VERSION ""

NS_ :

BS_:

BU_: Tester BMS VCU MCU_R MCU_F PDU_DCDC OBC IMM
VAL_TABLE_ TorqBndryETractSys2EmNCtrlMin 4093 "Func_interface_is_not_avail" 4094 "Function_reports_error" 4095 "Signal_unfilled" ;
VAL_TABLE_ TorqBndryETractSys2EmNCtrlMax 4093 "Func_interface_is_not_avail" 4094 "Function_reports_error" 4095 "Signal_unfilled" ;
VAL_TABLE_ TorqBndryETractSys1EmNCtrlMin 4093 "Func_interface_is_not_avail" 4094 "Function_reports_error" 4095 "Signal_unfilled" ;
VAL_TABLE_ TorqBndryETractSys1EmNCtrlMax 4093 "Func_interface_is_not_avail" 4094 "Function_reports_error" 4095 "Signal_unfilled" ;
VAL_TABLE_ QU_CurrDrctCurrETractSys1ActVal 1 "value_valid_highest_quality" 2 "value_valid_simple_quality" 3 "Value_valid_restricted" 4 "Value_valid_substitute value" 6 "value_not_available_error" 9 "value_valid_medium_quality" 14 "value_not_available" 15 "signal_invalid" ;
VAL_TABLE_ QualifierRpmEmETractSys1ActVal 1 "value_valid_highest_quality" 2 "value_valid_simple_quality" 3 "Value_valid_restricted" 4 "Value_valid_substitute value" 6 "value_not_available_error" 9 "value_valid_medium_quality" 14 "value_not_available" 15 "signal_invalid" ;
VAL_TABLE_ QualifierTqEmETractSys1ActVal 1 "value_valid_highest_quality" 2 "value_valid_simple_quality" 3 "Value_valid_restricted" 4 "Value_valid_substitute value" 6 "value_not_available_error" 9 "value_valid_medium_quality" 14 "value_not_available" 15 "signal_invalid" ;
VAL_TABLE_ OVCUrrenceStatorPWMETractSys1 0 "Effective_PWM_applied" 1 "No_effective_PWM_applied" 3 "signal_unfilled" ;
VAL_TABLE_ TqEmETractSys1MotorSumLimTarget 4093 "Func_interface_is_not_avail" 4094 "Function_reports_error" 4095 "Signal_unfilled" ;
VAL_TABLE_ TorqueEmETractSys1MotorDynamic 4093 "Func_interface_is_not_avail" 4094 "Function_reports_error" 4095 "Signal_unfilled" ;
VAL_TABLE_ TorqueEmETractSys1MotorStatic 4093 "Func_interface_is_not_avail" 4094 "Function_reports_error" 4095 "Signal_unfilled" ;
VAL_TABLE_ TqEmETractSys1GeneratorDynamic 4093 "Func_interface_is_not_avail" 4094 "Function_reports_error" 4095 "Signal_unfilled" ;
VAL_TABLE_ TqEmETractSys1GeneratorStatic 4093 "Func_interface_is_not_avail" 4094 "Function_reports_error" 4095 "Signal_unfilled" ;
VAL_TABLE_ TqEmETractSys1VibrationDampSusp 4093 "Func_interface_is_not_avail" 4094 "Function_reports_error" 4095 "Signal_unfilled" ;
VAL_TABLE_ CurrDrctCurrETractSys1ActVal 65533 "Func_interface_is_not_avail" 65534 "Function_reports_error" 65535 "Signal_unfilled" ;
VAL_TABLE_ QualifierRpmEmETractSys2ActVal 1 "value_valid_highest_quality" 2 "value_valid_simple_quality" 3 "Value_valid_restricted" 4 "Value_valid_substitute value" 6 "value_not_available_error" 9 "value_valid_medium_quality" 14 "value_not_available" 15 "signal_invalid" ;
VAL_TABLE_ TqEmETractSys2MotorSumLimTarget 4093 "Func_interface_is_not_avail" 4094 "Function_reports_error" 4095 "Signal_unfilled" ;
VAL_TABLE_ TorqueEmETractSys2MotorDynamic 4093 "Func_interface_is_not_avail" 4094 "Function_reports_error" 4095 "Signal_unfilled" ;
VAL_TABLE_ TqEmETractSys2GeneratorDynamic 4093 "Func_interface_is_not_avail" 4094 "Function_reports_error" 4095 "Signal_unfilled" ;
VAL_TABLE_ TqEmETractSys2GeneratorStatic 4093 "Func_interface_is_not_avail" 4094 "Function_reports_error" 4095 "Signal_unfilled" ;
VAL_TABLE_ TqEmETractSys2VibrationDampSusp 4093 "Func_interface_is_not_avail" 4094 "Function_reports_error" 4095 "Signal_unfilled" ;
VAL_TABLE_ CurrDrctCurrETractSys2ActVal 65533 "Func_interface_is_not_avail" 65534 "Function_reports_error" 65535 "Signal_unfilled" ;
VAL_TABLE_ TorqueEmETractSys2MotorStatic 4093 "Func_interface_is_not_avail" 4094 "Function_reports_error" 4095 "Signal_unfilled" ;
VAL_TABLE_ QualifierTqEmETractSys2ActVal 1 "value_valid_highest_quality" 2 "value_valid_simple_quality" 3 "Value_valid_restricted" 4 "Value_valid_substitute value" 6 "value_not_available_error" 9 "value_valid_medium_quality" 14 "value_not_available" 15 "signal_invalid" ;
VAL_TABLE_ OVCUrrenceStatorPWMETractSys2 0 "Effective_PWM_applied" 1 "No_effective_PWM_applied" 3 "signal_unfilled" ;
VAL_TABLE_ QU_CurrDrctCurrETractSys2ActVal 1 "value_valid_highest_quality" 2 "value_valid_simple_quality" 3 "Value_valid_restricted" 4 "Value_valid_substitute value" 6 "value_not_available_error" 9 "value_valid_medium_quality" 14 "value_not_available" 15 "signal_invalid" ;
VAL_TABLE_ PrcntUsedExtraBoostETractSys1 1021 "Func_interface_is_not_avail" 1022 "Function_reports_error" 1023 "Signal_unfilled" ;
VAL_TABLE_ WhlRatElAxlEtractSys1ActVal 65533 "Func_interface_is_not_avail" 65534 "Function_reports_error" 65535 "signal_unfilled" ;
VAL_TABLE_ WhlRatElAxlEtractSys2ActVal 65533 "Func_interface_is_not_avail" 65534 "Function_reports_error" 65535 "signal_unfilled" ;
VAL_TABLE_ PrcntUsedExtraBoostETractSys2 1021 "Func_interface_is_not_avail" 1022 "Function_reports_error" 1023 "Signal_unfilled" ;

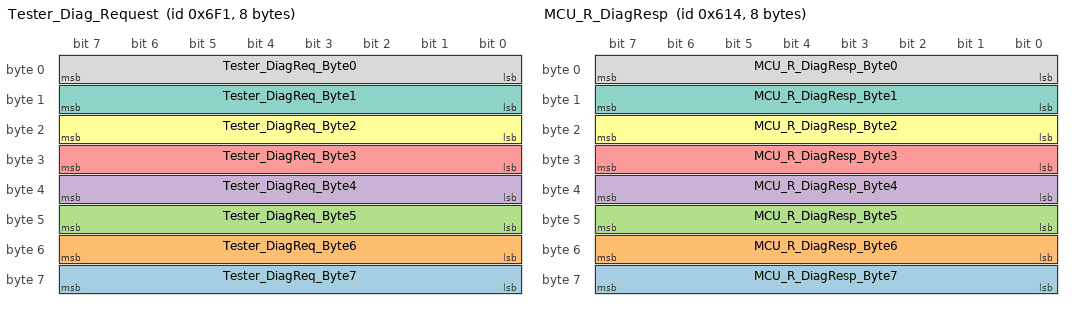
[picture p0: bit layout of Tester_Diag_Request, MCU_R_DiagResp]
BO_ 1777 Tester_Diag_Request: 8 Tester
 SG_ Tester_DiagReq_Byte7 : 56|8@1+ (1,0) [0|255] ""  MCU_R,MCU_F
 SG_ Tester_DiagReq_Byte6 : 48|8@1+ (1,0) [0|255] ""  MCU_R,MCU_F
 SG_ Tester_DiagReq_Byte5 : 40|8@1+ (1,0) [0|255] ""  MCU_R,MCU_F
 SG_ Tester_DiagReq_Byte4 : 32|8@1+ (1,0) [0|255] ""  MCU_R,MCU_F
 SG_ Tester_DiagReq_Byte3 : 24|8@1+ (1,0) [0|255] ""  MCU_R,MCU_F
 SG_ Tester_DiagReq_Byte2 : 16|8@1+ (1,0) [0|255] ""  MCU_R,MCU_F
 SG_ Tester_DiagReq_Byte1 : 8|8@1+ (1,0) [0|255] ""  MCU_R,MCU_F
 SG_ Tester_DiagReq_Byte0 : 0|8@1+ (1,0) [0|255] ""  MCU_R,MCU_F

BO_ 1556 MCU_R_DiagResp: 8 MCU_R
 SG_ MCU_R_DiagResp_Byte7 : 56|8@1+ (1,0) [0|255] ""  Tester
 SG_ MCU_R_DiagResp_Byte6 : 48|8@1+ (1,0) [0|255] ""  Tester
 SG_ MCU_R_DiagResp_Byte5 : 40|8@1+ (1,0) [0|255] ""  Tester
 SG_ MCU_R_DiagResp_Byte4 : 32|8@1+ (1,0) [0|255] ""  Tester
 SG_ MCU_R_DiagResp_Byte3 : 24|8@1+ (1,0) [0|255] ""  Tester
 SG_ MCU_R_DiagResp_Byte2 : 16|8@1+ (1,0) [0|255] ""  Tester
 SG_ MCU_R_DiagResp_Byte1 : 8|8@1+ (1,0) [0|255] ""  Tester
 SG_ MCU_R_DiagResp_Byte0 : 0|8@1+ (1,0) [0|255] ""  Tester

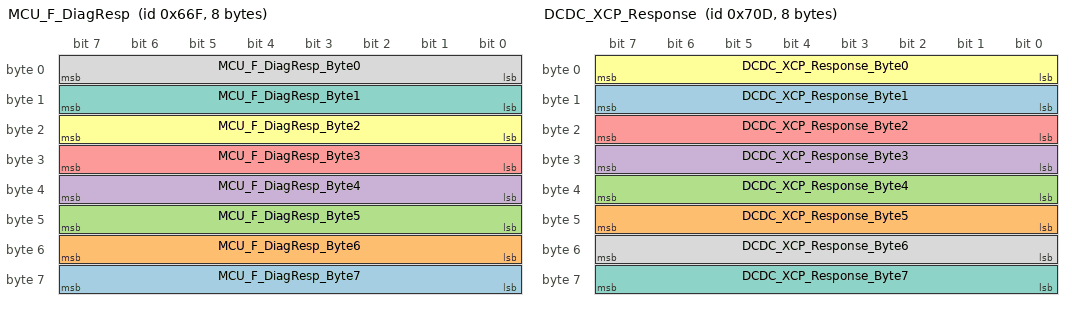
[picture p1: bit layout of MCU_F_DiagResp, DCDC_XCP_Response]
BO_ 1647 MCU_F_DiagResp: 8 MCU_F
 SG_ MCU_F_DiagResp_Byte7 : 56|8@1+ (1,0) [0|255] ""  Tester
 SG_ MCU_F_DiagResp_Byte6 : 48|8@1+ (1,0) [0|255] ""  Tester
 SG_ MCU_F_DiagResp_Byte5 : 40|8@1+ (1,0) [0|255] ""  Tester
 SG_ MCU_F_DiagResp_Byte4 : 32|8@1+ (1,0) [0|255] ""  Tester
 SG_ MCU_F_DiagResp_Byte3 : 24|8@1+ (1,0) [0|255] ""  Tester
 SG_ MCU_F_DiagResp_Byte2 : 16|8@1+ (1,0) [0|255] ""  Tester
 SG_ MCU_F_DiagResp_Byte1 : 8|8@1+ (1,0) [0|255] ""  Tester
 SG_ MCU_F_DiagResp_Byte0 : 0|8@1+ (1,0) [0|255] ""  Tester

BO_ 1805 DCDC_XCP_Response: 8 PDU_DCDC
 SG_ DCDC_XCP_Response_Byte1 : 8|8@1+ (1,0) [0|255] ""  Tester
 SG_ DCDC_XCP_Response_Byte5 : 40|8@1+ (1,0) [0|255] ""  Tester
 SG_ DCDC_XCP_Response_Byte4 : 32|8@1+ (1,0) [0|255] ""  Tester
 SG_ DCDC_XCP_Response_Byte3 : 24|8@1+ (1,0) [0|255] ""  Tester
 SG_ DCDC_XCP_Response_Byte2 : 16|8@1+ (1,0) [0|255] ""  Tester
 SG_ DCDC_XCP_Response_Byte0 : 0|8@1+ (1,0) [0|255] ""  Tester
 SG_ DCDC_XCP_Response_Byte7 : 56|8@1+ (1,0) [0|255] ""  Tester
 SG_ DCDC_XCP_Response_Byte6 : 48|8@1+ (1,0) [0|255] ""  Tester

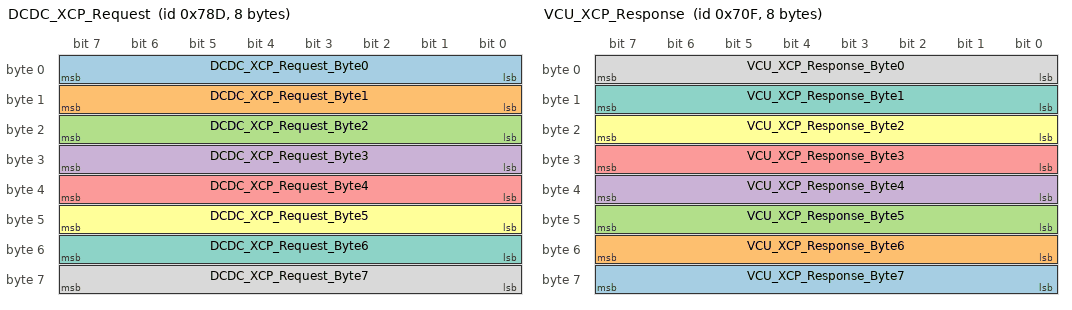
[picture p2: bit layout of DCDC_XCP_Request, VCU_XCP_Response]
BO_ 1933 DCDC_XCP_Request: 8 Tester
 SG_ DCDC_XCP_Request_Byte0 : 0|8@1+ (1,0) [0|255] ""  PDU_DCDC
 SG_ DCDC_XCP_Request_Byte1 : 8|8@1+ (1,0) [0|255] ""  PDU_DCDC
 SG_ DCDC_XCP_Request_Byte2 : 16|8@1+ (1,0) [0|255] ""  PDU_DCDC
 SG_ DCDC_XCP_Request_Byte3 : 24|8@1+ (1,0) [0|255] ""  PDU_DCDC
 SG_ DCDC_XCP_Request_Byte4 : 32|8@1+ (1,0) [0|255] ""  PDU_DCDC
 SG_ DCDC_XCP_Request_Byte5 : 40|8@1+ (1,0) [0|255] ""  PDU_DCDC
 SG_ DCDC_XCP_Request_Byte6 : 48|8@1+ (1,0) [0|255] ""  PDU_DCDC
 SG_ DCDC_XCP_Request_Byte7 : 56|8@1+ (1,0) [0|255] ""  PDU_DCDC

BO_ 1807 VCU_XCP_Response: 8 VCU
 SG_ VCU_XCP_Response_Byte7 : 56|8@1+ (1,0) [0|255] ""  Tester
 SG_ VCU_XCP_Response_Byte6 : 48|8@1+ (1,0) [0|255] ""  Tester
 SG_ VCU_XCP_Response_Byte5 : 40|8@1+ (1,0) [0|255] ""  Tester
 SG_ VCU_XCP_Response_Byte4 : 32|8@1+ (1,0) [0|255] ""  Tester
 SG_ VCU_XCP_Response_Byte3 : 24|8@1+ (1,0) [0|255] ""  Tester
 SG_ VCU_XCP_Response_Byte2 : 16|8@1+ (1,0) [0|255] ""  Tester
 SG_ VCU_XCP_Response_Byte1 : 8|8@1+ (1,0) [0|255] ""  Tester
 SG_ VCU_XCP_Response_Byte0 : 0|8@1+ (1,0) [0|255] ""  Tester

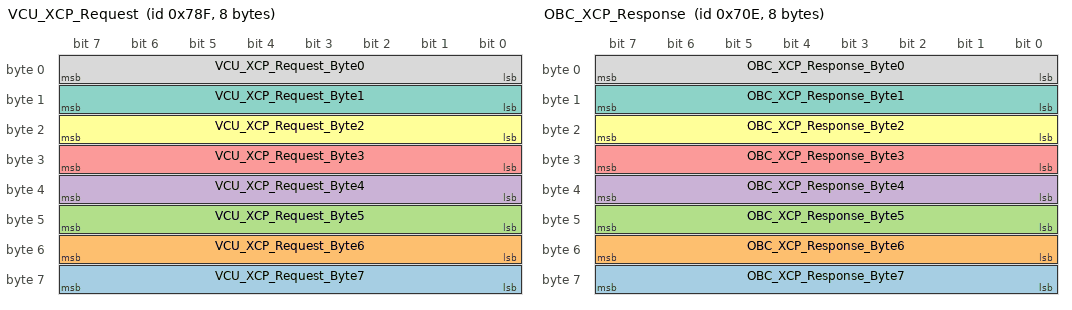
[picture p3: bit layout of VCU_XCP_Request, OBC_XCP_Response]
BO_ 1935 VCU_XCP_Request: 8 Tester
 SG_ VCU_XCP_Request_Byte7 : 56|8@1+ (1,0) [0|255] ""  VCU
 SG_ VCU_XCP_Request_Byte6 : 48|8@1+ (1,0) [0|255] ""  VCU
 SG_ VCU_XCP_Request_Byte5 : 40|8@1+ (1,0) [0|255] ""  VCU
 SG_ VCU_XCP_Request_Byte4 : 32|8@1+ (1,0) [0|255] ""  VCU
 SG_ VCU_XCP_Request_Byte3 : 24|8@1+ (1,0) [0|255] ""  VCU
 SG_ VCU_XCP_Request_Byte2 : 16|8@1+ (1,0) [0|255] ""  VCU
 SG_ VCU_XCP_Request_Byte1 : 8|8@1+ (1,0) [0|255] ""  VCU
 SG_ VCU_XCP_Request_Byte0 : 0|8@1+ (1,0) [0|255] ""  VCU

BO_ 1806 OBC_XCP_Response: 8 OBC
 SG_ OBC_XCP_Response_Byte7 : 56|8@1+ (1,0) [0|255] ""  Tester
 SG_ OBC_XCP_Response_Byte6 : 48|8@1+ (1,0) [0|255] ""  Tester
 SG_ OBC_XCP_Response_Byte5 : 40|8@1+ (1,0) [0|255] ""  Tester
 SG_ OBC_XCP_Response_Byte4 : 32|8@1+ (1,0) [0|255] ""  Tester
 SG_ OBC_XCP_Response_Byte3 : 24|8@1+ (1,0) [0|255] ""  Tester
 SG_ OBC_XCP_Response_Byte2 : 16|8@1+ (1,0) [0|255] ""  Tester
 SG_ OBC_XCP_Response_Byte1 : 8|8@1+ (1,0) [0|255] ""  Tester
 SG_ OBC_XCP_Response_Byte0 : 0|8@1+ (1,0) [0|255] ""  Tester

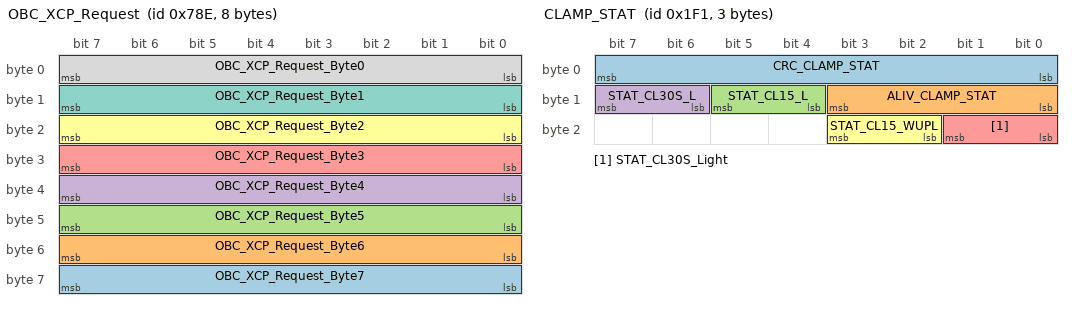
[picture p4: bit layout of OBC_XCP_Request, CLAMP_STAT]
BO_ 1934 OBC_XCP_Request: 8 Tester
 SG_ OBC_XCP_Request_Byte7 : 56|8@1+ (1,0) [0|255] ""  OBC
 SG_ OBC_XCP_Request_Byte6 : 48|8@1+ (1,0) [0|255] ""  OBC
 SG_ OBC_XCP_Request_Byte5 : 40|8@1+ (1,0) [0|255] ""  OBC
 SG_ OBC_XCP_Request_Byte4 : 32|8@1+ (1,0) [0|255] ""  OBC
 SG_ OBC_XCP_Request_Byte3 : 24|8@1+ (1,0) [0|255] ""  OBC
 SG_ OBC_XCP_Request_Byte2 : 16|8@1+ (1,0) [0|255] ""  OBC
 SG_ OBC_XCP_Request_Byte1 : 8|8@1+ (1,0) [0|255] ""  OBC
 SG_ OBC_XCP_Request_Byte0 : 0|8@1+ (1,0) [0|255] ""  OBC

BO_ 501 VCU_HV_DrvSys_status: 1 VCU
 SG_ VCU_HV_SystemStatus : 0|3@1+ (1,0) [0|7] ""  PDU_DCDC,OBC

BO_ 451 VCU_Thermal_Status: 1 VCU
 SG_ VCU_LTROutLetTemp : 0|8@1+ (1,-50) [-50|205] ""  PDU_DCDC,OBC

BO_ 411 OBC_01_100ms: 2 OBC
 SG_ OBC_SeqSta : 8|8@1+ (1,0) [0|255] ""  VCU
 SG_ OBC_HvIntlkStatus : 0|2@1+ (1,0) [0|3] ""  VCU

BO_ 634 DCDC_01_100ms: 2 PDU_DCDC
 SG_ DCDC_SysOpSta : 8|8@1+ (1,0) [0|255] ""  VCU
 SG_ DCDC_HvIntlkStatus : 0|2@1+ (1,0) [0|3] ""  VCU

BO_ 395 BMS_CellTempMeas2: 12 BMS
 SG_ BMS_CellTemp48 : 84|12@1+ (0.1,-40) [-40|215] "°C"  VCU
 SG_ BMS_CellTemp47 : 72|12@1+ (0.1,-40) [-40|215] "°C"  VCU
 SG_ BMS_CellTemp46 : 60|12@1+ (0.1,-40) [-40|215] "°C"  VCU
 SG_ BMS_CellTemp45 : 48|12@1+ (0.1,-40) [-40|215] "°C"  VCU
 SG_ BMS_CellTemp44 : 36|12@1+ (0.1,-40) [-40|215] "°C"  VCU
 SG_ BMS_CellTemp43 : 24|12@1+ (0.1,-40) [-40|215] "°C"  VCU
 SG_ BMS_CellTemp42 : 12|12@1+ (0.1,-40) [-40|215] "°C"  VCU
 SG_ CRC_BMS_CellTempMeas2 : 0|8@1+ (1,0) [0|255] ""  VCU
 SG_ ALV_BMS_CellTempMeas2 : 8|4@1+ (1,0) [0|14] ""  VCU

BO_ 497 CLAMP_STAT: 3 VCU
 SG_ CRC_CLAMP_STAT : 0|8@1+ (1,0) [0|255] ""  BMS,MCU_R,MCU_F,PDU_DCDC,OBC
 SG_ ALIV_CLAMP_STAT : 8|4@1+ (1,0) [0|14] ""  BMS,MCU_R,MCU_F,PDU_DCDC,OBC
 SG_ STAT_CL15_L : 12|2@1+ (1,0) [0|3] ""  BMS,MCU_R,MCU_F,PDU_DCDC,OBC
 SG_ STAT_CL30S_L : 14|2@1+ (1,0) [0|3] ""  BMS,MCU_R,MCU_F,PDU_DCDC,OBC
 SG_ STAT_CL30S_Light : 16|2@1+ (1,0) [0|3] ""  BMS,MCU_R,MCU_F,PDU_DCDC,OBC
 SG_ STAT_CL15_WUPL : 18|2@1+ (1,0) [0|3] ""  BMS,MCU_R,MCU_F,PDU_DCDC,OBC

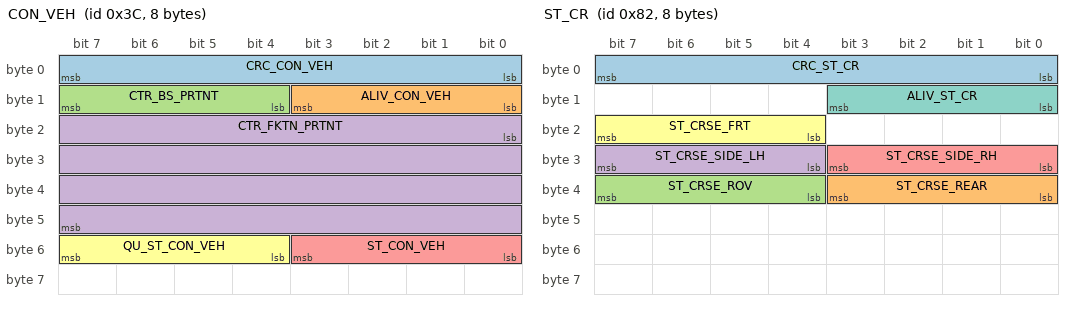
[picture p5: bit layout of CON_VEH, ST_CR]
BO_ 60 CON_VEH: 8 VCU
 SG_ CRC_CON_VEH : 0|8@1+ (1,0) [0|255] ""  MCU_R,MCU_F
 SG_ ALIV_CON_VEH : 8|4@1+ (1,0) [0|14] ""  MCU_R,MCU_F
 SG_ CTR_BS_PRTNT : 12|4@1+ (1,0) [0|15] ""  MCU_R,MCU_F
 SG_ CTR_FKTN_PRTNT : 16|32@1+ (1,0) [0|4294967295] ""  MCU_R,MCU_F
 SG_ ST_CON_VEH : 48|4@1+ (1,0) [0|15] ""  MCU_R,MCU_F
 SG_ QU_ST_CON_VEH : 52|4@1+ (1,0) [2|15] ""  MCU_R,MCU_F

BO_ 130 ST_CR: 8 VCU
 SG_ CRC_ST_CR : 0|8@1+ (1,0) [0|255] ""  BMS,MCU_R,MCU_F
 SG_ ST_CRSE_REAR : 32|4@1+ (1,0) [0|15] ""  BMS,MCU_R,MCU_F
 SG_ ST_CRSE_ROV : 36|4@1+ (1,0) [0|15] ""  BMS,MCU_R,MCU_F
 SG_ ST_CRSE_SIDE_LH : 28|4@1+ (1,0) [0|15] ""  BMS,MCU_R,MCU_F
 SG_ ST_CRSE_SIDE_RH : 24|4@1+ (1,0) [0|15] ""  BMS,MCU_R,MCU_F
 SG_ ST_CRSE_FRT : 20|4@1+ (1,0) [0|15] ""  BMS,MCU_R,MCU_F
 SG_ ALIV_ST_CR : 8|4@1+ (1,0) [0|14] ""  BMS,MCU_R,MCU_F

BO_ 131 AVL_RPM_WHL: 12 VCU
 SG_ CRC_AVL_RPM_WHL : 0|8@1+ (1,0) [0|255] ""  MCU_R,MCU_F
 SG_ ALIV_AVL_RPM_WHL : 8|4@1+ (1,0) [0|14] ""  MCU_R,MCU_F
 SG_ AVL_RPM_WHL_RLH : 16|16@1+ (0.015625,-511.984375) [-400|512] "rad/s"  MCU_R,MCU_F
 SG_ AVL_RPM_WHL_RRH : 32|16@1+ (0.015625,-511.984375) [-400|512] "rad/s"  MCU_R,MCU_F
 SG_ AVL_RPM_WHL_FLH : 48|16@1+ (0.015625,-511.984375) [-400|512] "rad/s"  MCU_R,MCU_F
 SG_ AVL_RPM_WHL_FRH : 64|16@1+ (0.015625,-511.984375) [-400|512] "rad/s"  MCU_R,MCU_F
 SG_ QU_AVL_RPM_WHL_RLH : 80|4@1+ (1,0) [1|15] ""  MCU_R,MCU_F
 SG_ QU_AVL_RPM_WHL_RRH : 84|4@1+ (1,0) [1|15] ""  MCU_R,MCU_F
 SG_ QU_AVL_RPM_WHL_FLH : 88|4@1+ (1,0) [1|15] ""  MCU_R,MCU_F
 SG_ QU_AVL_RPM_WHL_FRH : 92|4@1+ (1,0) [1|15] ""  MCU_R,MCU_F

BO_ 132 BMS_ChgParamReq: 32 BMS
 SG_ BMS_MaxChgCurrent10s : 112|16@1+ (0.1,0) [0|1500] "A"  VCU
 SG_ CRC_BMS_ChgParamReq : 0|8@1+ (1,0) [0|255] ""  VCU
 SG_ BMS_MaxChgCurrent2s : 96|16@1+ (0.1,0) [0|1500] "A"  VCU
 SG_ BMS_ChgVoltageReq : 16|16@1+ (0.1,0) [0|600] "V"  VCU
 SG_ ALV_BMS_ChgParamReq : 8|4@1+ (1,0) [0|14] ""  VCU
 SG_ BMS_RemainChargeTime : 48|12@1+ (1,0) [0|1500] "min"  VCU
 SG_ BMS_ChargeStopReq : 12|2@1+ (1,0) [0|3] ""  VCU
 SG_ BMS_MaxChgPwr30s : 208|16@1+ (0.1,0) [0|800] "kW"  VCU
 SG_ BMS_MaxChgPwr10s : 192|16@1+ (0.1,0) [0|800] "kW"  VCU
 SG_ BMS_MaxChgPwr2s : 176|16@1+ (0.1,0) [0|800] "kW"  VCU
 SG_ BMS_MaxChgCurrentLim : 64|16@1+ (0.1,0) [0|1500] "A"  VCU
 SG_ BMS_MaxChgCurrent30s : 128|16@1+ (0.1,0) [0|1500] "A"  VCU
 SG_ BMS_ChgCurrentReq : 32|16@1+ (0.1,0) [0|1500] "A"  VCU
 SG_ BMS_MaxChgPwrLim : 144|16@1+ (0.1,0) [0|800] "kW"  VCU
 SG_ BMS_MaxChgCurrentLimPeak : 80|16@1+ (0.1,0) [0|1500] "A"  VCU
 SG_ BMS_MaxChgPwrLimPeak : 160|16@1+ (0.1,0) [0|800] "kW"  VCU

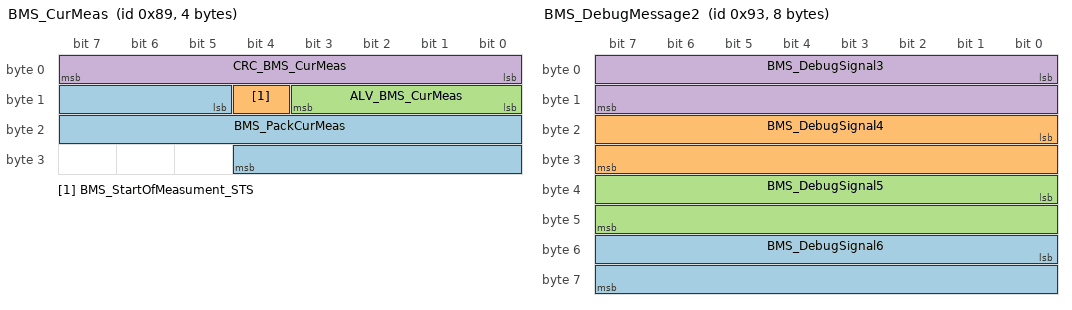
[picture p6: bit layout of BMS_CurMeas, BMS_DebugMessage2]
BO_ 137 BMS_CurMeas: 4 BMS
 SG_ BMS_PackCurMeas : 13|16@1+ (0.1,-1500) [-1500|1500] "A"  VCU
 SG_ BMS_StartOfMeasument_STS : 12|1@1+ (1,0) [0|1] ""  VCU
 SG_ ALV_BMS_CurMeas : 8|4@1+ (1,0) [0|14] ""  VCU
 SG_ CRC_BMS_CurMeas : 0|8@1+ (1,0) [0|255] ""  VCU

BO_ 138 CombinedChargerUnit10msNo3: 12 VCU
 SG_ OperatingModeETract1Target : 72|8@1+ (1,0) [0|255] ""  MCU_R,MCU_F
 SG_ ALIV_CombinedChargerUnit10msNo3 : 16|8@1+ (1,0) [0|254] ""  MCU_R,MCU_F
 SG_ CRC_CombinedChargerUnit10msNo3 : 0|16@1+ (1,0) [0|65535] ""  MCU_R,MCU_F
 SG_ OperatingModeETract2Target : 80|8@1+ (1,0) [0|255] ""  MCU_R,MCU_F

BO_ 141 CombinedChargerUnit10msNo1: 32 VCU
 SG_ SecOcDtP2CmbdChrgUnit10msNo1_3 : 208|16@1+ (1,0) [0|65535] "" Vector__XXX
 SG_ SecOcDtP2CmbdChrgUnit10msNo1_2 : 160|16@1+ (1,0) [0|65535] "" Vector__XXX
 SG_ SecOcDtP2CmbdChrgUnit10msNo1_1 : 112|16@1+ (1,0) [0|65535] "" Vector__XXX
 SG_ TargetEMRpmETractSys2 : 144|16@1+ (1,-32768) [-32768|32767] "1/min"  MCU_R,MCU_F
 SG_ StatusReleaseTorqueVerified : 184|4@1+ (1,0) [0|15] ""  MCU_R,MCU_F
 SG_ SecOcDtP2CmbdChrgUnit10msNo1_0 : 192|16@1+ (1,0) [0|65535] ""  MCU_R,MCU_F
 SG_ StatusDampingVibration : 96|4@1+ (1,0) [0|15] ""  MCU_R,MCU_F
 SG_ TorqBoundaryETractSys2EmNCtrlMin : 84|12@1+ (0.5,-1023) [-1023|1024.5] "Nm"  MCU_R,MCU_F
 SG_ TorqBoundaryETractSys2EmNCtrlMax : 72|12@1+ (0.5,-1023) [-1023|1024.5] "Nm"  MCU_R,MCU_F
 SG_ TorqBoundaryETractSys1EmNCtrlMin : 60|12@1+ (0.5,-1023) [-1023|1024.5] "Nm"  MCU_R,MCU_F
 SG_ TorqBoundaryETractSys1EmNCtrlMax : 48|12@1+ (0.5,-1023) [-1023|1024.5] "Nm"  MCU_R,MCU_F
 SG_ TargetTorqueEmETractSys2 : 36|12@1+ (0.5,-1023) [-1023|1024.5] "Nm"  MCU_R,MCU_F
 SG_ TargetEMRpmETractSys1 : 128|16@1+ (1,-32768) [-32768|32767] "1/min"  MCU_R,MCU_F
 SG_ TargetTorqueEmETractSys1 : 24|12@1+ (0.5,-1023) [-1023|1024.5] "Nm"  MCU_R,MCU_F
 SG_ CRC_CombinedChargerUnit10msNo1 : 0|16@1+ (1,0) [0|65535] ""  MCU_R,MCU_F
 SG_ ALIV_CombinedChargerUnit10msNo1 : 16|8@1+ (1,0) [0|254] ""  MCU_R,MCU_F

BO_ 142 BMS_DebugMessage1: 8 BMS
 SG_ BMS_DebugSignal2 : 32|32@1+ (1,0) [0|0] ""  Tester
 SG_ BMS_DebugSignal1 : 0|32@1+ (1,0) [0|0] ""  Tester

BO_ 143 HighVoltageStorage10msNo2: 48 BMS
 SG_ CRC_HighVoltageStorage10msNo2 : 256|16@1+ (1,0) [0|65535] ""  VCU,MCU_R,MCU_F
 SG_ ALIV_HighVoltageStorage10msNo2 : 272|8@1+ (1,0) [0|254] ""  VCU,MCU_R,MCU_F
 SG_ ActualValueVoltageLinkVerified : 296|12@1+ (0.25,0) [0|1023.75] "V"  VCU,MCU_R,MCU_F

BO_ 145 TracEMacElectc1Time10msNo1: 48 MCU_R
 SG_ ALIV_TracEMacElectc1Time10msNo1 : 16|8@1+ (1,0) [0|254] ""  VCU,BMS
 SG_ PwrLossPrednETractSys1Genr : 332|12@1+ (50,0) [0|204750] "W"  VCU
 SG_ PwrLossPrednETractSys1Mot : 320|12@1+ (50,0) [0|204750] "W"  VCU
 SG_ TarTqETractSys1NControlStatic : 300|10@1+ (1,-510) [-510|513] "Nm"  VCU
 SG_ PowerETractSys1LossActualValue : 288|12@1+ (50,0) [0|204750] "W"  VCU
 SG_ StETractSys1Asd : 272|16@1+ (1,0) [0|65535] ""  VCU
 SG_ SumWhlTqIntvETractSys1 : 256|12@1+ (10,0) [0|40950] "Nm"  VCU
 SG_ StatusArbRpmETractSys1Limit : 244|4@1+ (1,0) [0|15] ""  VCU
 SG_ Qu_CurrDrctCurrETractSys1ActVal : 240|4@1+ (1,0) [1|15] ""  VCU,BMS
 SG_ QualifierRpmEmETractSys1ActVal : 236|4@1+ (1,0) [1|15] ""  VCU
 SG_ QualifierTqEmETractSys1ActVal : 232|4@1+ (1,0) [1|15] ""  VCU
 SG_ StatusPbWETractSys1 : 224|8@1+ (1,0) [0|255] ""  VCU
 SG_ CRC_TracEMacElectc1Time10msNo1 : 0|16@1+ (1,0) [0|65535] ""  VCU,BMS
 SG_ OVCUrrenceStatorPWMETractSys1 : 206|2@1+ (1,0) [0|3] ""  VCU,BMS
 SG_ TqEmETractSys1MotorSumLimTarget : 192|12@1+ (0.5,-1023) [-1023|1024.5] "Nm"  VCU
 SG_ TorqueEmETractSys1ActualValue : 176|12@1+ (0.5,-1023) [-1023|1024.5] "Nm"  VCU
 SG_ TorqueEmETractSys1MotorDynamic : 164|12@1+ (0.5,-1023) [-1023|1024.5] "Nm"  VCU
 SG_ TorqueEmETractSys1MotorStatic : 152|12@1+ (0.5,-1023) [-1023|1024.5] "Nm"  VCU
 SG_ TqEmETractSys1GeneratorDynamic : 140|12@1+ (0.5,-1023) [-1023|1024.5] "Nm"  VCU
 SG_ TqEmETractSys1GeneratorStatic : 128|12@1+ (0.5,-1023) [-1023|1024.5] "Nm"  VCU
 SG_ RpmEmETractSys1ActualValue : 112|16@1+ (1,-32768) [-32768|32767] "1/min"  VCU
 SG_ TqEmETractSys1VibrationDampSusp : 84|12@1+ (0.5,-1023) [-1023|1024.5] "Nm"  VCU
 SG_ RpmEmETractSys1MinimumLimit : 68|16@1+ (1,-32768) [-32768|32767] "1/min"  VCU
 SG_ RpmEmETractSys1MaximumLimit : 52|16@1+ (1,-32768) [-32768|32767] "1/min"  VCU
 SG_ VolDrctCurrETractSys1ActVal : 40|12@1+ (0.5,0) [0|2047.5] "V"  VCU,BMS
 SG_ CurrDrctCurrETractSys1ActVal : 24|16@1+ (0.1,-1400) [-1400|5153.5] "A"  VCU,BMS
 SG_ DirOfRotETractSys1ActVal : 204|2@1+ (1,0) [0|3] ""  VCU
 SG_ StatusLockPositionPbWETractSys1 : 188|4@1+ (1,0) [0|15] ""  VCU

BO_ 146 ERRM_BN_U: 2 VCU
 SG_ CTR_ERRM_BN_U : 0|6@1+ (1,0) [0|63] ""  MCU_R,MCU_F

BO_ 147 BMS_DebugMessage2: 8 BMS
 SG_ BMS_DebugSignal6 : 48|16@1+ (1,0) [0|0] ""  Tester
 SG_ BMS_DebugSignal4 : 16|16@1+ (1,0) [0|0] ""  Tester
 SG_ BMS_DebugSignal5 : 32|16@1+ (1,0) [0|0] ""  Tester
 SG_ BMS_DebugSignal3 : 0|16@1+ (1,0) [0|0] ""  Tester

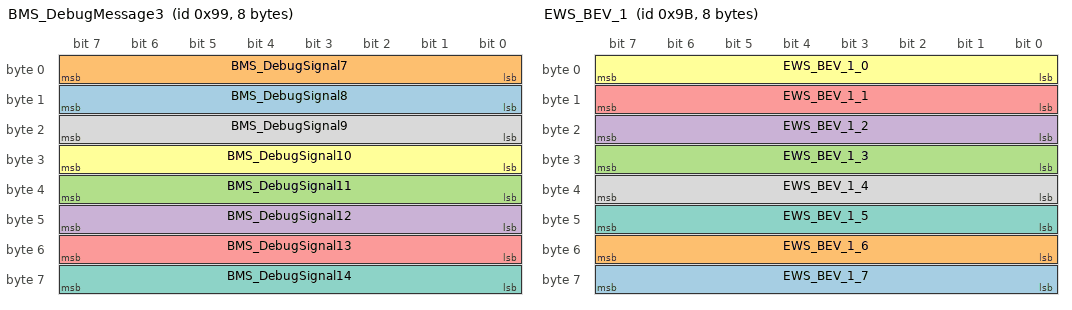
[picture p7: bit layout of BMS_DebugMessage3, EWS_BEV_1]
BO_ 153 BMS_DebugMessage3: 8 BMS
 SG_ BMS_DebugSignal8 : 8|8@1+ (1,0) [0|0] ""  Tester
 SG_ BMS_DebugSignal7 : 0|8@1+ (1,0) [0|0] ""  Tester
 SG_ BMS_DebugSignal11 : 32|8@1+ (1,0) [0|0] ""  Tester
 SG_ BMS_DebugSignal12 : 40|8@1+ (1,0) [0|0] ""  Tester
 SG_ BMS_DebugSignal13 : 48|8@1+ (1,0) [0|0] ""  Tester
 SG_ BMS_DebugSignal10 : 24|8@1+ (1,0) [0|0] ""  Tester
 SG_ BMS_DebugSignal14 : 56|8@1+ (1,0) [0|0] ""  Tester
 SG_ BMS_DebugSignal9 : 16|8@1+ (1,0) [0|0] ""  Tester

BO_ 155 EWS_BEV_1: 8 MCU_R
 SG_ EWS_BEV_1_7 : 56|8@1+ (1,0) [0|255] ""  IMM
 SG_ EWS_BEV_1_6 : 48|8@1+ (1,0) [0|255] ""  IMM
 SG_ EWS_BEV_1_3 : 24|8@1+ (1,0) [0|255] ""  IMM
 SG_ EWS_BEV_1_2 : 16|8@1+ (1,0) [0|255] ""  IMM
 SG_ EWS_BEV_1_1 : 8|8@1+ (1,0) [0|255] ""  IMM
 SG_ EWS_BEV_1_0 : 0|8@1+ (1,0) [0|255] ""  IMM
 SG_ EWS_BEV_1_5 : 40|8@1+ (1,0) [0|255] ""  IMM
 SG_ EWS_BEV_1_4 : 32|8@1+ (1,0) [0|255] ""  IMM

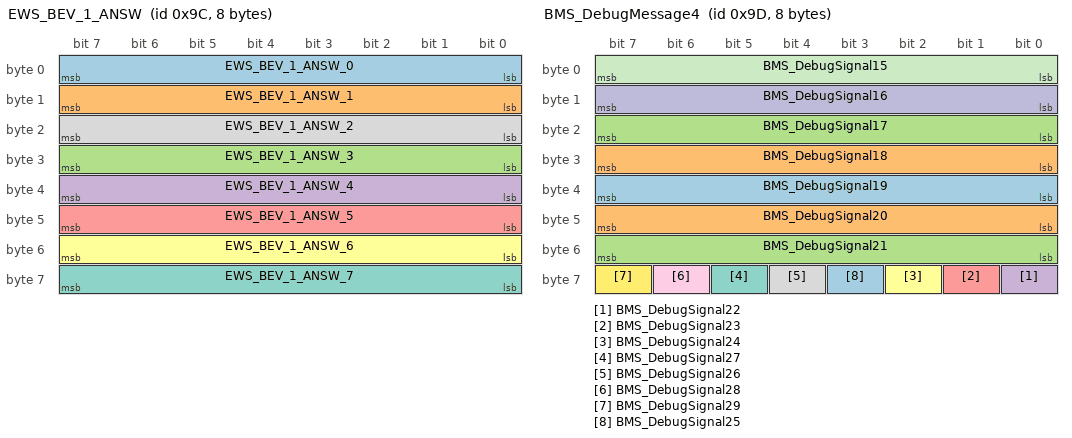
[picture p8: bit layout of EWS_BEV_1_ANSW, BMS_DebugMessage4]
BO_ 156 EWS_BEV_1_ANSW: 8 IMM
 SG_ EWS_BEV_1_ANSW_0 : 0|8@1+ (1,0) [0|255] ""  MCU_R
 SG_ EWS_BEV_1_ANSW_1 : 8|8@1+ (1,0) [0|255] ""  MCU_R
 SG_ EWS_BEV_1_ANSW_3 : 24|8@1+ (1,0) [0|255] ""  MCU_R
 SG_ EWS_BEV_1_ANSW_4 : 32|8@1+ (1,0) [0|255] ""  MCU_R
 SG_ EWS_BEV_1_ANSW_5 : 40|8@1+ (1,0) [0|255] ""  MCU_R
 SG_ EWS_BEV_1_ANSW_6 : 48|8@1+ (1,0) [0|255] ""  MCU_R
 SG_ EWS_BEV_1_ANSW_7 : 56|8@1+ (1,0) [0|255] ""  MCU_R
 SG_ EWS_BEV_1_ANSW_2 : 16|8@1+ (1,0) [0|255] ""  MCU_R

BO_ 157 BMS_DebugMessage4: 8 BMS
 SG_ BMS_DebugSignal19 : 32|8@1+ (1,0) [0|0] ""  Tester
 SG_ BMS_DebugSignal20 : 40|8@1+ (1,0) [0|0] ""  Tester
 SG_ BMS_DebugSignal21 : 48|8@1+ (1,0) [0|0] ""  Tester
 SG_ BMS_DebugSignal22 : 56|1@1+ (1,0) [0|0] ""  Tester
 SG_ BMS_DebugSignal23 : 57|1@1+ (1,0) [0|0] ""  Tester
 SG_ BMS_DebugSignal24 : 58|1@1+ (1,0) [0|0] ""  Tester
 SG_ BMS_DebugSignal27 : 61|1@1+ (1,0) [0|0] ""  Tester
 SG_ BMS_DebugSignal26 : 60|1@1+ (1,0) [0|0] ""  Tester
 SG_ BMS_DebugSignal28 : 62|1@1+ (1,0) [0|0] ""  Tester
 SG_ BMS_DebugSignal16 : 8|8@1+ (1,0) [0|0] ""  Tester
 SG_ BMS_DebugSignal15 : 0|8@1+ (1,0) [0|0] ""  Tester
 SG_ BMS_DebugSignal29 : 63|1@1+ (1,0) [0|0] ""  Tester
 SG_ BMS_DebugSignal25 : 59|1@1+ (1,0) [0|0] ""  Tester
 SG_ BMS_DebugSignal18 : 24|8@1+ (1,0) [0|0] ""  Tester
 SG_ BMS_DebugSignal17 : 16|8@1+ (1,0) [0|0] ""  Tester

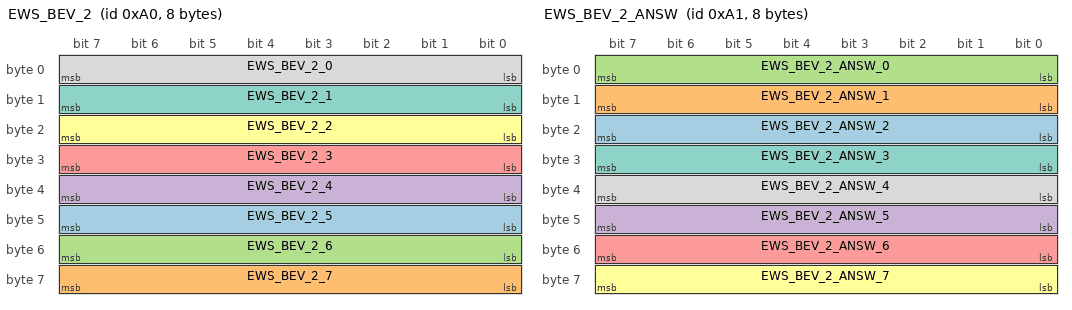
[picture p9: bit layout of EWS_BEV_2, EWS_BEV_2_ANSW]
BO_ 160 EWS_BEV_2: 8 MCU_F
 SG_ EWS_BEV_2_5 : 40|8@1+ (1,0) [0|255] ""  IMM
 SG_ EWS_BEV_2_7 : 56|8@1+ (1,0) [0|255] ""  IMM
 SG_ EWS_BEV_2_6 : 48|8@1+ (1,0) [0|255] ""  IMM
 SG_ EWS_BEV_2_4 : 32|8@1+ (1,0) [0|255] ""  IMM
 SG_ EWS_BEV_2_3 : 24|8@1+ (1,0) [0|255] ""  IMM
 SG_ EWS_BEV_2_2 : 16|8@1+ (1,0) [0|255] ""  IMM
 SG_ EWS_BEV_2_1 : 8|8@1+ (1,0) [0|255] ""  IMM
 SG_ EWS_BEV_2_0 : 0|8@1+ (1,0) [0|255] ""  IMM

BO_ 161 EWS_BEV_2_ANSW: 8 IMM
 SG_ EWS_BEV_2_ANSW_2 : 16|8@1+ (1,0) [0|255] ""  MCU_F
 SG_ EWS_BEV_2_ANSW_1 : 8|8@1+ (1,0) [0|255] ""  MCU_F
 SG_ EWS_BEV_2_ANSW_0 : 0|8@1+ (1,0) [0|255] ""  MCU_F
 SG_ EWS_BEV_2_ANSW_5 : 40|8@1+ (1,0) [0|255] ""  MCU_F
 SG_ EWS_BEV_2_ANSW_6 : 48|8@1+ (1,0) [0|255] ""  MCU_F
 SG_ EWS_BEV_2_ANSW_7 : 56|8@1+ (1,0) [0|255] ""  MCU_F
 SG_ EWS_BEV_2_ANSW_3 : 24|8@1+ (1,0) [0|255] ""  MCU_F
 SG_ EWS_BEV_2_ANSW_4 : 32|8@1+ (1,0) [0|255] ""  MCU_F

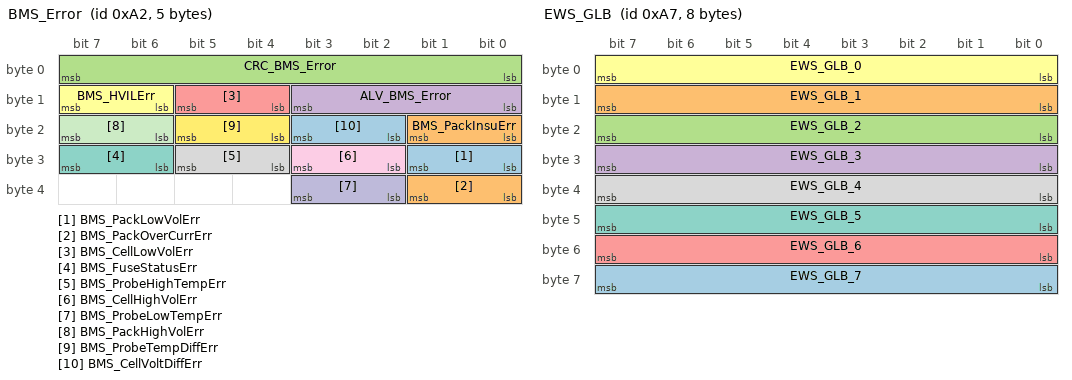
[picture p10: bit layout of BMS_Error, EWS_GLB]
BO_ 162 BMS_Error: 5 BMS
 SG_ BMS_PackLowVolErr : 24|2@1+ (1,0) [0|3] ""  VCU
 SG_ BMS_PackOverCurrErr : 32|2@1+ (1,0) [0|3] ""  VCU
 SG_ CRC_BMS_Error : 0|8@1+ (1,0) [0|255] ""  VCU
 SG_ ALV_BMS_Error : 8|4@1+ (1,0) [0|14] ""  VCU
 SG_ BMS_CellLowVolErr : 12|2@1+ (1,0) [0|3] ""  VCU
 SG_ BMS_HVILErr : 14|2@1+ (1,0) [0|3] ""  VCU
 SG_ BMS_FuseStatusErr : 30|2@1+ (1,0) [0|1] ""  VCU
 SG_ BMS_ProbeHighTempErr : 28|2@1+ (1,0) [0|3] ""  VCU
 SG_ BMS_CellHighVolErr : 26|2@1+ (1,0) [0|3] ""  VCU
 SG_ BMS_ProbeLowTempErr : 34|2@1+ (1,0) [0|3] ""  VCU
 SG_ BMS_PackHighVolErr : 22|2@1+ (1,0) [0|3] ""  VCU
 SG_ BMS_ProbeTempDiffErr : 20|2@1+ (1,0) [0|3] ""  VCU
 SG_ BMS_CellVoltDiffErr : 18|2@1+ (1,0) [0|3] ""  VCU
 SG_ BMS_PackInsuErr : 16|2@1+ (1,0) [0|3] ""  VCU

BO_ 166 WMOM_DRV_9: 48 VCU
 SG_ CHL_WMOM_DRV_9 : 268|4@1+ (1,0) [0|15] ""  MCU_F,MCU_R
 SG_ ALIV_WMOM_DRV_9 : 264|4@1+ (1,0) [0|14] ""  MCU_F,MCU_R
 SG_ CRC_WMOM_DRV_9 : 256|8@1+ (1,0) [0|255] ""  MCU_F,MCU_R
 SG_ TAR_WMOM_PT_SUM_COOTD : 344|16@1+ (1,-32000) [-32000|33535] "Nm"  MCU_R,MCU_F

BO_ 167 EWS_GLB: 8 IMM
 SG_ EWS_GLB_7 : 56|8@1+ (1,0) [0|255] ""  MCU_R,MCU_F
 SG_ EWS_GLB_1 : 8|8@1+ (1,0) [0|255] ""  MCU_R,MCU_F
 SG_ EWS_GLB_2 : 16|8@1+ (1,0) [0|255] ""  MCU_R,MCU_F
 SG_ EWS_GLB_3 : 24|8@1+ (1,0) [0|255] ""  MCU_R,MCU_F
 SG_ EWS_GLB_6 : 48|8@1+ (1,0) [0|255] ""  MCU_R,MCU_F
 SG_ EWS_GLB_0 : 0|8@1+ (1,0) [0|255] ""  MCU_R,MCU_F
 SG_ EWS_GLB_5 : 40|8@1+ (1,0) [0|255] ""  MCU_R,MCU_F
 SG_ EWS_GLB_4 : 32|8@1+ (1,0) [0|255] ""  MCU_R,MCU_F

BO_ 168 BMS_HVMeas: 12 BMS
 SG_ CRC_BMS_HVMeas : 0|8@1+ (1,0) [0|255] ""  VCU
 SG_ ALV_BMS_HVMeas : 8|4@1+ (1,0) [0|14] ""  VCU
 SG_ BMS_HVPackVol : 16|16@1+ (0.1,0) [0|600] "V"  VCU
 SG_ BMS_HVLinkVol : 32|16@1+ (0.1,0) [0|600] "V"  VCU
 SG_ BMS_HVBusVol : 48|16@1+ (0.1,0) [0|600] "V"  VCU
 SG_ BMS_HVFuseVol : 64|16@1+ (0.1,0) [0|600] "V"  VCU
 SG_ BMS_DCPlugVol : 80|16@1+ (0.1,0) [0|600] "V"  VCU

BO_ 170 TracEMacElectc2Time10msNo1: 48 MCU_F
 SG_ QualifierRpmEmETractSys2ActVal : 236|4@1+ (1,0) [1|15] ""  VCU
 SG_ DirOfRotETractSys2ActVal : 204|2@1+ (1,0) [0|3] ""  VCU
 SG_ TqEmETractSys2MotorSumLimTarget : 192|12@1+ (0.5,-1023) [-1023|1024.5] "Nm"  VCU
 SG_ StatusLockPositionPbWETractSys2 : 188|4@1+ (1,0) [0|15] ""  VCU
 SG_ TorqueEmETractSys2ActualValue : 176|12@1+ (0.5,-1023) [-1023|1024.5] "Nm"  VCU
 SG_ TorqueEmETractSys2MotorDynamic : 164|12@1+ (0.5,-1023) [-1023|1024.5] "Nm"  VCU
 SG_ TqEmETractSys2GeneratorDynamic : 140|12@1+ (0.5,-1023) [-1023|1024.5] "Nm"  VCU
 SG_ TqEmETractSys2GeneratorStatic : 128|12@1+ (0.5,-1023) [-1023|1024.5] "Nm"  VCU
 SG_ RpmEmETractSys2ActualValue : 112|16@1+ (1,-32768) [-32768|32767] "1/min"  VCU
 SG_ TqEmETractSys2VibrationDampSusp : 84|12@1+ (0.5,-1023) [-1023|1024.5] "Nm"  VCU
 SG_ RpmEmETractSys2MinimumLimit : 68|16@1+ (1,-32768) [-32768|32767] "1/min"  VCU
 SG_ RpmEmETractSys2MaximumLimit : 52|16@1+ (1,-32768) [-32768|32767] "1/min"  VCU
 SG_ VolDrctCurrETractSys2ActVal : 40|12@1+ (0.5,0) [0|2047.5] "V"  VCU
 SG_ CurrDrctCurrETractSys2ActVal : 24|16@1+ (0.1,-1400) [-1400|5153.5] "A"  VCU
 SG_ ALIV_TracEMacElectc2Time10msNo1 : 16|8@1+ (1,0) [0|254] ""  VCU
 SG_ CRC_TracEMacElectc2Time10msNo1 : 0|16@1+ (1,0) [0|65535] ""  VCU
 SG_ TorqueEmETractSys2MotorStatic : 152|12@1+ (0.5,-1023) [-1023|1024.5] "Nm"  VCU
 SG_ QualifierTqEmETractSys2ActVal : 232|4@1+ (1,0) [1|15] ""  VCU
 SG_ OVCUrrenceStatorPWMETractSys2 : 206|2@1+ (1,0) [0|3] ""  VCU
 SG_ StETractSys2Asd : 272|16@1+ (1,0) [0|65535] ""  VCU
 SG_ Qu_CurrDrctCurrETractSys2ActVal : 240|4@1+ (1,0) [1|15] ""  VCU
 SG_ StatusArbRpmETractSys2Limit : 244|4@1+ (1,0) [0|15] ""  VCU
 SG_ SumWhlTqIntvETractSys2 : 256|12@1+ (10,0) [0|40950] "Nm"  VCU
 SG_ StatusPbWETractSys2 : 224|8@1+ (1,0) [0|255] ""  VCU
 SG_ PowerETractSys2LossActualValue : 288|12@1+ (50,0) [0|204750] "W"  VCU
 SG_ TarTqETractSys2NControlStatic : 300|10@1+ (1,-510) [-510|513] "Nm"  VCU
 SG_ PwrLossPrednETractSys2Mot : 320|12@1+ (50,0) [0|204750] "W"  VCU
 SG_ PwrLossPrednETractSys2Genr : 332|12@1+ (50,0) [0|204750] "W"  VCU

BO_ 172 BMS_PowerCont: 24 BMS
 SG_ BMS_MaxDischgCurrentLimPeak : 32|16@1+ (0.1,0) [0|1500] "A"  VCU
 SG_ BMS_MaxDischgPwrLimPeak : 112|16@1+ (0.1,0) [0|800] "kW"  VCU
 SG_ ALV_BMS_PowerCont : 8|4@1+ (1,0) [0|14] ""  VCU
 SG_ BMS_MaxDischgCurrentLim : 16|16@1+ (0.1,0) [0|1500] "A"  VCU
 SG_ BMS_MaxDischgPwr30s : 160|16@1+ (0.1,0) [0|800] "kW"  VCU
 SG_ BMS_MaxDischgPwr10s : 144|16@1+ (0.1,0) [0|800] "kW"  VCU
 SG_ BMS_MaxDischgPwr2s : 128|16@1+ (0.1,0) [0|800] "kW"  VCU
 SG_ BMS_MaxDischgPwrLim : 96|16@1+ (0.1,0) [0|800] "kW"  VCU
 SG_ BMS_MaxDischgCurrent30s : 80|16@1+ (0.1,0) [0|1500] "A"  VCU
 SG_ BMS_MaxDischgCurrent10s : 64|16@1+ (0.1,0) [0|1500] "A"  VCU
 SG_ BMS_MaxDischgCurrent2s : 48|16@1+ (0.1,0) [0|1500] "A"  VCU
 SG_ CRC_BMS_PowerCont : 0|8@1+ (1,0) [0|255] ""  VCU

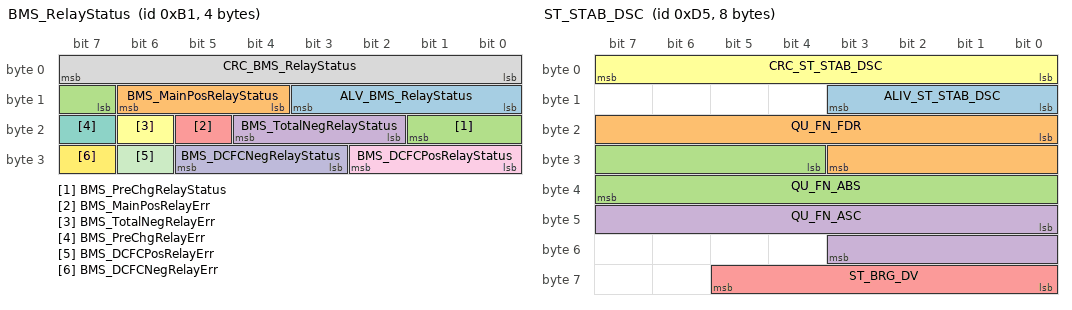
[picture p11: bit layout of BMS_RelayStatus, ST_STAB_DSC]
BO_ 177 BMS_RelayStatus: 4 BMS
 SG_ ALV_BMS_RelayStatus : 8|4@1+ (1,0) [0|14] ""  VCU
 SG_ BMS_MainPosRelayStatus : 12|3@1+ (1,0) [0|7] ""  VCU
 SG_ BMS_PreChgRelayStatus : 15|3@1+ (1,0) [0|7] ""  VCU
 SG_ BMS_TotalNegRelayStatus : 18|3@1+ (1,0) [0|7] ""  VCU
 SG_ BMS_MainPosRelayErr : 21|1@1+ (1,0) [0|1] ""  VCU
 SG_ BMS_TotalNegRelayErr : 22|1@1+ (1,0) [0|1] ""  VCU
 SG_ BMS_PreChgRelayErr : 23|1@1+ (1,0) [0|1] ""  VCU
 SG_ CRC_BMS_RelayStatus : 0|8@1+ (1,0) [0|255] ""  VCU
 SG_ BMS_DCFCPosRelayStatus : 24|3@1+ (1,0) [0|7] ""  VCU
 SG_ BMS_DCFCNegRelayStatus : 27|3@1+ (1,0) [0|7] ""  VCU
 SG_ BMS_DCFCPosRelayErr : 30|1@1+ (1,0) [0|1] ""  VCU
 SG_ BMS_DCFCNegRelayErr : 31|1@1+ (1,0) [0|1] ""  VCU

BO_ 182 BMS_Sts: 12 BMS
 SG_ BMS_HVOnOffSts : 12|2@1+ (1,0) [0|3] ""  PDU_DCDC,VCU
 SG_ BMS_BatBalanceErr : 37|1@1+ (1,0) [0|1] ""  PDU_DCDC,VCU
 SG_ BMS_ErrLev : 16|4@1+ (1,0) [0|7] ""  PDU_DCDC,VCU
 SG_ BMS_DisconnectRequestRsn : 72|6@1+ (1,0) [0|31] ""  PDU_DCDC,VCU
 SG_ BMS_EmergencyDisconnectRsn : 80|6@1+ (1,0) [0|31] ""  PDU_DCDC,VCU
 SG_ BMS_LimpHomeRsn : 88|6@1+ (1,0) [0|31] ""  PDU_DCDC,VCU
 SG_ BMS_HVILSts : 14|2@1+ (1,0) [0|3] ""  PDU_DCDC,VCU
 SG_ BMS_HWCrashSts : 36|1@1+ (1,0) [0|1] ""  PDU_DCDC,VCU
 SG_ BMS_SOE : 64|8@1+ (0.5,0) [0|100] "%"  PDU_DCDC,VCU
 SG_ BMS_BalanceSts : 38|1@1+ (1,0) [0|1] ""  PDU_DCDC,VCU
 SG_ BMS_SocRelativeEst : 40|10@1+ (0.1,0) [0|100] "%"  PDU_DCDC,VCU
 SG_ BMS_SocActualEst : 24|10@1+ (0.1,0) [0|100] "%"  PDU_DCDC,VCU
 SG_ BMS_SysSts : 20|4@1+ (1,0) [0|15] ""  PDU_DCDC,VCU
 SG_ CRC_BMS_Sts : 0|8@1+ (1,0) [0|255] ""  PDU_DCDC,VCU
 SG_ ALV_BMS_Sts : 8|4@1+ (1,0) [0|14] ""  PDU_DCDC,VCU
 SG_ BMS_IGNSts : 39|1@1+ (1,0) [0|1] ""  PDU_DCDC,VCU
 SG_ BMS_SOH : 56|8@1+ (0.5,0) [0|100] "%"  PDU_DCDC,VCU

BO_ 187 BMS_WarnMsg: 8 BMS
 SG_ BMS_Reserved_signal2 : 32|8@1+ (1,0) [0|255] ""  VCU
 SG_ BMS_Warning_Flag_5 : 16|1@1+ (1,0) [0|1] ""  VCU
 SG_ BMS_Reserved_signal5 : 56|8@1+ (1,0) [0|255] ""  VCU
 SG_ BMS_Reserved_signal4 : 48|8@1+ (1,0) [0|255] ""  VCU
 SG_ BMS_Reserved_signal3 : 40|8@1+ (1,0) [0|255] ""  VCU
 SG_ BMS_Reserved_signal1 : 24|8@1+ (1,0) [0|255] ""  VCU
 SG_ BMS_Warning_Flag_6 : 17|1@1+ (1,0) [0|1] ""  VCU
 SG_ BMS_MalfunctionSts : 21|1@1+ (1,0) [0|1] ""  VCU
 SG_ BMS_BatteryReplacement : 15|1@1+ (1,0) [0|1] ""  VCU
 SG_ BMS_ThermalRunaway : 14|1@1+ (1,0) [0|1] ""  VCU
 SG_ BMS_PackTempSts : 12|2@1+ (1,0) [0|3] ""  VCU
 SG_ ALV_BMS_WarnMsg : 8|4@1+ (1,0) [0|14] ""  VCU
 SG_ BMS_Warning_Flag_7 : 18|1@1+ (1,0) [0|1] ""  VCU
 SG_ BMS_LowBattery : 22|2@1+ (1,0) [0|3] ""  VCU
 SG_ BMS_Warning_Flag_8 : 19|1@1+ (1,0) [0|1] ""  VCU
 SG_ BMS_Warning_Flag_9 : 20|1@1+ (1,0) [0|1] ""  VCU
 SG_ CHSKM_BMS_WarnMsg : 0|8@1+ (1,0) [0|255] ""  VCU

BO_ 213 ST_STAB_DSC: 8 VCU
 SG_ ALIV_ST_STAB_DSC : 8|4@1+ (1,0) [0|14] ""  MCU_R,MCU_F
 SG_ QU_FN_FDR : 16|12@1+ (1,0) [0|4095] ""  MCU_R,MCU_F
 SG_ QU_FN_ABS : 28|12@1+ (1,0) [512|4095] ""  MCU_R,MCU_F
 SG_ QU_FN_ASC : 40|12@1+ (1,0) [512|4095] ""  MCU_R,MCU_F
 SG_ ST_BRG_DV : 56|6@1+ (1,0) [0|63] ""  MCU_R,MCU_F
 SG_ CRC_ST_STAB_DSC : 0|8@1+ (1,0) [0|255] ""  MCU_R,MCU_F

BO_ 214 ST_STAB_DSC_2: 8 VCU
 SG_ ST_SLIP_THO : 44|4@1+ (1,0) [0|15] ""  MCU_R,MCU_F

BO_ 217 WMOM_PT_AVL: 16 VCU
 SG_ CHL_WMOM_PT_AVL : 12|4@1+ (1,0) [0|15] ""  MCU_F,MCU_R
 SG_ ALIV_WMOM_PT_AVL : 8|4@1+ (1,0) [0|14] ""  MCU_F,MCU_R
 SG_ CRC_WMOM_PT_AVL : 0|8@1+ (1,0) [0|255] ""  MCU_R,MCU_F
 SG_ AVL_WMOM_PT_SUM : 80|16@1+ (1,-32000) [-32000|33535] "Nm"  MCU_R,MCU_F
 SG_ QU_AVL_WMOM_PT_SUM : 96|4@1+ (1,0) [1|15] ""  MCU_R,MCU_F

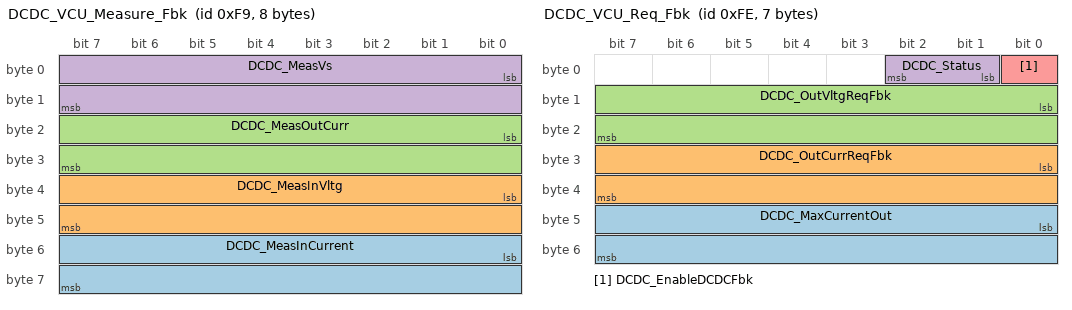
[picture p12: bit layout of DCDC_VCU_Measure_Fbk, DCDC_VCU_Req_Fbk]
BO_ 249 DCDC_VCU_Measure_Fbk: 8 PDU_DCDC
 SG_ DCDC_MeasInCurrent : 48|16@1+ (0.1,0) [0|6553.5] "A"  VCU
 SG_ DCDC_MeasInVltg : 32|16@1+ (0.0625,0) [0|4095.9375] "V"  VCU
 SG_ DCDC_MeasOutCurr : 16|16@1+ (0.1,0) [0|6553.5] "A"  VCU
 SG_ DCDC_MeasVs : 0|16@1+ (0.0625,0) [0|4095.9375] "V"  VCU

BO_ 254 DCDC_VCU_Req_Fbk: 7 PDU_DCDC
 SG_ DCDC_MaxCurrentOut : 40|16@1+ (0.1,0) [0|6553.5] "A"  VCU
 SG_ DCDC_OutCurrReqFbk : 24|16@1+ (0.1,0) [0|6553.5] "A"  VCU
 SG_ DCDC_OutVltgReqFbk : 8|16@1+ (0.0625,0) [0|4095.9375] "V"  VCU
 SG_ DCDC_Status : 1|2@1+ (1,0) [0|3] ""  VCU
 SG_ DCDC_EnableDCDCFbk : 0|1@1+ (1,0) [0|1] ""  VCU

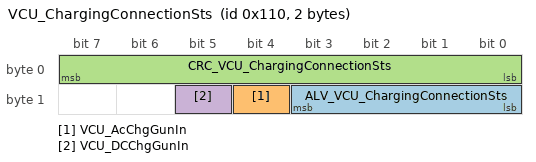
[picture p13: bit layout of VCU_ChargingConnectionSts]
BO_ 272 VCU_ChargingConnectionSts: 2 VCU
 SG_ ALV_VCU_ChargingConnectionSts : 8|4@1+ (1,0) [0|14] ""  OBC,BMS
 SG_ VCU_AcChgGunIn : 12|1@1+ (1,0) [0|1] ""  OBC,BMS
 SG_ CRC_VCU_ChargingConnectionSts : 0|8@1+ (1,0) [0|255] ""  OBC,BMS
 SG_ VCU_DCChgGunIn : 13|1@1+ (1,0) [0|1] ""  OBC,BMS

BO_ 289 BundleEAFlexrayToCANFD20msNo1: 32 VCU
 SG_ CRC_V_VEH : 128|8@1+ (1,0) [0|255] ""  MCU_R,MCU_F
 SG_ SecOcDataP2V_VEH : 168|64@1+ (1,0) [0|1.84467E+019] ""  MCU_R,MCU_F
 SG_ QU_V_VEH_COG : 160|4@1+ (1,0) [1|15] ""  MCU_R,MCU_F
 SG_ V_VEH_COG : 144|16@1+ (0.015625,0) [0|350] "km/h"  MCU_R,MCU_F
 SG_ ALIV_V_VEH : 136|4@1+ (1,0) [0|14] ""  MCU_R,MCU_F

CM_ BU_ Tester "Diagnostic Tester";
CM_ BU_ BMS "Battery Management System";
CM_ BU_ VCU "Vehicle Control Unit";
CM_ BU_ MCU_R "Motor Control Unit-Rear";
CM_ BU_ MCU_F "Motor Control Unit-Front";
CM_ BU_ PDU_DCDC "Power Distribution Unit - DC to DC Convertor (2in1)";
CM_ BU_ OBC "On Board Charger";
CM_ BU_ IMM "Immobilizer Simulator";
CM_ BO_ 1777 "Extended Diag request BMW";
CM_ SG_ 1777 Tester_DiagReq_Byte7 "Diagnostic signal Data request";
CM_ SG_ 1777 Tester_DiagReq_Byte6 "Diagnostic signal Data request";
CM_ SG_ 1777 Tester_DiagReq_Byte5 "Diagnostic signal Data request";
CM_ SG_ 1777 Tester_DiagReq_Byte4 "Diagnostic signal Data request";
CM_ SG_ 1777 Tester_DiagReq_Byte3 "Diagnostic signal Data request";
CM_ SG_ 1777 Tester_DiagReq_Byte2 "Diagnostic signal Data request";
CM_ SG_ 1777 Tester_DiagReq_Byte1 "Diagnostic signal Data request";
CM_ SG_ 1777 Tester_DiagReq_Byte0 "Diagnostic signal Data request";
CM_ BO_ 1556 "Diagnostic signal Data response";
CM_ SG_ 1556 MCU_R_DiagResp_Byte7 "Diagnostic signal Data response";
CM_ SG_ 1556 MCU_R_DiagResp_Byte6 "Diagnostic signal Data response";
CM_ SG_ 1556 MCU_R_DiagResp_Byte5 "Diagnostic signal Data response";
CM_ SG_ 1556 MCU_R_DiagResp_Byte4 "Diagnostic signal Data response";
CM_ SG_ 1556 MCU_R_DiagResp_Byte3 "Diagnostic signal Data response";
CM_ SG_ 1556 MCU_R_DiagResp_Byte2 "Diagnostic signal Data response";
CM_ SG_ 1556 MCU_R_DiagResp_Byte1 "Diagnostic signal Data response";
CM_ SG_ 1556 MCU_R_DiagResp_Byte0 "Diagnostic signal Data response";
CM_ BO_ 1647 "Diagnostic signal Data response";
CM_ SG_ 1647 MCU_F_DiagResp_Byte7 "Diagnostic signal Data response";
CM_ SG_ 1647 MCU_F_DiagResp_Byte6 "Diagnostic signal Data response";
CM_ SG_ 1647 MCU_F_DiagResp_Byte5 "Diagnostic signal Data response";
CM_ SG_ 1647 MCU_F_DiagResp_Byte4 "Diagnostic signal Data response";
CM_ SG_ 1647 MCU_F_DiagResp_Byte3 "Diagnostic signal Data response";
CM_ SG_ 1647 MCU_F_DiagResp_Byte2 "Diagnostic signal Data response";
CM_ SG_ 1647 MCU_F_DiagResp_Byte1 "Diagnostic signal Data response";
CM_ SG_ 1647 MCU_F_DiagResp_Byte0 "Diagnostic signal Data response";
CM_ SG_ 1805 DCDC_XCP_Response_Byte1 "DCDC XCP Response Signal";
CM_ SG_ 1805 DCDC_XCP_Response_Byte5 "DCDC XCP Response Signal";
CM_ SG_ 1805 DCDC_XCP_Response_Byte4 "DCDC XCP Response Signal";
CM_ SG_ 1805 DCDC_XCP_Response_Byte3 "DCDC XCP Response Signal";
CM_ SG_ 1805 DCDC_XCP_Response_Byte2 "DCDC XCP Response Signal";
CM_ SG_ 1805 DCDC_XCP_Response_Byte0 "DCDC XCP Response Signal";
CM_ SG_ 1805 DCDC_XCP_Response_Byte7 "DCDC XCP Response Signal";
CM_ SG_ 1805 DCDC_XCP_Response_Byte6 "DCDC XCP Response Signal";
CM_ SG_ 1933 DCDC_XCP_Request_Byte0 "DCDC XCP Request Signal";
CM_ SG_ 1933 DCDC_XCP_Request_Byte1 "DCDC XCP Request Signal";
CM_ SG_ 1933 DCDC_XCP_Request_Byte2 "DCDC XCP Request Signal";
CM_ SG_ 1933 DCDC_XCP_Request_Byte3 "DCDC XCP Request Signal";
CM_ SG_ 1933 DCDC_XCP_Request_Byte4 "DCDC XCP Request Signal";
CM_ SG_ 1933 DCDC_XCP_Request_Byte5 "DCDC XCP Request Signal";
CM_ SG_ 1933 DCDC_XCP_Request_Byte6 "DCDC XCP Request Signal";
CM_ SG_ 1807 VCU_XCP_Response_Byte7 "Diagnostic signal Data request";
CM_ SG_ 1807 VCU_XCP_Response_Byte6 "Diagnostic signal Data request";
CM_ SG_ 1807 VCU_XCP_Response_Byte5 "Diagnostic signal Data request";
CM_ SG_ 1807 VCU_XCP_Response_Byte4 "Diagnostic signal Data request";
CM_ SG_ 1807 VCU_XCP_Response_Byte3 "Diagnostic signal Data request";
CM_ SG_ 1807 VCU_XCP_Response_Byte2 "Diagnostic signal Data request";
CM_ SG_ 1807 VCU_XCP_Response_Byte1 "Diagnostic signal Data request";
CM_ SG_ 1807 VCU_XCP_Response_Byte0 "Diagnostic signal Data request";
CM_ SG_ 1935 VCU_XCP_Request_Byte7 "Diagnostic signal Data request";
CM_ SG_ 1935 VCU_XCP_Request_Byte6 "Diagnostic signal Data request";
CM_ SG_ 1935 VCU_XCP_Request_Byte5 "Diagnostic signal Data request";
CM_ SG_ 1935 VCU_XCP_Request_Byte4 "Diagnostic signal Data request";
CM_ SG_ 1935 VCU_XCP_Request_Byte3 "Diagnostic signal Data request";
CM_ SG_ 1935 VCU_XCP_Request_Byte2 "Diagnostic signal Data request";
CM_ SG_ 1935 VCU_XCP_Request_Byte1 "Diagnostic signal Data request";
CM_ SG_ 1935 VCU_XCP_Request_Byte0 "Diagnostic signal Data request";
CM_ BO_ 1806 "OBC XCP Response
";
CM_ SG_ 1806 OBC_XCP_Response_Byte7 "Diagnostic signal Data request";
CM_ SG_ 1806 OBC_XCP_Response_Byte6 "Diagnostic signal Data request";
CM_ SG_ 1806 OBC_XCP_Response_Byte5 "Diagnostic signal Data request";
CM_ SG_ 1806 OBC_XCP_Response_Byte4 "Diagnostic signal Data request";
CM_ SG_ 1806 OBC_XCP_Response_Byte3 "Diagnostic signal Data request";
CM_ SG_ 1806 OBC_XCP_Response_Byte2 "Diagnostic signal Data request";
CM_ SG_ 1806 OBC_XCP_Response_Byte1 "Diagnostic signal Data request";
CM_ SG_ 1806 OBC_XCP_Response_Byte0 "Diagnostic signal Data request";
CM_ BO_ 1934 "OBC xcp REQUEST";
CM_ SG_ 1934 OBC_XCP_Request_Byte7 "Diagnostic signal Data request";
CM_ SG_ 1934 OBC_XCP_Request_Byte6 "Diagnostic signal Data request";
CM_ SG_ 1934 OBC_XCP_Request_Byte5 "Diagnostic signal Data request";
CM_ SG_ 1934 OBC_XCP_Request_Byte4 "Diagnostic signal Data request";
CM_ SG_ 1934 OBC_XCP_Request_Byte3 "Diagnostic signal Data request";
CM_ SG_ 1934 OBC_XCP_Request_Byte2 "Diagnostic signal Data request";
CM_ SG_ 1934 OBC_XCP_Request_Byte1 "Diagnostic signal Data request";
CM_ SG_ 1934 OBC_XCP_Request_Byte0 "Diagnostic signal Data request";
CM_ BO_ 411 "OBC status
";
CM_ SG_ 411 OBC_SeqSta "OBC operational sequence status";
CM_ SG_ 411 OBC_HvIntlkStatus "OBC High-Voltage Interlock Status";
CM_ BO_ 634 "DCDC status
";
CM_ SG_ 634 DCDC_SysOpSta "DCDC operating status";
CM_ SG_ 634 DCDC_HvIntlkStatus "DCDC High-Voltage Interlock Status";
CM_ SG_ 395 BMS_CellTemp48 "Cell temperature of sensor 36";
CM_ SG_ 395 BMS_CellTemp47 "Cell temperature of sensor 36";
CM_ SG_ 395 BMS_CellTemp46 "Cell temperature of sensor 36";
CM_ SG_ 395 BMS_CellTemp45 "Cell temperature of sensor 36";
CM_ SG_ 395 BMS_CellTemp44 "Cell temperature of sensor 36";
CM_ SG_ 395 BMS_CellTemp43 "Cell temperature of sensor 36";
CM_ SG_ 395 BMS_CellTemp42 "Cell temperature of sensor 36";
CM_ SG_ 395 CRC_BMS_CellTempMeas2 "Checksum";
CM_ SG_ 395 ALV_BMS_CellTempMeas2 "Alive counter";
CM_ SG_ 497 STAT_CL30S_L "Logical clamp status
Fixed Value = 0";
CM_ SG_ 497 STAT_CL30S_Light "Logical clamp status
Fixed Value = 0";
CM_ SG_ 497 STAT_CL15_WUPL "Logical clamp status
Fixed Value = 0";
CM_ BO_ 60 "-";
CM_ SG_ 60 CRC_CON_VEH "Standard application CRC validation according to the definition in requirements specification Allgemeine Bordnetzkommunikation.
This signal uses the application CRC ID = 197 (dec).";
CM_ SG_ 60 ALIV_CON_VEH "Standard alive counter validation as per definition in the requirements specification Allgemeine Bordnetzkommunikation.";
CM_ SG_ 60 CTR_BS_PRTNT "This signal indicates whether communication is required in the current vehicle state.
Duplicate value";
CM_ SG_ 60 CTR_FKTN_PRTNT "This signal indicates which functional subnets are active.
Fixed Value = 102912";
CM_ SG_ 60 ST_CON_VEH "The signal Status_Zustand_Fahrzeug describes the vehicle state from the customer's view. Based on this state, it is defined, which (customer) functions should currently be available.";
CM_ SG_ 60 QU_ST_CON_VEH "The signal indicates whether the calculated value of Status_Zustand_Fahrzeug==Drive is correct and whether the safety-relevant input variables are valid.
Fixed Value = 2";
CM_ BO_ 130 "-";
CM_ SG_ 130 CRC_ST_CR "Standard application CRC validation according to the definition in requirements specification Allgemeine Bordnetzkommunikation.
This application CRC uses the following application CRC ID: 54 dec (36h)";
CM_ SG_ 130 ST_CRSE_REAR "In case of a crash, the crash severity for a rear crash is determined in relation to the measured acceleration values.
Fixed Value = 0";
CM_ SG_ 130 ST_CRSE_ROV "In case of a crash, the crash severity for a roll-over crash is determined in relation to the measured acceleration values.
Fixed Value = 0";
CM_ SG_ 130 ST_CRSE_SIDE_LH "In case of a crash, the crash severity for a side crash from the left is determined in relation to the measured acceleration values.
Fixed Value = 0";
CM_ SG_ 130 ST_CRSE_SIDE_RH "In case of a crash, the crash severity for a side crash from the right is determined in relation to the measured acceleration values.
Fixed Value = 0";
CM_ SG_ 130 ST_CRSE_FRT "In case of a crash, the crash severity for a front crash is determined in relation to the measured acceleration values.
Fixed Value = 0";
CM_ SG_ 130 ALIV_ST_CR "Standard alive counter validation as per definition in the requirements specification Allgemeine Bordnetzkommunikation.";
CM_ BO_ 131 "-";
CM_ SG_ 131 CRC_AVL_RPM_WHL "This signal uses the application CRC ID = 17 (dec)";
CM_ SG_ 131 ALIV_AVL_RPM_WHL "Alive counter";
CM_ SG_ 131 AVL_RPM_WHL_RLH "Measured speed of the left rear wheel.";
CM_ SG_ 131 AVL_RPM_WHL_RRH "Measured speed of the right rear wheel.";
CM_ SG_ 131 AVL_RPM_WHL_FLH "Measured speed of the left front wheel.";
CM_ SG_ 131 AVL_RPM_WHL_FRH "Measured speed of the right front wheel.";
CM_ SG_ 131 QU_AVL_RPM_WHL_RLH "Status qualifier for signal Ist_Drehzahl_Rad_HL.
Fixed Value = 1";
CM_ SG_ 131 QU_AVL_RPM_WHL_RRH "Status qualifier for signal Ist_Drehzahl_Rad_HR.
Fixed Value = 1";
CM_ SG_ 131 QU_AVL_RPM_WHL_FLH "Status qualifier for signal Ist_Drehzahl_Rad_VL.
Fixed Value = 1";
CM_ SG_ 131 QU_AVL_RPM_WHL_FRH "Status qualifier for signal Ist_Drehzahl_Rad_VR.
Fixed Value = 1";
CM_ BO_ 132 "-";
CM_ SG_ 132 BMS_MaxChgCurrent10s "Allowed Charge Current (10Seconds)";
CM_ SG_ 132 CRC_BMS_ChgParamReq "Checksum";
CM_ SG_ 132 BMS_MaxChgCurrent2s "Allowed Charge Current (2Seconds)";
CM_ SG_ 132 BMS_ChgVoltageReq "Charge Voltage Request";
CM_ SG_ 132 ALV_BMS_ChgParamReq "Alive Counter";
CM_ SG_ 132 BMS_RemainChargeTime "Remain Charge Time
1501-4095 - Invalid signal";
CM_ SG_ 132 BMS_ChargeStopReq "Charge Stop Request";
CM_ SG_ 132 BMS_MaxChgPwr30s "Allowed Charge(Regen) Power (30Seconds)";
CM_ SG_ 132 BMS_MaxChgPwr10s "Allowed Charge(Regen) Power (10Seconds)";
CM_ SG_ 132 BMS_MaxChgPwr2s "Allowed Charge(Regen) Power (2Seconds)
";
CM_ SG_ 132 BMS_MaxChgCurrentLim "Allowed Charge Current (Continuous)";
CM_ SG_ 132 BMS_MaxChgCurrent30s "Allowed Charge Current (30Seconds)";
CM_ SG_ 132 BMS_ChgCurrentReq "Charge Current Request";
CM_ SG_ 132 BMS_MaxChgPwrLim "Allowed Charge(Regen) Power (Continuous)";
CM_ SG_ 132 BMS_MaxChgCurrentLimPeak "Allowed Charge Current (Peak)";
CM_ SG_ 132 BMS_MaxChgPwrLimPeak "Allowed Charge(Regen) Power (Peak)";
CM_ BO_ 137 "-";
CM_ SG_ 137 BMS_PackCurMeas "Battery Pack Total Current
0xFFFF - Invalid";
CM_ SG_ 137 BMS_StartOfMeasument_STS "Synchronize signals indicate start of cell/pack voltage measument";
CM_ SG_ 137 ALV_BMS_CurMeas "Alive Counter";
CM_ SG_ 137 CRC_BMS_CurMeas "Checksum";
CM_ BO_ 138 "-";
CM_ SG_ 138 OperatingModeETract1Target "Target operating mode of electric machine system 1";
CM_ SG_ 138 ALIV_CombinedChargerUnit10msNo3 "Standard alive counter validation as per definition in the requirements specification Allgemeine Bordnetzkommunikation.";
CM_ SG_ 138 CRC_CombinedChargerUnit10msNo3 "This signal contains the CRC checksum for the standard validation with application CRC-16 according to the definition as per requirements specification Bordnetzkommunikation. 
The signal uses the application data ID (16-bit) 91 (dec) = 5B (hex).";
CM_ SG_ 138 OperatingModeETract2Target "Target operating mode of electric machine system 2";
CM_ BO_ 141 "-";
CM_ SG_ 141 SecOcDtP2CmbdChrgUnit10msNo1_3 "This PDU is SecOC-validated.
";
CM_ SG_ 141 SecOcDtP2CmbdChrgUnit10msNo1_2 "This PDU is SecOC-validated.
";
CM_ SG_ 141 SecOcDtP2CmbdChrgUnit10msNo1_1 "This PDU is SecOC-validated.
";
CM_ SG_ 141 TargetEMRpmETractSys2 "Target speed of electric machine system 2.";
CM_ SG_ 141 StatusReleaseTorqueVerified "The driving readiness release safety mechanism on the engine control unit uses this signal to communicate release or revocation of driving readiness to the receivers. ";
CM_ SG_ 141 SecOcDtP2CmbdChrgUnit10msNo1_0 "This PDU is SecOC-validated.
";
CM_ SG_ 141 StatusDampingVibration "This signal indicates the status information regarding which drive components have active vibration damping (anti-jerk function).
Fixed Value = 0";
CM_ SG_ 141 TorqBoundaryETractSys2EmNCtrlMin "Untermomentengrenze (referenziert auf Getriebeeingang) für den E-Maschine-Drehzahlregler des E-Maschinensystems 2.
Fixed Value = 0";
CM_ SG_ 141 TorqBoundaryETractSys2EmNCtrlMax "Obermomentengrenze (referenziert auf Getriebeeingang) für den E-Maschine-Drehzahlregler des E-Maschinensystems 2.
Fixed Value = 1023";
CM_ SG_ 141 TorqBoundaryETractSys1EmNCtrlMin "Untermomentengrenze (referenziert auf Getriebeeingang) für den E-Maschine-Drehzahlregler des E-Maschinensystems 1.
Fixed Value = 0";
CM_ SG_ 141 TorqBoundaryETractSys1EmNCtrlMax "Obermomentengrenze (referenziert auf Getriebeeingang) für den E-Maschine-Drehzahlregler des E-Maschinensystems 1.
Fixed Value = 1023";
CM_ SG_ 141 TargetTorqueEmETractSys2 "Target torque of electric machine system 2.
Fixed Value = 65535";
CM_ SG_ 141 TargetEMRpmETractSys1 "Target speed of electric machine system 1.";
CM_ SG_ 141 TargetTorqueEmETractSys1 "Target torque of electric machine system 1.
Fixed Value = 65535";
CM_ SG_ 141 CRC_CombinedChargerUnit10msNo1 "This signal contains the CRC checksum for the standard validation with application CRC-16 according to the definition as per requirements specification Bordnetzkommunikation. 
The signal uses application data ID (16 bit) 38 (dec) = 26 (hex).";
CM_ SG_ 141 ALIV_CombinedChargerUnit10msNo1 "Standard alive counter validation as per definition in the requirements specification Allgemeine Bordnetzkommunikation.";
CM_ BO_ 142 "-";
CM_ SG_ 142 BMS_DebugSignal2 "Debug Signal 2";
CM_ SG_ 142 BMS_DebugSignal1 "Debug Signal 1";
CM_ BO_ 143 "-";
CM_ SG_ 143 CRC_HighVoltageStorage10msNo2 "This signal contains the CRC checksum for the standard validation with application CRC-16 according to the definition as per requirements specification Bordnetzkommunikation. 
The signal uses application data ID (16 bits) 115 (dec) = 0073 (hex).";
CM_ SG_ 143 ALIV_HighVoltageStorage10msNo2 "Standard alive counter validation as per definition in the requirements specification Allgemeine Bordnetzkommunikation.";
CM_ SG_ 143 ActualValueVoltageLinkVerified "The signal sends the link voltage as currently measured by the SME.
The signal is required for display of the absence of voltage.";
CM_ BO_ 145 "-";
CM_ SG_ 145 ALIV_TracEMacElectc1Time10msNo1 "Standard alive counter validation as per definition in the requirements specification Allgemeine Bordnetzkommunikation.";
CM_ SG_ 145 PwrLossPrednETractSys1Genr "Forecast power loss in the current maximum possible generative operating point of electric machine system 1.";
CM_ SG_ 145 PwrLossPrednETractSys1Mot "Forecast power loss in the current maximum possible motorized operating point of electric machine system 1.";
CM_ SG_ 145 TarTqETractSys1NControlStatic "Target torque speed controller slow portion.";
CM_ SG_ 145 PowerETractSys1LossActualValue "Actual power loss of electric machine system 1.";
CM_ SG_ 145 StETractSys1Asd "The signal describes the reason for the deactivation of the active vibration damping function in electric machine system 1.";
CM_ SG_ 145 SumWhlTqIntvETractSys1 "Wheel torque intervention sum (amount) of the wheel slip delimiter that is located in proximity to the actuator for electric machine system 1.";
CM_ SG_ 145 StatusArbRpmETractSys1Limit "Status of the speed delimiter through actuator-related wheel slip limitation function for electric machine system 1.
Fixed Value = 0";
CM_ SG_ 145 Qu_CurrDrctCurrETractSys1ActVal "Signal quality of the signal CurrentDirectCurrentETractSys1ActualValue.";
CM_ SG_ 145 QualifierRpmEmETractSys1ActVal "Signal quality of the signal RpmEmETractSys1ActualValue.";
CM_ SG_ 145 QualifierTqEmETractSys1ActVal "Signal quality of the signal TorqueEmETractSys1ActualValue.";
CM_ SG_ 145 StatusPbWETractSys1 "Error status of the parking lock on electric machine 1.";
CM_ SG_ 145 CRC_TracEMacElectc1Time10msNo1 "This signal contains the CRC checksum for the standard validation with application CRC-16 according to the definition as per requirements specification Bordnetzkommunikation. 
The signal uses application data ID (16 bit) 39 (dec) = 27 (hex).";
CM_ SG_ 145 OVCUrrenceStatorPWMETractSys1 "This signal indicates if PWM has been applied to the stator in the last 10 ms.";
CM_ SG_ 145 TqEmETractSys1MotorSumLimTarget "Cumulated and limited target torque of the electric motor of electric machine system 1.";
CM_ SG_ 145 TorqueEmETractSys1ActualValue "Actual torque of the electric motor of electric machine system 1.
";
CM_ SG_ 145 TorqueEmETractSys1MotorDynamic "Maximum possible motorized electrical machine torque of electric machine system 1 including the assigned performance/voltage limits, depending on the specific component.";
CM_ SG_ 145 TorqueEmETractSys1MotorStatic "Maximum possible motorized electrical machine torque of electric machine system 1 excluding the assigned performance/voltage limits, depending on the specific component.";
CM_ SG_ 145 TqEmETractSys1GeneratorDynamic "Maximum possible generative electrical machine torque of electric machine system 1 including the assigned performance/voltage limits, depending on the specific component.";
CM_ SG_ 145 TqEmETractSys1GeneratorStatic "Maximum possible generative electrical machine torque of electric machine system 1 excluding the assigned performance/voltage limits, depending on the specific component.";
CM_ SG_ 145 RpmEmETractSys1ActualValue "Actual speed of the electric motor of electric machine system 1.";
CM_ SG_ 145 TqEmETractSys1VibrationDampSusp "Requested torque reserve for vibration damping for the electric motor of electric machine system 1.";
CM_ SG_ 145 RpmEmETractSys1MinimumLimit "Lower speed limit of the electric motor of electric machine system 1.";
CM_ SG_ 145 RpmEmETractSys1MaximumLimit "Upper speed limit of the electric motor of electric machine system 1.";
CM_ SG_ 145 VolDrctCurrETractSys1ActVal "Actual voltage of the intermediate circuit of electric machine system 1.";
CM_ SG_ 145 CurrDrctCurrETractSys1ActVal "Actual DC current of electric machine system 1.";
CM_ SG_ 145 DirOfRotETractSys1ActVal "Actual rotational direction of electric machine system 1.";
CM_ SG_ 145 StatusLockPositionPbWETractSys1 "Position status of the parking lock on electric machine 1.";
CM_ BO_ 146 "-";
CM_ SG_ 146 CTR_ERRM_BN_U "The signal Steuerung_Fehlerspeicher_Bordnetz_Spannung provides voltage thresholds for handling the error memory.
Fixed Value = 0";
CM_ BO_ 147 "-";
CM_ SG_ 147 BMS_DebugSignal6 "Debug Signal 6";
CM_ SG_ 147 BMS_DebugSignal4 "Debug Signal 4";
CM_ SG_ 147 BMS_DebugSignal5 "Debug Signal 5";
CM_ SG_ 147 BMS_DebugSignal3 "Debug Signal 3";
CM_ BO_ 153 "-";
CM_ SG_ 153 BMS_DebugSignal8 "Debug Signal 8";
CM_ SG_ 153 BMS_DebugSignal7 "Debug Signal 7";
CM_ SG_ 153 BMS_DebugSignal11 "Debug Signal 11";
CM_ SG_ 153 BMS_DebugSignal12 "Debug Signal 12";
CM_ SG_ 153 BMS_DebugSignal13 "Debug Signal 13";
CM_ SG_ 153 BMS_DebugSignal10 "Debug Signal 10";
CM_ SG_ 153 BMS_DebugSignal14 "Debug Signal 14";
CM_ SG_ 153 BMS_DebugSignal9 "Debug Signal 9";
CM_ BO_ 155 "-";
CM_ SG_ 155 EWS_BEV_1_7 "Immobilizer - no detailed description";
CM_ SG_ 155 EWS_BEV_1_6 "Immobilizer - no detailed description";
CM_ SG_ 155 EWS_BEV_1_3 "Immobilizer - no detailed description";
CM_ SG_ 155 EWS_BEV_1_2 "Immobilizer - no detailed description";
CM_ SG_ 155 EWS_BEV_1_1 "Immobilizer - no detailed description";
CM_ SG_ 155 EWS_BEV_1_0 "Immobilizer - no detailed description";
CM_ SG_ 155 EWS_BEV_1_5 "Immobilizer - no detailed description";
CM_ SG_ 155 EWS_BEV_1_4 "Immobilizer - no detailed description";
CM_ BO_ 156 "-";
CM_ SG_ 156 EWS_BEV_1_ANSW_0 "Immobilizer - no detailed description";
CM_ SG_ 156 EWS_BEV_1_ANSW_1 "Immobilizer - no detailed description";
CM_ SG_ 156 EWS_BEV_1_ANSW_3 "Immobilizer - no detailed description";
CM_ SG_ 156 EWS_BEV_1_ANSW_4 "Immobilizer - no detailed description";
CM_ SG_ 156 EWS_BEV_1_ANSW_5 "Immobilizer - no detailed description";
CM_ SG_ 156 EWS_BEV_1_ANSW_6 "Immobilizer - no detailed description";
CM_ SG_ 156 EWS_BEV_1_ANSW_7 "Immobilizer - no detailed description";
CM_ SG_ 156 EWS_BEV_1_ANSW_2 "Immobilizer - no detailed description";
CM_ BO_ 157 "-";
CM_ SG_ 157 BMS_DebugSignal19 "Debug Signal 19";
CM_ SG_ 157 BMS_DebugSignal20 "Debug Signal 20";
CM_ SG_ 157 BMS_DebugSignal21 "Debug Signal 21";
CM_ SG_ 157 BMS_DebugSignal22 "Debug Signal 22";
CM_ SG_ 157 BMS_DebugSignal23 "Debug Signal 23";
CM_ SG_ 157 BMS_DebugSignal24 "Debug Signal 24";
CM_ SG_ 157 BMS_DebugSignal27 "Debug Signal 27";
CM_ SG_ 157 BMS_DebugSignal26 "Debug Signal 26";
CM_ SG_ 157 BMS_DebugSignal28 "Debug Signal 28";
CM_ SG_ 157 BMS_DebugSignal16 "Debug Signal 16";
CM_ SG_ 157 BMS_DebugSignal15 "Debug Signal 15";
CM_ SG_ 157 BMS_DebugSignal29 "Debug Signal 29";
CM_ SG_ 157 BMS_DebugSignal25 "Debug Signal 25";
CM_ SG_ 157 BMS_DebugSignal18 "Debug Signal 18";
CM_ SG_ 157 BMS_DebugSignal17 "Debug Signal 17";
CM_ BO_ 160 "-";
CM_ SG_ 160 EWS_BEV_2_5 "Immobilizer - no detailed description";
CM_ SG_ 160 EWS_BEV_2_7 "Immobilizer - no detailed description";
CM_ SG_ 160 EWS_BEV_2_6 "Immobilizer - no detailed description";
CM_ SG_ 160 EWS_BEV_2_4 "Immobilizer - no detailed description";
CM_ SG_ 160 EWS_BEV_2_3 "Immobilizer - no detailed description";
CM_ SG_ 160 EWS_BEV_2_2 "Immobilizer - no detailed description";
CM_ SG_ 160 EWS_BEV_2_1 "Immobilizer - no detailed description";
CM_ SG_ 160 EWS_BEV_2_0 "Immobilizer - no detailed description";
CM_ BO_ 161 "-";
CM_ SG_ 161 EWS_BEV_2_ANSW_2 "Immobilizer - no detailed description";
CM_ SG_ 161 EWS_BEV_2_ANSW_1 "Immobilizer - no detailed description";
CM_ SG_ 161 EWS_BEV_2_ANSW_0 "Immobilizer - no detailed description";
CM_ SG_ 161 EWS_BEV_2_ANSW_5 "Immobilizer - no detailed description";
CM_ SG_ 161 EWS_BEV_2_ANSW_6 "Immobilizer - no detailed description";
CM_ SG_ 161 EWS_BEV_2_ANSW_7 "Immobilizer - no detailed description";
CM_ SG_ 161 EWS_BEV_2_ANSW_3 "Immobilizer - no detailed description";
CM_ SG_ 161 EWS_BEV_2_ANSW_4 "Immobilizer - no detailed description";
CM_ BO_ 162 "-";
CM_ SG_ 162 BMS_PackLowVolErr "Pack Voltage Ýs Lower Than The Permittable Values";
CM_ SG_ 162 BMS_PackOverCurrErr "When The Over Current Ýs Detected During Charging And Discharging For The Given Period Of Time, Then The Bms_Packovercurr_Err Will Set ";
CM_ SG_ 162 CRC_BMS_Error "Checksum";
CM_ SG_ 162 ALV_BMS_Error "Alive Counter";
CM_ SG_ 162 BMS_CellLowVolErr "Under Voltage Of The Cell Ýs Detected";
CM_ SG_ 162 BMS_HVILErr "High Voltage Interlock Loop Circuit Error";
CM_ SG_ 162 BMS_FuseStatusErr "Fuse And Pyro Fuse Blowup Status";
CM_ SG_ 162 BMS_ProbeHighTempErr "Over Temperature Of The Cell Ýs Detected";
CM_ SG_ 162 BMS_CellHighVolErr "Over Voltage Of The Cell Ýs Detected";
CM_ SG_ 162 BMS_ProbeLowTempErr "Under Temperature Of The Cell Ýs Detected ";
CM_ SG_ 162 BMS_PackHighVolErr "Pack Voltage Ýs Higher Than The Permittable Values";
CM_ SG_ 162 BMS_ProbeTempDiffErr "The Difference Ýn Temperture Between Max And Min Ýs Beyound The Permissable Limit";
CM_ SG_ 162 BMS_CellVoltDiffErr "Max And Min Cell Voltage Difference Ýs Too Large";
CM_ SG_ 162 BMS_PackInsuErr "Insulation Check Lines Have Problems, Short To Ground Or Short To Bat";
CM_ BO_ 166 "-";
CM_ SG_ 166 CHL_WMOM_DRV_9 "This signal explicitly contains the value of the extension ID = 10 dec = A (hex) for the extended standard validation application CRC and corresponds to bit 12-15 of the application data ID CRC ID of the corresponding CRC signal.";
CM_ SG_ 166 ALIV_WMOM_DRV_9 "Standard alive counter validation";
CM_ SG_ 166 CRC_WMOM_DRV_9 "This signal contains the CRC checksum for the extended standard application CRC validation according to application profile 1C E2E Protection Autosar SWS 428.";
CM_ SG_ 166 TAR_WMOM_PT_SUM_COOTD "Output variable from the driver's request coordination between the driver's request via the accelerator pedal and the wheel torque request of the comfort systems.";
CM_ BO_ 167 "--";
CM_ SG_ 167 EWS_GLB_7 "Immobilizer - no detailed description";
CM_ SG_ 167 EWS_GLB_1 "Immobilizer - no detailed description";
CM_ SG_ 167 EWS_GLB_2 "Immobilizer - no detailed description";
CM_ SG_ 167 EWS_GLB_3 "Immobilizer - no detailed description";
CM_ SG_ 167 EWS_GLB_6 "Immobilizer - no detailed description";
CM_ SG_ 167 EWS_GLB_0 "Immobilizer - no detailed description";
CM_ SG_ 167 EWS_GLB_5 "Immobilizer - no detailed description";
CM_ SG_ 167 EWS_GLB_4 "Immobilizer - no detailed description";
CM_ SG_ 168 ALV_BMS_HVMeas "Alive Counter";
CM_ SG_ 168 BMS_HVFuseVol "Measure DC Voltage after DC charge relay (VD-->V3)";
CM_ SG_ 168 BMS_DCPlugVol "Measure DC Voltage after DC charge relay (VD-->V3)";
CM_ BO_ 170 "-";
CM_ SG_ 170 QualifierRpmEmETractSys2ActVal "Signal quality of the signal RpmEmETractSys2ActualValue.";
CM_ SG_ 170 DirOfRotETractSys2ActVal "Actual rotational direction of electric machine system 2.";
CM_ SG_ 170 TqEmETractSys2MotorSumLimTarget "Cumulated and limited target torque of the electric motor of electric machine system 2.";
CM_ SG_ 170 StatusLockPositionPbWETractSys2 "Position status of the parking lock on electric machine 2.";
CM_ SG_ 170 TorqueEmETractSys2ActualValue "Actual torque of the electric motor of electric machine system 2.
";
CM_ SG_ 170 TorqueEmETractSys2MotorDynamic "Maximum possible motorized electrical machine torque of electric machine system 2 including the assigned performance/voltage limits, depending on the specific component.";
CM_ SG_ 170 TqEmETractSys2GeneratorDynamic "Maximum possible generative electrical machine torque of electric machine system 2 including the assigned performance/voltage limits, depending on the specific component.";
CM_ SG_ 170 TqEmETractSys2GeneratorStatic "Maximum possible generative electrical machine torque of electric machine system 2 excluding the assigned performance/voltage limits, depending on the specific component.";
CM_ SG_ 170 RpmEmETractSys2ActualValue "Note: This signal and its content shall not be read, changed or deleted without consulting the FuSi department at EA.";
CM_ SG_ 170 TqEmETractSys2VibrationDampSusp "Requested torque reserve for vibration damping for the electric motor of electric machine system 2.";
CM_ SG_ 170 RpmEmETractSys2MinimumLimit "Lower speed limit of the electric motor of electric system 2.";
CM_ SG_ 170 RpmEmETractSys2MaximumLimit "Upper speed limit of the electric motor of electric machine system 2.";
CM_ SG_ 170 VolDrctCurrETractSys2ActVal "Actual voltage of the intermediate circuit of electric machine system 2.";
CM_ SG_ 170 CurrDrctCurrETractSys2ActVal "Actual DC current of electric machine system 2.";
CM_ SG_ 170 ALIV_TracEMacElectc2Time10msNo1 "Standard alive counter validation as per definition in the requirements specification Allgemeine Bordnetzkommunikation.";
CM_ SG_ 170 CRC_TracEMacElectc2Time10msNo1 "This signal contains the CRC checksum for the standard validation with application CRC-16 according to the definition as per requirements specification Bordnetzkommunikation. 
The signal uses application data ID (16 bit) 40 (dec) = 28 (hex).";
CM_ SG_ 170 TorqueEmETractSys2MotorStatic "Maximum possible motorized electrical machine torque of electric machine system 2 excluding the assigned performance/voltage limits, depending on the specific component.";
CM_ SG_ 170 QualifierTqEmETractSys2ActVal "Signal quality of the signal TorqueEmETractSys2ActualValue.";
CM_ SG_ 170 OVCUrrenceStatorPWMETractSys2 "This signal indicates if PWM has been applied to the stator in the last 10 ms.";
CM_ SG_ 170 StETractSys2Asd "The signal describes the reason for the deactivation of the active vibration damping function in electric machine system 2.";
CM_ SG_ 170 Qu_CurrDrctCurrETractSys2ActVal "Signal quality of the signal CurrentDirectCurrentETractSys2ActualValue.";
CM_ SG_ 170 StatusArbRpmETractSys2Limit "Status of the speed delimiter through actuator-related wheel slip limitation function for electric machine system 2.
Fixed Value = 0";
CM_ SG_ 170 SumWhlTqIntvETractSys2 "Wheel torque intervention sum (amount) of the wheel slip delimiter that is located in proximity to the actuator for electric machine system 2.";
CM_ SG_ 170 StatusPbWETractSys2 "Error status of the parking lock on electric machine 2.
Fixed Value = 0
";
CM_ SG_ 170 PowerETractSys2LossActualValue "Actual power loss of electric machine system 2.";
CM_ SG_ 170 TarTqETractSys2NControlStatic "Target torque speed controller slow portion.";
CM_ SG_ 170 PwrLossPrednETractSys2Mot "Forecast power loss in the current maximum possible motorized operating point of electric machine system 2.";
CM_ SG_ 170 PwrLossPrednETractSys2Genr "Forecast power loss in the current maximum possible generative operating point of electric machine system 2.";
CM_ BO_ 172 "-";
CM_ SG_ 172 BMS_MaxDischgCurrentLimPeak "Allowed Discharge Current (Peak)";
CM_ SG_ 172 BMS_MaxDischgPwrLimPeak "Allowed Discharge Power  Peak";
CM_ SG_ 172 ALV_BMS_PowerCont "Alive counter";
CM_ SG_ 172 BMS_MaxDischgCurrentLim "Allowed Discharge Current (Continuous)";
CM_ SG_ 172 BMS_MaxDischgPwr30s "Allowed Discharge Power (30seconds)";
CM_ SG_ 172 BMS_MaxDischgPwr10s "Allowed Discharge Power (10seconds)";
CM_ SG_ 172 BMS_MaxDischgPwr2s "Allowed Discharge Power (2seconds)";
CM_ SG_ 172 BMS_MaxDischgPwrLim "Allowed Discharge Power (Continuous)";
CM_ SG_ 172 BMS_MaxDischgCurrent30s "Allowed Discharge Current (30seconds)";
CM_ SG_ 172 BMS_MaxDischgCurrent10s "Allowed Discharge Current (10seconds)";
CM_ SG_ 172 BMS_MaxDischgCurrent2s "Allowed Discharge Current (2seconds)";
CM_ SG_ 172 CRC_BMS_PowerCont "Checksum";
CM_ BO_ 177 "-";
CM_ SG_ 177 ALV_BMS_RelayStatus "Alive counter";
CM_ SG_ 177 BMS_MainPosRelayStatus "Main Positive Relay Status ";
CM_ SG_ 177 BMS_PreChgRelayStatus "PreCharge Relay Status ";
CM_ SG_ 177 BMS_TotalNegRelayStatus "Main Negative Relay Status ";
CM_ SG_ 177 BMS_MainPosRelayErr "Main Position Relay Error ";
CM_ SG_ 177 BMS_TotalNegRelayErr "Main Negative Relay Error ";
CM_ SG_ 177 BMS_PreChgRelayErr "PreCharge Relay Error";
CM_ SG_ 177 CRC_BMS_RelayStatus "Checksum";
CM_ BO_ 182 "-";
CM_ SG_ 182 BMS_HVOnOffSts "Status of the High Voltage";
CM_ SG_ 182 BMS_BatBalanceErr "Battery Balance Error indicates Balancing switch is short or open";
CM_ SG_ 182 BMS_ErrLev "BMS requesting VCU to operate at the limited operating strategy (LOS)";
CM_ SG_ 182 BMS_DisconnectRequestRsn "Reason for contactor off request";
CM_ SG_ 182 BMS_EmergencyDisconnectRsn "Reson for emergency disconnect request";
CM_ SG_ 182 BMS_LimpHomeRsn "Reason for limp home mode request";
CM_ SG_ 182 BMS_HVILSts "The HVIL state of BMS";
CM_ SG_ 182 BMS_HWCrashSts "Battery Pack Hardware Crash signal Status";
CM_ SG_ 182 BMS_SOE "BMS State Of Enegy ";
CM_ SG_ 182 BMS_BalanceSts "BMS Balance Status ";
CM_ SG_ 182 BMS_SocRelativeEst "Relative SOC ";
CM_ SG_ 182 BMS_SocActualEst "Actual SOC ";
CM_ SG_ 182 BMS_SysSts "BMS_Status(Self-test after BMS wake-up) ";
CM_ SG_ 182 CRC_BMS_Sts "Checksum";
CM_ SG_ 182 ALV_BMS_Sts "Alive counter";
CM_ SG_ 182 BMS_IGNSts "the ignition signal status (on/off)";
CM_ SG_ 182 BMS_SOH "BMS State Of Health ";
CM_ BO_ 187 "-";
CM_ SG_ 187 BMS_Reserved_signal2 "Warning Message Flag, Component Owner, Supplier Align And Define For This Signal";
CM_ SG_ 187 BMS_Warning_Flag_5 "Warning Message Flag, Component Owner, Supplier Align And Define For This Signal";
CM_ SG_ 187 BMS_Reserved_signal5 "Warning Message Flag, Component Owner, Supplier Align And Define For This Signal";
CM_ SG_ 187 BMS_Reserved_signal4 "Warning Message Flag, Component Owner, Supplier Align And Define For This Signal";
CM_ SG_ 187 BMS_Reserved_signal3 "Warning Message Flag, Component Owner, Supplier Align And Define For This Signal";
CM_ SG_ 187 BMS_Reserved_signal1 "Warning Message Flag, Component Owner, Supplier Align And Define For This Signal";
CM_ SG_ 187 BMS_Warning_Flag_6 "Warning Message Flag, Component Owner, Supplier Align And Define For This Signal";
CM_ SG_ 187 BMS_MalfunctionSts "Malfunction Status Of Battery For Mhu Display";
CM_ SG_ 187 BMS_BatteryReplacement "Separate Signal To Ýndicate The Battery Replacement Ýnformation(Battery Replacement Mhu)";
CM_ SG_ 187 BMS_ThermalRunaway "Thermal Runaway Warning";
CM_ SG_ 187 BMS_PackTempSts "Pack Temperature Warning";
CM_ SG_ 187 ALV_BMS_WarnMsg "Alive Counter";
CM_ SG_ 187 BMS_Warning_Flag_7 "Warning Message Flag, Component Owner, Supplier Align And Define For This Signal";
CM_ SG_ 187 BMS_LowBattery "Low Battery Warning";
CM_ SG_ 187 BMS_Warning_Flag_8 "Warning Message Flag, Component Owner, Supplier Align And Define For This Signal";
CM_ SG_ 187 BMS_Warning_Flag_9 "Warning Message Flag, Component Owner, Supplier Align And Define For This Signal";
CM_ SG_ 187 CHSKM_BMS_WarnMsg "Checksum";
CM_ BO_ 213 "-";
CM_ SG_ 213 ALIV_ST_STAB_DSC "Standard alive counter validation as per definition in the requirements specification Allgemeine Bordnetzkommunikation.";
CM_ SG_ 213 QU_FN_FDR "FDR function qualifier.


The lowermost 3 bits of this signal can be assigned by the DSC for development purposes, but shall not be evaluated. Further details can be found in the components requirements specification DSC.";
CM_ SG_ 213 QU_FN_ABS "ABS function qualifier.

The lowermost 4 bits of this signal can be assigned by the DSC for development purposes, but shall not be evaluated. Further details can be found in the components requirements specification DSC.";
CM_ SG_ 213 QU_FN_ASC "ASC function qualifier. 


The lowermost bit of this signal can be assigned by the DSC for development purposes, but shall not be evaluated.

REMARK: Coding of Bit 1 in this signal is replaced by the new signal Status_Schlupf_Schwelle.";
CM_ SG_ 213 ST_BRG_DV "Status information regarding deceleration by the driver or by driver assistance systems or by a deceleration due to recuperation.";
CM_ SG_ 213 CRC_ST_STAB_DSC "Standard application CRC validation 
This signal uses the application CRC ID = 71 (dec)";
CM_ BO_ 214 "-";
CM_ SG_ 214 ST_SLIP_THO "This signal includes the axle-specific information indicating whether a slip threshold is exceeded on at least one wheel of the specified axle. 
REMARK: This signal replaces the coding of bit 1 in signal Qualifier_Funktion_ASC starting.
Fixed Value = 15";
CM_ BO_ 217 "-";
CM_ SG_ 217 CHL_WMOM_PT_AVL "This signal explicitly contains the value of the extension ID = 9 (dec) = 9 (hex) for the extended standard validation application CRC and corresponds to bit 12-15 of the application data ID (CRC ID) of the corresponding CRC signal.";
CM_ SG_ 217 ALIV_WMOM_PT_AVL "Standard alive counter validation";
CM_ SG_ 217 CRC_WMOM_PT_AVL "This signal contains the CRC checksum for the extended standard application CRC validation according to application profile 1C E2E Protection Autosar SWS 428.
The signal uses the application data ID 12 bit 2380 dec = 94C hex.";
CM_ SG_ 217 AVL_WMOM_PT_SUM "Currently driving cumulative wheel torque of the drivetrain.
In the case of hybrid vehicles, the signal also contains the electrical portion of the electric machine.";
CM_ SG_ 217 QU_AVL_WMOM_PT_SUM "Extended status qualifier for the signal Ist_Radmoment_Antriebsstrang_Summe.
Fixed Value = 2";
CM_ BO_ 249 "-";
CM_ SG_ 249 DCDC_MeasInCurrent "Input Current measure";
CM_ SG_ 249 DCDC_MeasInVltg "Input voltage measure";
CM_ SG_ 249 DCDC_MeasOutCurr "Output current measure";
CM_ SG_ 249 DCDC_MeasVs "Output voltage measure";
CM_ BO_ 254 "-";
CM_ SG_ 254 DCDC_MaxCurrentOut "Maximum current DCDC can output";
CM_ SG_ 254 DCDC_OutCurrReqFbk "Output Current Request Feedback";
CM_ SG_ 254 DCDC_OutVltgReqFbk "Output Vltg Request Feedback";
CM_ SG_ 254 DCDC_EnableDCDCFbk "SwEnable feedback";
CM_ BO_ 272 "-";
CM_ SG_ 272 ALV_VCU_ChargingConnectionSts "Alive Counter";
CM_ SG_ 272 VCU_AcChgGunIn "Slow Charge Gun Insert Status ";
CM_ SG_ 272 CRC_VCU_ChargingConnectionSts "Checksum";
CM_ SG_ 272 VCU_DCChgGunIn "Connection Status Of Dc Fast Charging Gun";
CM_ BO_ 289 "-";
CM_ SG_ 289 CRC_V_VEH "Standard application CRC validation
This signal uses application CRC ID = 12 (dec)";
CM_ SG_ 289 SecOcDataP2V_VEH "SecOC validation of PDU: V_VEH
Fixed value = 255
Invalid value = 1.84467e+19";
CM_ SG_ 289 QU_V_VEH_COG "Status qualifier for the signal Geschwindigkeit_Fahrzeug_Schwerpunkt.
Fixed Value = 1";
CM_ SG_ 289 V_VEH_COG "Absolute speed of the vehicle's center of gravity; contains the ratios from vehicle longitudinal and lateral speed.";
BA_DEF_ SG_  "SigFixedValue" STRING ;
BA_DEF_ BU_  "TpSTMin" INT 0 255;
BA_DEF_  "NmType" STRING ;
BA_DEF_  "NmAsrWaitBusSleepTime" INT 0 65535;
BA_DEF_  "NmAsrTimeoutTime" INT 0 65535;
BA_DEF_  "NmAsrRepeatMessageTime" INT 0 65535;
BA_DEF_ BU_  "NmAsrNodeIdentifier" HEX 0 255;
BA_DEF_ BU_  "NmAsrNode" ENUM  "No","Yes";
BA_DEF_  "NmAsrMessageCount" INT 1 256;
BA_DEF_ BU_  "NmAsrCanMsgReducedTime" INT 320 640;
BA_DEF_  "NmAsrCanMsgCycleTime" INT 0 65535;
BA_DEF_  "NmAsrBaseAddress" HEX 0 2047;
BA_DEF_ BU_  "ILUsed" ENUM  "No","Yes";
BA_DEF_ BO_  "GenMsgNrOfRepetition" INT 0 0;
BA_DEF_ BO_  "GenMsgILSupport" ENUM  "No","Yes";
BA_DEF_ BU_  "Address" HEX 0 255;
BA_DEF_ BO_  "VFrameFormat" ENUM  "StandardCAN","ExtendedCAN","reserved","reserved","reserved","reserved","reserved","reserved","reserved","reserved","reserved","reserved","reserved","reserved","StandardCAN_FD","ExtendedCAN_FD";
BA_DEF_ BU_  "ECU" STRING ;
BA_DEF_ BU_  "NmStationAddress" HEX 0 0;
BA_DEF_  "BusType" STRING ;
BA_DEF_  "DBName" STRING ;
BA_DEF_  "Manufacturer" ENUM  "CEER";
BA_DEF_  "Baudrate" INT 0 2000000;
BA_DEF_ BO_  "GenMsgSendType" ENUM  "Cyclic","NotUsed","NotUsed","NotUsed","NotUsed","NotUsed","NotUsed","IfActive","NoMsgSendType","NotUsed";
BA_DEF_ SG_  "GenSigSendType" ENUM  "Cyclic","OnWrite","OnWriteWithCyclic","OnChange","OnChangeWithCyclic","IfActive","IfActiveWithCyclic","NoSigSendType";
BA_DEF_ BO_  "GenMsgCycleTime" INT 0 0;
BA_DEF_ BO_  "GenMsgCycleTimeFast" INT 0 100000;
BA_DEF_ BO_  "DiagResponse" ENUM  "No","Yes";
BA_DEF_ BO_  "DiagRequest" ENUM  "No","Yes";
BA_DEF_ SG_  "CycleTime" INT 0 0;
BA_DEF_ SG_  "GenSigTimeoutTime" INT 0 0;
BA_DEF_ SG_  "InvalidValue" INT 0 2147483647;
BA_DEF_ SG_  "GenSigStartValue" INT 0 0;
BA_DEF_DEF_  "SigFixedValue" "NoFixedValue";
BA_DEF_DEF_  "TpSTMin" 20;
BA_DEF_DEF_  "NmType" "NmAsr";
BA_DEF_DEF_  "NmAsrWaitBusSleepTime" 1500;
BA_DEF_DEF_  "NmAsrTimeoutTime" 2000;
BA_DEF_DEF_  "NmAsrRepeatMessageTime" 3200;
BA_DEF_DEF_  "NmAsrNodeIdentifier" 0;
BA_DEF_DEF_  "NmAsrNode" "Yes";
BA_DEF_DEF_  "NmAsrMessageCount" 128;
BA_DEF_DEF_  "NmAsrCanMsgReducedTime" 320;
BA_DEF_DEF_  "NmAsrCanMsgCycleTime" 640;
BA_DEF_DEF_  "NmAsrBaseAddress" 1280;
BA_DEF_DEF_  "ILUsed" "Yes";
BA_DEF_DEF_  "GenMsgNrOfRepetition" 0;
BA_DEF_DEF_  "GenMsgILSupport" "Yes";
BA_DEF_DEF_  "Address" 0;
BA_DEF_DEF_  "VFrameFormat" "StandardCAN";
BA_DEF_DEF_  "ECU" "";
BA_DEF_DEF_  "NmStationAddress" 0;
BA_DEF_DEF_  "BusType" "";
BA_DEF_DEF_  "DBName" "";
BA_DEF_DEF_  "Manufacturer" "CEER";
BA_DEF_DEF_  "Baudrate" 500000;
BA_DEF_DEF_  "GenMsgSendType" "NoMsgSendType";
BA_DEF_DEF_  "GenSigSendType" "Cyclic";
BA_DEF_DEF_  "GenMsgCycleTime" 0;
BA_DEF_DEF_  "GenMsgCycleTimeFast" 0;
BA_DEF_DEF_  "DiagResponse" "No";
BA_DEF_DEF_  "DiagRequest" "No";
BA_DEF_DEF_  "CycleTime" 0;
BA_DEF_DEF_  "GenSigTimeoutTime" 0;
BA_DEF_DEF_  "InvalidValue" 0;
BA_DEF_DEF_  "GenSigStartValue" 0;
BA_ "BusType" "CAN FD";
BA_ "Baudrate" 2000000;
BA_ "DBName" "PT_CAN_FD";
BA_ "ECU" BU_ Tester "Diagnostic Tester";
BA_ "NmStationAddress" BU_ BMS 21;
BA_ "NmAsrNodeIdentifier" BU_ BMS 21;
BA_ "ECU" BU_ BMS "Battery Management System";
BA_ "NmStationAddress" BU_ VCU 4;
BA_ "NmAsrNodeIdentifier" BU_ VCU 4;
BA_ "ECU" BU_ VCU "Vehicle Control Unit";
BA_ "NmStationAddress" BU_ MCU_R 45;
BA_ "NmAsrNodeIdentifier" BU_ MCU_R 45;
BA_ "ECU" BU_ MCU_R "Motor Control Unit-Rear";
BA_ "NmStationAddress" BU_ MCU_F 44;
BA_ "NmAsrNodeIdentifier" BU_ MCU_F 44;
BA_ "ECU" BU_ MCU_F "Motor Control Unit-Front";
BA_ "NmStationAddress" BU_ PDU_DCDC 49;
BA_ "NmAsrNodeIdentifier" BU_ PDU_DCDC 49;
BA_ "ECU" BU_ PDU_DCDC "Power Distribution Unit - DC to DC Convertor (2in1)";
BA_ "NmStationAddress" BU_ OBC 26;
BA_ "NmAsrNodeIdentifier" BU_ OBC 26;
BA_ "ECU" BU_ OBC "On Board Charger";
BA_ "ECU" BU_ IMM "Immobilizer Simulator";
BA_ "Address" BU_ IMM 255;
BA_ "NmStationAddress" BU_ IMM 255;
BA_ "DiagRequest" BO_ 1777 1;
BA_ "VFrameFormat" BO_ 1777 14;
BA_ "DiagResponse" BO_ 1556 1;
BA_ "VFrameFormat" BO_ 1556 14;
BA_ "DiagResponse" BO_ 1647 1;
BA_ "VFrameFormat" BO_ 1647 14;
BA_ "DiagResponse" BO_ 1805 1;
BA_ "VFrameFormat" BO_ 1805 14;
BA_ "DiagRequest" BO_ 1933 1;
BA_ "VFrameFormat" BO_ 1933 14;
BA_ "DiagResponse" BO_ 1807 1;
BA_ "VFrameFormat" BO_ 1807 14;
BA_ "DiagRequest" BO_ 1935 1;
BA_ "VFrameFormat" BO_ 1935 14;
BA_ "DiagResponse" BO_ 1806 1;
BA_ "VFrameFormat" BO_ 1806 14;
BA_ "DiagRequest" BO_ 1934 1;
BA_ "VFrameFormat" BO_ 1934 14;
BA_ "GenMsgSendType" BO_ 501 0;
BA_ "GenMsgCycleTime" BO_ 501 10;
BA_ "VFrameFormat" BO_ 501 14;
BA_ "GenMsgSendType" BO_ 451 0;
BA_ "GenMsgCycleTime" BO_ 451 100;
BA_ "VFrameFormat" BO_ 451 14;
BA_ "GenMsgCycleTime" BO_ 411 100;
BA_ "GenMsgSendType" BO_ 411 0;
BA_ "VFrameFormat" BO_ 411 14;
BA_ "GenMsgCycleTime" BO_ 634 100;
BA_ "GenMsgSendType" BO_ 634 0;
BA_ "VFrameFormat" BO_ 634 14;
BA_ "GenMsgSendType" BO_ 395 0;
BA_ "GenMsgCycleTime" BO_ 395 100;
BA_ "VFrameFormat" BO_ 395 14;
BA_ "GenMsgCycleTime" BO_ 497 100;
BA_ "GenMsgSendType" BO_ 497 0;
BA_ "VFrameFormat" BO_ 497 14;
BA_ "GenMsgCycleTime" BO_ 60 100;
BA_ "GenMsgSendType" BO_ 60 0;
BA_ "VFrameFormat" BO_ 60 14;
BA_ "GenMsgCycleTime" BO_ 130 200;
BA_ "GenMsgSendType" BO_ 130 0;
BA_ "VFrameFormat" BO_ 130 14;
BA_ "GenMsgCycleTime" BO_ 131 5;
BA_ "GenMsgSendType" BO_ 131 0;
BA_ "VFrameFormat" BO_ 131 14;
BA_ "GenMsgCycleTime" BO_ 132 10;
BA_ "GenMsgSendType" BO_ 132 0;
BA_ "VFrameFormat" BO_ 132 14;
BA_ "GenMsgCycleTime" BO_ 137 10;
BA_ "GenMsgSendType" BO_ 137 0;
BA_ "VFrameFormat" BO_ 137 14;
BA_ "GenMsgCycleTime" BO_ 138 10;
BA_ "GenMsgSendType" BO_ 138 0;
BA_ "VFrameFormat" BO_ 138 14;
BA_ "GenMsgCycleTime" BO_ 141 10;
BA_ "GenMsgSendType" BO_ 141 0;
BA_ "VFrameFormat" BO_ 141 14;
BA_ "DiagResponse" BO_ 142 1;
BA_ "GenMsgCycleTime" BO_ 142 100;
BA_ "VFrameFormat" BO_ 142 14;
BA_ "GenMsgCycleTime" BO_ 143 10;
BA_ "GenMsgSendType" BO_ 143 0;
BA_ "VFrameFormat" BO_ 143 14;
BA_ "GenMsgCycleTime" BO_ 145 10;
BA_ "GenMsgSendType" BO_ 145 0;
BA_ "VFrameFormat" BO_ 145 14;
BA_ "GenMsgCycleTime" BO_ 146 5000;
BA_ "GenMsgSendType" BO_ 146 0;
BA_ "VFrameFormat" BO_ 146 14;
BA_ "DiagResponse" BO_ 147 1;
BA_ "GenMsgCycleTime" BO_ 147 100;
BA_ "VFrameFormat" BO_ 147 14;
BA_ "DiagResponse" BO_ 153 1;
BA_ "GenMsgCycleTime" BO_ 153 100;
BA_ "VFrameFormat" BO_ 153 14;
BA_ "VFrameFormat" BO_ 155 14;
BA_ "VFrameFormat" BO_ 156 14;
BA_ "DiagResponse" BO_ 157 1;
BA_ "GenMsgCycleTime" BO_ 157 100;
BA_ "VFrameFormat" BO_ 157 14;
BA_ "VFrameFormat" BO_ 160 14;
BA_ "VFrameFormat" BO_ 161 14;
BA_ "GenMsgCycleTime" BO_ 162 10;
BA_ "GenMsgSendType" BO_ 162 0;
BA_ "VFrameFormat" BO_ 162 14;
BA_ "GenMsgCycleTime" BO_ 166 10;
BA_ "GenMsgSendType" BO_ 166 0;
BA_ "VFrameFormat" BO_ 166 14;
BA_ "GenMsgCycleTime" BO_ 167 10;
BA_ "GenMsgSendType" BO_ 167 0;
BA_ "VFrameFormat" BO_ 167 14;
BA_ "GenMsgCycleTime" BO_ 168 10;
BA_ "GenMsgSendType" BO_ 168 0;
BA_ "VFrameFormat" BO_ 168 14;
BA_ "GenMsgCycleTime" BO_ 170 10;
BA_ "GenMsgSendType" BO_ 170 0;
BA_ "VFrameFormat" BO_ 170 14;
BA_ "GenMsgCycleTime" BO_ 172 10;
BA_ "GenMsgSendType" BO_ 172 0;
BA_ "VFrameFormat" BO_ 172 14;
BA_ "GenMsgCycleTime" BO_ 177 10;
BA_ "GenMsgSendType" BO_ 177 0;
BA_ "VFrameFormat" BO_ 177 14;
BA_ "GenMsgCycleTime" BO_ 182 10;
BA_ "GenMsgSendType" BO_ 182 0;
BA_ "VFrameFormat" BO_ 182 14;
BA_ "GenMsgCycleTime" BO_ 187 10;
BA_ "GenMsgSendType" BO_ 187 0;
BA_ "VFrameFormat" BO_ 187 14;
BA_ "GenMsgCycleTime" BO_ 213 50;
BA_ "GenMsgSendType" BO_ 213 0;
BA_ "VFrameFormat" BO_ 213 14;
BA_ "GenMsgCycleTime" BO_ 214 100;
BA_ "GenMsgSendType" BO_ 214 0;
BA_ "VFrameFormat" BO_ 214 14;
BA_ "GenMsgCycleTime" BO_ 217 10;
BA_ "GenMsgSendType" BO_ 217 0;
BA_ "VFrameFormat" BO_ 217 14;
BA_ "GenMsgCycleTime" BO_ 249 10;
BA_ "GenMsgSendType" BO_ 249 0;
BA_ "VFrameFormat" BO_ 249 14;
BA_ "GenMsgCycleTime" BO_ 254 10;
BA_ "GenMsgSendType" BO_ 254 0;
BA_ "VFrameFormat" BO_ 254 14;
BA_ "GenMsgCycleTime" BO_ 272 50;
BA_ "GenMsgSendType" BO_ 272 0;
BA_ "VFrameFormat" BO_ 272 14;
BA_ "GenMsgCycleTime" BO_ 289 20;
BA_ "GenMsgSendType" BO_ 289 0;
BA_ "VFrameFormat" BO_ 289 14;
BA_ "GenSigSendType" SG_ 1777 Tester_DiagReq_Byte7 7;
BA_ "GenSigSendType" SG_ 1777 Tester_DiagReq_Byte6 7;
BA_ "GenSigSendType" SG_ 1777 Tester_DiagReq_Byte5 7;
BA_ "GenSigSendType" SG_ 1777 Tester_DiagReq_Byte4 7;
BA_ "GenSigSendType" SG_ 1777 Tester_DiagReq_Byte3 7;
BA_ "GenSigSendType" SG_ 1777 Tester_DiagReq_Byte2 7;
BA_ "GenSigSendType" SG_ 1777 Tester_DiagReq_Byte1 7;
BA_ "GenSigSendType" SG_ 1777 Tester_DiagReq_Byte0 7;
BA_ "GenSigSendType" SG_ 1556 MCU_R_DiagResp_Byte7 7;
BA_ "GenSigSendType" SG_ 1556 MCU_R_DiagResp_Byte6 7;
BA_ "GenSigSendType" SG_ 1556 MCU_R_DiagResp_Byte5 7;
BA_ "GenSigSendType" SG_ 1556 MCU_R_DiagResp_Byte4 7;
BA_ "GenSigSendType" SG_ 1556 MCU_R_DiagResp_Byte3 7;
BA_ "GenSigSendType" SG_ 1556 MCU_R_DiagResp_Byte2 7;
BA_ "GenSigSendType" SG_ 1556 MCU_R_DiagResp_Byte1 7;
BA_ "GenSigSendType" SG_ 1556 MCU_R_DiagResp_Byte0 7;
BA_ "GenSigSendType" SG_ 1647 MCU_F_DiagResp_Byte7 7;
BA_ "GenSigSendType" SG_ 1647 MCU_F_DiagResp_Byte6 7;
BA_ "GenSigSendType" SG_ 1647 MCU_F_DiagResp_Byte5 7;
BA_ "GenSigSendType" SG_ 1647 MCU_F_DiagResp_Byte4 7;
BA_ "GenSigSendType" SG_ 1647 MCU_F_DiagResp_Byte3 7;
BA_ "GenSigSendType" SG_ 1647 MCU_F_DiagResp_Byte2 7;
BA_ "GenSigSendType" SG_ 1647 MCU_F_DiagResp_Byte1 7;
BA_ "GenSigSendType" SG_ 1647 MCU_F_DiagResp_Byte0 7;
BA_ "GenSigSendType" SG_ 1807 VCU_XCP_Response_Byte7 7;
BA_ "GenSigSendType" SG_ 1807 VCU_XCP_Response_Byte6 7;
BA_ "GenSigSendType" SG_ 1807 VCU_XCP_Response_Byte5 7;
BA_ "GenSigSendType" SG_ 1807 VCU_XCP_Response_Byte4 7;
BA_ "GenSigSendType" SG_ 1807 VCU_XCP_Response_Byte3 7;
BA_ "GenSigSendType" SG_ 1807 VCU_XCP_Response_Byte2 7;
BA_ "GenSigSendType" SG_ 1807 VCU_XCP_Response_Byte1 7;
BA_ "GenSigSendType" SG_ 1807 VCU_XCP_Response_Byte0 7;
BA_ "GenSigSendType" SG_ 1935 VCU_XCP_Request_Byte7 7;
BA_ "GenSigSendType" SG_ 1935 VCU_XCP_Request_Byte6 7;
BA_ "GenSigSendType" SG_ 1935 VCU_XCP_Request_Byte5 7;
BA_ "GenSigSendType" SG_ 1935 VCU_XCP_Request_Byte4 7;
BA_ "GenSigSendType" SG_ 1935 VCU_XCP_Request_Byte3 7;
BA_ "GenSigSendType" SG_ 1935 VCU_XCP_Request_Byte2 7;
BA_ "GenSigSendType" SG_ 1935 VCU_XCP_Request_Byte1 7;
BA_ "GenSigSendType" SG_ 1935 VCU_XCP_Request_Byte0 7;
BA_ "GenSigSendType" SG_ 1806 OBC_XCP_Response_Byte7 7;
BA_ "GenSigSendType" SG_ 1806 OBC_XCP_Response_Byte6 7;
BA_ "GenSigSendType" SG_ 1806 OBC_XCP_Response_Byte5 7;
BA_ "GenSigSendType" SG_ 1806 OBC_XCP_Response_Byte4 7;
BA_ "GenSigSendType" SG_ 1806 OBC_XCP_Response_Byte3 7;
BA_ "GenSigSendType" SG_ 1806 OBC_XCP_Response_Byte2 7;
BA_ "GenSigSendType" SG_ 1806 OBC_XCP_Response_Byte1 7;
BA_ "GenSigSendType" SG_ 1806 OBC_XCP_Response_Byte0 7;
BA_ "GenSigSendType" SG_ 1934 OBC_XCP_Request_Byte7 7;
BA_ "GenSigSendType" SG_ 1934 OBC_XCP_Request_Byte6 7;
BA_ "GenSigSendType" SG_ 1934 OBC_XCP_Request_Byte5 7;
BA_ "GenSigSendType" SG_ 1934 OBC_XCP_Request_Byte4 7;
BA_ "GenSigSendType" SG_ 1934 OBC_XCP_Request_Byte3 7;
BA_ "GenSigSendType" SG_ 1934 OBC_XCP_Request_Byte2 7;
BA_ "GenSigSendType" SG_ 1934 OBC_XCP_Request_Byte1 7;
BA_ "GenSigSendType" SG_ 1934 OBC_XCP_Request_Byte0 7;
BA_ "GenSigTimeoutTime" SG_ 501 VCU_HV_SystemStatus 50;
BA_ "InvalidValue" SG_ 501 VCU_HV_SystemStatus 7;
BA_ "GenSigStartValue" SG_ 451 VCU_LTROutLetTemp 255;
BA_ "InvalidValue" SG_ 451 VCU_LTROutLetTemp 255;
BA_ "InvalidValue" SG_ 411 OBC_SeqSta 255;
BA_ "GenSigTimeoutTime" SG_ 411 OBC_SeqSta 500;
BA_ "CycleTime" SG_ 411 OBC_SeqSta 100;
BA_ "InvalidValue" SG_ 411 OBC_HvIntlkStatus 3;
BA_ "GenSigTimeoutTime" SG_ 411 OBC_HvIntlkStatus 500;
BA_ "CycleTime" SG_ 411 OBC_HvIntlkStatus 100;
BA_ "InvalidValue" SG_ 634 DCDC_SysOpSta 255;
BA_ "GenSigTimeoutTime" SG_ 634 DCDC_SysOpSta 500;
BA_ "CycleTime" SG_ 634 DCDC_SysOpSta 100;
BA_ "InvalidValue" SG_ 634 DCDC_HvIntlkStatus 3;
BA_ "GenSigTimeoutTime" SG_ 634 DCDC_HvIntlkStatus 500;
BA_ "CycleTime" SG_ 634 DCDC_HvIntlkStatus 100;
BA_ "CycleTime" SG_ 395 BMS_CellTemp48 100;
BA_ "GenSigTimeoutTime" SG_ 395 BMS_CellTemp48 500;
BA_ "InvalidValue" SG_ 395 BMS_CellTemp48 1023;
BA_ "GenSigStartValue" SG_ 395 BMS_CellTemp48 680;
BA_ "CycleTime" SG_ 395 BMS_CellTemp47 100;
BA_ "GenSigTimeoutTime" SG_ 395 BMS_CellTemp47 500;
BA_ "InvalidValue" SG_ 395 BMS_CellTemp47 1023;
BA_ "GenSigStartValue" SG_ 395 BMS_CellTemp47 680;
BA_ "CycleTime" SG_ 395 BMS_CellTemp46 100;
BA_ "GenSigTimeoutTime" SG_ 395 BMS_CellTemp46 500;
BA_ "InvalidValue" SG_ 395 BMS_CellTemp46 1023;
BA_ "GenSigStartValue" SG_ 395 BMS_CellTemp46 680;
BA_ "CycleTime" SG_ 395 BMS_CellTemp45 100;
BA_ "GenSigTimeoutTime" SG_ 395 BMS_CellTemp45 500;
BA_ "InvalidValue" SG_ 395 BMS_CellTemp45 1023;
BA_ "GenSigStartValue" SG_ 395 BMS_CellTemp45 680;
BA_ "CycleTime" SG_ 395 BMS_CellTemp44 100;
BA_ "GenSigTimeoutTime" SG_ 395 BMS_CellTemp44 500;
BA_ "InvalidValue" SG_ 395 BMS_CellTemp44 1023;
BA_ "GenSigStartValue" SG_ 395 BMS_CellTemp44 680;
BA_ "CycleTime" SG_ 395 BMS_CellTemp43 100;
BA_ "GenSigTimeoutTime" SG_ 395 BMS_CellTemp43 500;
BA_ "InvalidValue" SG_ 395 BMS_CellTemp43 1023;
BA_ "GenSigStartValue" SG_ 395 BMS_CellTemp43 680;
BA_ "CycleTime" SG_ 395 BMS_CellTemp42 100;
BA_ "GenSigTimeoutTime" SG_ 395 BMS_CellTemp42 500;
BA_ "InvalidValue" SG_ 395 BMS_CellTemp42 1023;
BA_ "GenSigStartValue" SG_ 395 BMS_CellTemp42 680;
BA_ "CycleTime" SG_ 395 CRC_BMS_CellTempMeas2 100;
BA_ "GenSigTimeoutTime" SG_ 395 CRC_BMS_CellTempMeas2 500;
BA_ "CycleTime" SG_ 395 ALV_BMS_CellTempMeas2 100;
BA_ "GenSigTimeoutTime" SG_ 395 ALV_BMS_CellTempMeas2 500;
BA_ "InvalidValue" SG_ 395 ALV_BMS_CellTempMeas2 15;
BA_ "GenSigTimeoutTime" SG_ 497 CRC_CLAMP_STAT 500;
BA_ "CycleTime" SG_ 497 CRC_CLAMP_STAT 100;
BA_ "GenSigStartValue" SG_ 497 CRC_CLAMP_STAT 255;
BA_ "GenSigTimeoutTime" SG_ 497 ALIV_CLAMP_STAT 500;
BA_ "CycleTime" SG_ 497 ALIV_CLAMP_STAT 100;
BA_ "InvalidValue" SG_ 497 ALIV_CLAMP_STAT 15;
BA_ "GenSigTimeoutTime" SG_ 497 STAT_CL15_L 500;
BA_ "CycleTime" SG_ 497 STAT_CL15_L 100;
BA_ "InvalidValue" SG_ 497 STAT_CL15_L 3;
BA_ "GenSigTimeoutTime" SG_ 497 STAT_CL30S_L 500;
BA_ "CycleTime" SG_ 497 STAT_CL30S_L 100;
BA_ "SigFixedValue" SG_ 497 STAT_CL30S_L "0";
BA_ "InvalidValue" SG_ 497 STAT_CL30S_L 3;
BA_ "GenSigTimeoutTime" SG_ 497 STAT_CL30S_Light 500;
BA_ "CycleTime" SG_ 497 STAT_CL30S_Light 100;
BA_ "SigFixedValue" SG_ 497 STAT_CL30S_Light "0";
BA_ "InvalidValue" SG_ 497 STAT_CL30S_Light 3;
BA_ "GenSigTimeoutTime" SG_ 497 STAT_CL15_WUPL 500;
BA_ "CycleTime" SG_ 497 STAT_CL15_WUPL 100;
BA_ "SigFixedValue" SG_ 497 STAT_CL15_WUPL "0";
BA_ "InvalidValue" SG_ 497 STAT_CL15_WUPL 3;
BA_ "CycleTime" SG_ 60 CRC_CON_VEH 100;
BA_ "GenSigTimeoutTime" SG_ 60 CRC_CON_VEH 500;
BA_ "InvalidValue" SG_ 60 CRC_CON_VEH 255;
BA_ "GenSigStartValue" SG_ 60 CRC_CON_VEH 255;
BA_ "CycleTime" SG_ 60 ALIV_CON_VEH 100;
BA_ "GenSigTimeoutTime" SG_ 60 ALIV_CON_VEH 500;
BA_ "InvalidValue" SG_ 60 ALIV_CON_VEH 15;
BA_ "CycleTime" SG_ 60 CTR_BS_PRTNT 100;
BA_ "GenSigTimeoutTime" SG_ 60 CTR_BS_PRTNT 500;
BA_ "InvalidValue" SG_ 60 CTR_BS_PRTNT 15;
BA_ "GenSigStartValue" SG_ 60 CTR_BS_PRTNT 15;
BA_ "SigFixedValue" SG_ 60 CTR_FKTN_PRTNT "102912";
BA_ "CycleTime" SG_ 60 CTR_FKTN_PRTNT 100;
BA_ "GenSigTimeoutTime" SG_ 60 CTR_FKTN_PRTNT 500;
BA_ "GenSigStartValue" SG_ 60 CTR_FKTN_PRTNT 4294967295;
BA_ "CycleTime" SG_ 60 ST_CON_VEH 100;
BA_ "GenSigTimeoutTime" SG_ 60 ST_CON_VEH 500;
BA_ "InvalidValue" SG_ 60 ST_CON_VEH 15;
BA_ "GenSigStartValue" SG_ 60 ST_CON_VEH 15;
BA_ "SigFixedValue" SG_ 60 QU_ST_CON_VEH "2";
BA_ "CycleTime" SG_ 60 QU_ST_CON_VEH 100;
BA_ "GenSigTimeoutTime" SG_ 60 QU_ST_CON_VEH 500;
BA_ "InvalidValue" SG_ 60 QU_ST_CON_VEH 15;
BA_ "GenSigStartValue" SG_ 60 QU_ST_CON_VEH 15;
BA_ "CycleTime" SG_ 130 CRC_ST_CR 200;
BA_ "GenSigTimeoutTime" SG_ 130 CRC_ST_CR 1000;
BA_ "GenSigStartValue" SG_ 130 CRC_ST_CR 255;
BA_ "SigFixedValue" SG_ 130 ST_CRSE_REAR "0";
BA_ "CycleTime" SG_ 130 ST_CRSE_REAR 200;
BA_ "GenSigTimeoutTime" SG_ 130 ST_CRSE_REAR 1000;
BA_ "InvalidValue" SG_ 130 ST_CRSE_REAR 15;
BA_ "GenSigStartValue" SG_ 130 ST_CRSE_REAR 15;
BA_ "SigFixedValue" SG_ 130 ST_CRSE_ROV "0";
BA_ "CycleTime" SG_ 130 ST_CRSE_ROV 200;
BA_ "GenSigTimeoutTime" SG_ 130 ST_CRSE_ROV 1000;
BA_ "InvalidValue" SG_ 130 ST_CRSE_ROV 15;
BA_ "GenSigStartValue" SG_ 130 ST_CRSE_ROV 15;
BA_ "SigFixedValue" SG_ 130 ST_CRSE_SIDE_LH "0";
BA_ "CycleTime" SG_ 130 ST_CRSE_SIDE_LH 200;
BA_ "GenSigTimeoutTime" SG_ 130 ST_CRSE_SIDE_LH 1000;
BA_ "InvalidValue" SG_ 130 ST_CRSE_SIDE_LH 15;
BA_ "GenSigStartValue" SG_ 130 ST_CRSE_SIDE_LH 15;
BA_ "SigFixedValue" SG_ 130 ST_CRSE_SIDE_RH "0";
BA_ "CycleTime" SG_ 130 ST_CRSE_SIDE_RH 200;
BA_ "GenSigTimeoutTime" SG_ 130 ST_CRSE_SIDE_RH 1000;
BA_ "InvalidValue" SG_ 130 ST_CRSE_SIDE_RH 15;
BA_ "GenSigStartValue" SG_ 130 ST_CRSE_SIDE_RH 15;
BA_ "SigFixedValue" SG_ 130 ST_CRSE_FRT "0";
BA_ "CycleTime" SG_ 130 ST_CRSE_FRT 200;
BA_ "GenSigTimeoutTime" SG_ 130 ST_CRSE_FRT 1000;
BA_ "InvalidValue" SG_ 130 ST_CRSE_FRT 15;
BA_ "GenSigStartValue" SG_ 130 ST_CRSE_FRT 15;
BA_ "CycleTime" SG_ 130 ALIV_ST_CR 200;
BA_ "GenSigTimeoutTime" SG_ 130 ALIV_ST_CR 1000;
BA_ "InvalidValue" SG_ 130 ALIV_ST_CR 15;
BA_ "CycleTime" SG_ 131 CRC_AVL_RPM_WHL 5;
BA_ "GenSigTimeoutTime" SG_ 131 CRC_AVL_RPM_WHL 25;
BA_ "InvalidValue" SG_ 131 CRC_AVL_RPM_WHL 255;
BA_ "GenSigStartValue" SG_ 131 CRC_AVL_RPM_WHL 255;
BA_ "CycleTime" SG_ 131 ALIV_AVL_RPM_WHL 5;
BA_ "GenSigTimeoutTime" SG_ 131 ALIV_AVL_RPM_WHL 25;
BA_ "InvalidValue" SG_ 131 ALIV_AVL_RPM_WHL 15;
BA_ "CycleTime" SG_ 131 AVL_RPM_WHL_RLH 5;
BA_ "GenSigTimeoutTime" SG_ 131 AVL_RPM_WHL_RLH 25;
BA_ "InvalidValue" SG_ 131 AVL_RPM_WHL_RLH 65535;
BA_ "GenSigStartValue" SG_ 131 AVL_RPM_WHL_RLH 65535;
BA_ "CycleTime" SG_ 131 AVL_RPM_WHL_RRH 5;
BA_ "GenSigTimeoutTime" SG_ 131 AVL_RPM_WHL_RRH 25;
BA_ "InvalidValue" SG_ 131 AVL_RPM_WHL_RRH 65535;
BA_ "GenSigStartValue" SG_ 131 AVL_RPM_WHL_RRH 65535;
BA_ "CycleTime" SG_ 131 AVL_RPM_WHL_FLH 5;
BA_ "GenSigTimeoutTime" SG_ 131 AVL_RPM_WHL_FLH 25;
BA_ "InvalidValue" SG_ 131 AVL_RPM_WHL_FLH 65535;
BA_ "GenSigStartValue" SG_ 131 AVL_RPM_WHL_FLH 65535;
BA_ "CycleTime" SG_ 131 AVL_RPM_WHL_FRH 5;
BA_ "GenSigTimeoutTime" SG_ 131 AVL_RPM_WHL_FRH 25;
BA_ "InvalidValue" SG_ 131 AVL_RPM_WHL_FRH 65535;
BA_ "GenSigStartValue" SG_ 131 AVL_RPM_WHL_FRH 65535;
BA_ "SigFixedValue" SG_ 131 QU_AVL_RPM_WHL_RLH "1";
BA_ "CycleTime" SG_ 131 QU_AVL_RPM_WHL_RLH 5;
BA_ "GenSigTimeoutTime" SG_ 131 QU_AVL_RPM_WHL_RLH 25;
BA_ "InvalidValue" SG_ 131 QU_AVL_RPM_WHL_RLH 15;
BA_ "GenSigStartValue" SG_ 131 QU_AVL_RPM_WHL_RLH 8;
BA_ "SigFixedValue" SG_ 131 QU_AVL_RPM_WHL_RRH "1";
BA_ "CycleTime" SG_ 131 QU_AVL_RPM_WHL_RRH 5;
BA_ "GenSigTimeoutTime" SG_ 131 QU_AVL_RPM_WHL_RRH 25;
BA_ "InvalidValue" SG_ 131 QU_AVL_RPM_WHL_RRH 15;
BA_ "GenSigStartValue" SG_ 131 QU_AVL_RPM_WHL_RRH 8;
BA_ "SigFixedValue" SG_ 131 QU_AVL_RPM_WHL_FLH "1";
BA_ "CycleTime" SG_ 131 QU_AVL_RPM_WHL_FLH 5;
BA_ "GenSigTimeoutTime" SG_ 131 QU_AVL_RPM_WHL_FLH 25;
BA_ "InvalidValue" SG_ 131 QU_AVL_RPM_WHL_FLH 15;
BA_ "GenSigStartValue" SG_ 131 QU_AVL_RPM_WHL_FLH 8;
BA_ "SigFixedValue" SG_ 131 QU_AVL_RPM_WHL_FRH "1";
BA_ "CycleTime" SG_ 131 QU_AVL_RPM_WHL_FRH 5;
BA_ "GenSigTimeoutTime" SG_ 131 QU_AVL_RPM_WHL_FRH 25;
BA_ "InvalidValue" SG_ 131 QU_AVL_RPM_WHL_FRH 15;
BA_ "GenSigStartValue" SG_ 131 QU_AVL_RPM_WHL_FRH 8;
BA_ "CycleTime" SG_ 132 BMS_MaxChgCurrent10s 10;
BA_ "GenSigTimeoutTime" SG_ 132 BMS_MaxChgCurrent10s 50;
BA_ "InvalidValue" SG_ 132 BMS_MaxChgCurrent10s 8191;
BA_ "CycleTime" SG_ 132 CRC_BMS_ChgParamReq 10;
BA_ "GenSigTimeoutTime" SG_ 132 CRC_BMS_ChgParamReq 50;
BA_ "CycleTime" SG_ 132 BMS_MaxChgCurrent2s 10;
BA_ "GenSigTimeoutTime" SG_ 132 BMS_MaxChgCurrent2s 50;
BA_ "InvalidValue" SG_ 132 BMS_MaxChgCurrent2s 8191;
BA_ "CycleTime" SG_ 132 BMS_ChgVoltageReq 10;
BA_ "GenSigTimeoutTime" SG_ 132 BMS_ChgVoltageReq 50;
BA_ "InvalidValue" SG_ 132 BMS_ChgVoltageReq 16383;
BA_ "GenSigStartValue" SG_ 132 BMS_ChgVoltageReq 3450;
BA_ "CycleTime" SG_ 132 ALV_BMS_ChgParamReq 10;
BA_ "GenSigTimeoutTime" SG_ 132 ALV_BMS_ChgParamReq 50;
BA_ "InvalidValue" SG_ 132 ALV_BMS_ChgParamReq 15;
BA_ "CycleTime" SG_ 132 BMS_RemainChargeTime 10;
BA_ "GenSigTimeoutTime" SG_ 132 BMS_RemainChargeTime 50;
BA_ "InvalidValue" SG_ 132 BMS_RemainChargeTime 4095;
BA_ "CycleTime" SG_ 132 BMS_ChargeStopReq 10;
BA_ "GenSigTimeoutTime" SG_ 132 BMS_ChargeStopReq 50;
BA_ "CycleTime" SG_ 132 BMS_MaxChgPwr30s 10;
BA_ "GenSigTimeoutTime" SG_ 132 BMS_MaxChgPwr30s 50;
BA_ "InvalidValue" SG_ 132 BMS_MaxChgPwr30s 8191;
BA_ "CycleTime" SG_ 132 BMS_MaxChgPwr10s 10;
BA_ "GenSigTimeoutTime" SG_ 132 BMS_MaxChgPwr10s 50;
BA_ "InvalidValue" SG_ 132 BMS_MaxChgPwr10s 8191;
BA_ "CycleTime" SG_ 132 BMS_MaxChgPwr2s 10;
BA_ "GenSigTimeoutTime" SG_ 132 BMS_MaxChgPwr2s 50;
BA_ "InvalidValue" SG_ 132 BMS_MaxChgPwr2s 8191;
BA_ "CycleTime" SG_ 132 BMS_MaxChgCurrentLim 10;
BA_ "GenSigTimeoutTime" SG_ 132 BMS_MaxChgCurrentLim 50;
BA_ "InvalidValue" SG_ 132 BMS_MaxChgCurrentLim 8191;
BA_ "CycleTime" SG_ 132 BMS_MaxChgCurrent30s 10;
BA_ "GenSigTimeoutTime" SG_ 132 BMS_MaxChgCurrent30s 50;
BA_ "InvalidValue" SG_ 132 BMS_MaxChgCurrent30s 8191;
BA_ "CycleTime" SG_ 132 BMS_ChgCurrentReq 10;
BA_ "GenSigTimeoutTime" SG_ 132 BMS_ChgCurrentReq 50;
BA_ "InvalidValue" SG_ 132 BMS_ChgCurrentReq 1023;
BA_ "CycleTime" SG_ 132 BMS_MaxChgPwrLim 10;
BA_ "GenSigTimeoutTime" SG_ 132 BMS_MaxChgPwrLim 50;
BA_ "InvalidValue" SG_ 132 BMS_MaxChgPwrLim 8191;
BA_ "InvalidValue" SG_ 132 BMS_MaxChgCurrentLimPeak 8191;
BA_ "InvalidValue" SG_ 132 BMS_MaxChgPwrLimPeak 8191;
BA_ "CycleTime" SG_ 137 BMS_PackCurMeas 10;
BA_ "GenSigTimeoutTime" SG_ 137 BMS_PackCurMeas 50;
BA_ "InvalidValue" SG_ 137 BMS_PackCurMeas 65535;
BA_ "GenSigStartValue" SG_ 137 BMS_PackCurMeas 15000;
BA_ "CycleTime" SG_ 137 BMS_StartOfMeasument_STS 10;
BA_ "GenSigTimeoutTime" SG_ 137 BMS_StartOfMeasument_STS 50;
BA_ "CycleTime" SG_ 137 ALV_BMS_CurMeas 10;
BA_ "GenSigTimeoutTime" SG_ 137 ALV_BMS_CurMeas 50;
BA_ "InvalidValue" SG_ 137 ALV_BMS_CurMeas 15;
BA_ "CycleTime" SG_ 137 CRC_BMS_CurMeas 10;
BA_ "GenSigTimeoutTime" SG_ 137 CRC_BMS_CurMeas 50;
BA_ "CycleTime" SG_ 138 OperatingModeETract1Target 10;
BA_ "GenSigTimeoutTime" SG_ 138 OperatingModeETract1Target 50;
BA_ "InvalidValue" SG_ 138 OperatingModeETract1Target 255;
BA_ "GenSigStartValue" SG_ 138 OperatingModeETract1Target 255;
BA_ "CycleTime" SG_ 138 ALIV_CombinedChargerUnit10msNo3 10;
BA_ "GenSigTimeoutTime" SG_ 138 ALIV_CombinedChargerUnit10msNo3 50;
BA_ "InvalidValue" SG_ 138 ALIV_CombinedChargerUnit10msNo3 255;
BA_ "CycleTime" SG_ 138 CRC_CombinedChargerUnit10msNo3 10;
BA_ "GenSigTimeoutTime" SG_ 138 CRC_CombinedChargerUnit10msNo3 50;
BA_ "InvalidValue" SG_ 138 CRC_CombinedChargerUnit10msNo3 255;
BA_ "GenSigStartValue" SG_ 138 CRC_CombinedChargerUnit10msNo3 255;
BA_ "CycleTime" SG_ 138 OperatingModeETract2Target 10;
BA_ "GenSigTimeoutTime" SG_ 138 OperatingModeETract2Target 50;
BA_ "InvalidValue" SG_ 138 OperatingModeETract2Target 255;
BA_ "GenSigStartValue" SG_ 138 OperatingModeETract2Target 255;
BA_ "SigFixedValue" SG_ 141 SecOcDtP2CmbdChrgUnit10msNo1_3 "65535";
BA_ "CycleTime" SG_ 141 SecOcDtP2CmbdChrgUnit10msNo1_3 10;
BA_ "GenSigTimeoutTime" SG_ 141 SecOcDtP2CmbdChrgUnit10msNo1_3 50;
BA_ "GenSigStartValue" SG_ 141 SecOcDtP2CmbdChrgUnit10msNo1_3 65535;
BA_ "SigFixedValue" SG_ 141 SecOcDtP2CmbdChrgUnit10msNo1_2 "65535";
BA_ "CycleTime" SG_ 141 SecOcDtP2CmbdChrgUnit10msNo1_2 10;
BA_ "GenSigTimeoutTime" SG_ 141 SecOcDtP2CmbdChrgUnit10msNo1_2 50;
BA_ "GenSigStartValue" SG_ 141 SecOcDtP2CmbdChrgUnit10msNo1_2 65535;
BA_ "SigFixedValue" SG_ 141 SecOcDtP2CmbdChrgUnit10msNo1_1 "65535";
BA_ "CycleTime" SG_ 141 SecOcDtP2CmbdChrgUnit10msNo1_1 10;
BA_ "GenSigTimeoutTime" SG_ 141 SecOcDtP2CmbdChrgUnit10msNo1_1 50;
BA_ "GenSigStartValue" SG_ 141 SecOcDtP2CmbdChrgUnit10msNo1_1 65535;
BA_ "SigFixedValue" SG_ 141 TargetEMRpmETractSys2 "32767";
BA_ "CycleTime" SG_ 141 TargetEMRpmETractSys2 10;
BA_ "GenSigTimeoutTime" SG_ 141 TargetEMRpmETractSys2 50;
BA_ "InvalidValue" SG_ 141 TargetEMRpmETractSys2 65535;
BA_ "GenSigStartValue" SG_ 141 TargetEMRpmETractSys2 65535;
BA_ "CycleTime" SG_ 141 StatusReleaseTorqueVerified 10;
BA_ "GenSigTimeoutTime" SG_ 141 StatusReleaseTorqueVerified 50;
BA_ "InvalidValue" SG_ 141 StatusReleaseTorqueVerified 15;
BA_ "CycleTime" SG_ 141 SecOcDtP2CmbdChrgUnit10msNo1_0 10;
BA_ "GenSigTimeoutTime" SG_ 141 SecOcDtP2CmbdChrgUnit10msNo1_0 50;
BA_ "GenSigStartValue" SG_ 141 SecOcDtP2CmbdChrgUnit10msNo1_0 65535;
BA_ "SigFixedValue" SG_ 141 SecOcDtP2CmbdChrgUnit10msNo1_0 "65535";
BA_ "SigFixedValue" SG_ 141 StatusDampingVibration "0";
BA_ "CycleTime" SG_ 141 StatusDampingVibration 10;
BA_ "GenSigTimeoutTime" SG_ 141 StatusDampingVibration 50;
BA_ "InvalidValue" SG_ 141 StatusDampingVibration 15;
BA_ "GenSigStartValue" SG_ 141 StatusDampingVibration 15;
BA_ "CycleTime" SG_ 141 TorqBoundaryETractSys2EmNCtrlMin 10;
BA_ "GenSigTimeoutTime" SG_ 141 TorqBoundaryETractSys2EmNCtrlMin 50;
BA_ "InvalidValue" SG_ 141 TorqBoundaryETractSys2EmNCtrlMin 4095;
BA_ "GenSigStartValue" SG_ 141 TorqBoundaryETractSys2EmNCtrlMin 4095;
BA_ "SigFixedValue" SG_ 141 TorqBoundaryETractSys2EmNCtrlMin "-1023";
BA_ "CycleTime" SG_ 141 TorqBoundaryETractSys2EmNCtrlMax 10;
BA_ "GenSigTimeoutTime" SG_ 141 TorqBoundaryETractSys2EmNCtrlMax 50;
BA_ "InvalidValue" SG_ 141 TorqBoundaryETractSys2EmNCtrlMax 4095;
BA_ "GenSigStartValue" SG_ 141 TorqBoundaryETractSys2EmNCtrlMax 4095;
BA_ "SigFixedValue" SG_ 141 TorqBoundaryETractSys2EmNCtrlMax "1023";
BA_ "CycleTime" SG_ 141 TorqBoundaryETractSys1EmNCtrlMin 10;
BA_ "GenSigTimeoutTime" SG_ 141 TorqBoundaryETractSys1EmNCtrlMin 50;
BA_ "InvalidValue" SG_ 141 TorqBoundaryETractSys1EmNCtrlMin 4095;
BA_ "GenSigStartValue" SG_ 141 TorqBoundaryETractSys1EmNCtrlMin 4095;
BA_ "SigFixedValue" SG_ 141 TorqBoundaryETractSys1EmNCtrlMin "-1023";
BA_ "CycleTime" SG_ 141 TorqBoundaryETractSys1EmNCtrlMax 10;
BA_ "GenSigTimeoutTime" SG_ 141 TorqBoundaryETractSys1EmNCtrlMax 50;
BA_ "InvalidValue" SG_ 141 TorqBoundaryETractSys1EmNCtrlMax 4095;
BA_ "GenSigStartValue" SG_ 141 TorqBoundaryETractSys1EmNCtrlMax 4095;
BA_ "SigFixedValue" SG_ 141 TorqBoundaryETractSys1EmNCtrlMax "1023";
BA_ "CycleTime" SG_ 141 TargetTorqueEmETractSys2 10;
BA_ "GenSigTimeoutTime" SG_ 141 TargetTorqueEmETractSys2 50;
BA_ "InvalidValue" SG_ 141 TargetTorqueEmETractSys2 4095;
BA_ "GenSigStartValue" SG_ 141 TargetTorqueEmETractSys2 4095;
BA_ "SigFixedValue" SG_ 141 TargetTorqueEmETractSys2 "";
BA_ "SigFixedValue" SG_ 141 TargetEMRpmETractSys1 "32767";
BA_ "CycleTime" SG_ 141 TargetEMRpmETractSys1 10;
BA_ "GenSigTimeoutTime" SG_ 141 TargetEMRpmETractSys1 50;
BA_ "InvalidValue" SG_ 141 TargetEMRpmETractSys1 65535;
BA_ "GenSigStartValue" SG_ 141 TargetEMRpmETractSys1 65535;
BA_ "CycleTime" SG_ 141 TargetTorqueEmETractSys1 10;
BA_ "GenSigTimeoutTime" SG_ 141 TargetTorqueEmETractSys1 50;
BA_ "InvalidValue" SG_ 141 TargetTorqueEmETractSys1 4095;
BA_ "GenSigStartValue" SG_ 141 TargetTorqueEmETractSys1 4095;
BA_ "SigFixedValue" SG_ 141 TargetTorqueEmETractSys1 "";
BA_ "CycleTime" SG_ 141 CRC_CombinedChargerUnit10msNo1 10;
BA_ "GenSigTimeoutTime" SG_ 141 CRC_CombinedChargerUnit10msNo1 50;
BA_ "InvalidValue" SG_ 141 CRC_CombinedChargerUnit10msNo1 65535;
BA_ "GenSigStartValue" SG_ 141 CRC_CombinedChargerUnit10msNo1 65535;
BA_ "CycleTime" SG_ 141 ALIV_CombinedChargerUnit10msNo1 10;
BA_ "GenSigTimeoutTime" SG_ 141 ALIV_CombinedChargerUnit10msNo1 50;
BA_ "InvalidValue" SG_ 141 ALIV_CombinedChargerUnit10msNo1 255;
BA_ "CycleTime" SG_ 142 BMS_DebugSignal2 10;
BA_ "GenSigTimeoutTime" SG_ 142 BMS_DebugSignal2 50;
BA_ "CycleTime" SG_ 142 BMS_DebugSignal1 10;
BA_ "GenSigTimeoutTime" SG_ 142 BMS_DebugSignal1 50;
BA_ "CycleTime" SG_ 143 CRC_HighVoltageStorage10msNo2 10;
BA_ "GenSigTimeoutTime" SG_ 143 CRC_HighVoltageStorage10msNo2 50;
BA_ "GenSigStartValue" SG_ 143 CRC_HighVoltageStorage10msNo2 65535;
BA_ "CycleTime" SG_ 143 ALIV_HighVoltageStorage10msNo2 10;
BA_ "GenSigTimeoutTime" SG_ 143 ALIV_HighVoltageStorage10msNo2 50;
BA_ "InvalidValue" SG_ 143 ALIV_HighVoltageStorage10msNo2 255;
BA_ "CycleTime" SG_ 143 ActualValueVoltageLinkVerified 10;
BA_ "GenSigTimeoutTime" SG_ 143 ActualValueVoltageLinkVerified 50;
BA_ "InvalidValue" SG_ 143 ActualValueVoltageLinkVerified 4095;
BA_ "GenSigStartValue" SG_ 143 ActualValueVoltageLinkVerified 4095;
BA_ "CycleTime" SG_ 145 ALIV_TracEMacElectc1Time10msNo1 10;
BA_ "GenSigTimeoutTime" SG_ 145 ALIV_TracEMacElectc1Time10msNo1 50;
BA_ "InvalidValue" SG_ 145 ALIV_TracEMacElectc1Time10msNo1 255;
BA_ "CycleTime" SG_ 145 PwrLossPrednETractSys1Genr 10;
BA_ "GenSigTimeoutTime" SG_ 145 PwrLossPrednETractSys1Genr 50;
BA_ "InvalidValue" SG_ 145 PwrLossPrednETractSys1Genr 4095;
BA_ "GenSigStartValue" SG_ 145 PwrLossPrednETractSys1Genr 4095;
BA_ "CycleTime" SG_ 145 PwrLossPrednETractSys1Mot 10;
BA_ "GenSigTimeoutTime" SG_ 145 PwrLossPrednETractSys1Mot 50;
BA_ "InvalidValue" SG_ 145 PwrLossPrednETractSys1Mot 4095;
BA_ "GenSigStartValue" SG_ 145 PwrLossPrednETractSys1Mot 4095;
BA_ "CycleTime" SG_ 145 TarTqETractSys1NControlStatic 10;
BA_ "GenSigTimeoutTime" SG_ 145 TarTqETractSys1NControlStatic 50;
BA_ "InvalidValue" SG_ 145 TarTqETractSys1NControlStatic 1023;
BA_ "GenSigStartValue" SG_ 145 TarTqETractSys1NControlStatic 1023;
BA_ "CycleTime" SG_ 145 PowerETractSys1LossActualValue 10;
BA_ "GenSigTimeoutTime" SG_ 145 PowerETractSys1LossActualValue 50;
BA_ "InvalidValue" SG_ 145 PowerETractSys1LossActualValue 4095;
BA_ "GenSigStartValue" SG_ 145 PowerETractSys1LossActualValue 4095;
BA_ "CycleTime" SG_ 145 StETractSys1Asd 10;
BA_ "GenSigTimeoutTime" SG_ 145 StETractSys1Asd 50;
BA_ "InvalidValue" SG_ 145 StETractSys1Asd 65535;
BA_ "GenSigStartValue" SG_ 145 StETractSys1Asd 65535;
BA_ "CycleTime" SG_ 145 SumWhlTqIntvETractSys1 10;
BA_ "GenSigTimeoutTime" SG_ 145 SumWhlTqIntvETractSys1 50;
BA_ "InvalidValue" SG_ 145 SumWhlTqIntvETractSys1 4095;
BA_ "GenSigStartValue" SG_ 145 SumWhlTqIntvETractSys1 4095;
BA_ "CycleTime" SG_ 145 StatusArbRpmETractSys1Limit 10;
BA_ "GenSigTimeoutTime" SG_ 145 StatusArbRpmETractSys1Limit 50;
BA_ "InvalidValue" SG_ 145 StatusArbRpmETractSys1Limit 15;
BA_ "GenSigStartValue" SG_ 145 StatusArbRpmETractSys1Limit 15;
BA_ "SigFixedValue" SG_ 145 StatusArbRpmETractSys1Limit "0";
BA_ "CycleTime" SG_ 145 Qu_CurrDrctCurrETractSys1ActVal 10;
BA_ "GenSigTimeoutTime" SG_ 145 Qu_CurrDrctCurrETractSys1ActVal 50;
BA_ "InvalidValue" SG_ 145 Qu_CurrDrctCurrETractSys1ActVal 15;
BA_ "GenSigStartValue" SG_ 145 Qu_CurrDrctCurrETractSys1ActVal 15;
BA_ "CycleTime" SG_ 145 QualifierRpmEmETractSys1ActVal 10;
BA_ "GenSigTimeoutTime" SG_ 145 QualifierRpmEmETractSys1ActVal 50;
BA_ "InvalidValue" SG_ 145 QualifierRpmEmETractSys1ActVal 15;
BA_ "GenSigStartValue" SG_ 145 QualifierRpmEmETractSys1ActVal 15;
BA_ "CycleTime" SG_ 145 QualifierTqEmETractSys1ActVal 10;
BA_ "GenSigTimeoutTime" SG_ 145 QualifierTqEmETractSys1ActVal 50;
BA_ "InvalidValue" SG_ 145 QualifierTqEmETractSys1ActVal 15;
BA_ "GenSigStartValue" SG_ 145 QualifierTqEmETractSys1ActVal 15;
BA_ "CycleTime" SG_ 145 StatusPbWETractSys1 10;
BA_ "GenSigTimeoutTime" SG_ 145 StatusPbWETractSys1 50;
BA_ "InvalidValue" SG_ 145 StatusPbWETractSys1 255;
BA_ "GenSigStartValue" SG_ 145 StatusPbWETractSys1 255;
BA_ "CycleTime" SG_ 145 CRC_TracEMacElectc1Time10msNo1 10;
BA_ "GenSigTimeoutTime" SG_ 145 CRC_TracEMacElectc1Time10msNo1 50;
BA_ "GenSigStartValue" SG_ 145 CRC_TracEMacElectc1Time10msNo1 65535;
BA_ "CycleTime" SG_ 145 OVCUrrenceStatorPWMETractSys1 10;
BA_ "GenSigTimeoutTime" SG_ 145 OVCUrrenceStatorPWMETractSys1 50;
BA_ "InvalidValue" SG_ 145 OVCUrrenceStatorPWMETractSys1 3;
BA_ "GenSigStartValue" SG_ 145 OVCUrrenceStatorPWMETractSys1 3;
BA_ "CycleTime" SG_ 145 TqEmETractSys1MotorSumLimTarget 10;
BA_ "GenSigTimeoutTime" SG_ 145 TqEmETractSys1MotorSumLimTarget 50;
BA_ "InvalidValue" SG_ 145 TqEmETractSys1MotorSumLimTarget 4095;
BA_ "GenSigStartValue" SG_ 145 TqEmETractSys1MotorSumLimTarget 4095;
BA_ "CycleTime" SG_ 145 TorqueEmETractSys1ActualValue 10;
BA_ "GenSigTimeoutTime" SG_ 145 TorqueEmETractSys1ActualValue 50;
BA_ "InvalidValue" SG_ 145 TorqueEmETractSys1ActualValue 4095;
BA_ "GenSigStartValue" SG_ 145 TorqueEmETractSys1ActualValue 4095;
BA_ "CycleTime" SG_ 145 TorqueEmETractSys1MotorDynamic 10;
BA_ "GenSigTimeoutTime" SG_ 145 TorqueEmETractSys1MotorDynamic 50;
BA_ "InvalidValue" SG_ 145 TorqueEmETractSys1MotorDynamic 4095;
BA_ "GenSigStartValue" SG_ 145 TorqueEmETractSys1MotorDynamic 4095;
BA_ "CycleTime" SG_ 145 TorqueEmETractSys1MotorStatic 10;
BA_ "GenSigTimeoutTime" SG_ 145 TorqueEmETractSys1MotorStatic 50;
BA_ "InvalidValue" SG_ 145 TorqueEmETractSys1MotorStatic 4095;
BA_ "GenSigStartValue" SG_ 145 TorqueEmETractSys1MotorStatic 4095;
BA_ "CycleTime" SG_ 145 TqEmETractSys1GeneratorDynamic 10;
BA_ "GenSigTimeoutTime" SG_ 145 TqEmETractSys1GeneratorDynamic 50;
BA_ "InvalidValue" SG_ 145 TqEmETractSys1GeneratorDynamic 4095;
BA_ "GenSigStartValue" SG_ 145 TqEmETractSys1GeneratorDynamic 4095;
BA_ "CycleTime" SG_ 145 TqEmETractSys1GeneratorStatic 10;
BA_ "GenSigTimeoutTime" SG_ 145 TqEmETractSys1GeneratorStatic 50;
BA_ "InvalidValue" SG_ 145 TqEmETractSys1GeneratorStatic 4095;
BA_ "GenSigStartValue" SG_ 145 TqEmETractSys1GeneratorStatic 4095;
BA_ "CycleTime" SG_ 145 RpmEmETractSys1ActualValue 10;
BA_ "GenSigTimeoutTime" SG_ 145 RpmEmETractSys1ActualValue 50;
BA_ "InvalidValue" SG_ 145 RpmEmETractSys1ActualValue 65535;
BA_ "GenSigStartValue" SG_ 145 RpmEmETractSys1ActualValue 65535;
BA_ "CycleTime" SG_ 145 TqEmETractSys1VibrationDampSusp 10;
BA_ "GenSigTimeoutTime" SG_ 145 TqEmETractSys1VibrationDampSusp 50;
BA_ "InvalidValue" SG_ 145 TqEmETractSys1VibrationDampSusp 4095;
BA_ "GenSigStartValue" SG_ 145 TqEmETractSys1VibrationDampSusp 4095;
BA_ "CycleTime" SG_ 145 RpmEmETractSys1MinimumLimit 10;
BA_ "GenSigTimeoutTime" SG_ 145 RpmEmETractSys1MinimumLimit 50;
BA_ "InvalidValue" SG_ 145 RpmEmETractSys1MinimumLimit 65535;
BA_ "GenSigStartValue" SG_ 145 RpmEmETractSys1MinimumLimit 65535;
BA_ "CycleTime" SG_ 145 RpmEmETractSys1MaximumLimit 10;
BA_ "GenSigTimeoutTime" SG_ 145 RpmEmETractSys1MaximumLimit 50;
BA_ "InvalidValue" SG_ 145 RpmEmETractSys1MaximumLimit 65535;
BA_ "GenSigStartValue" SG_ 145 RpmEmETractSys1MaximumLimit 65535;
BA_ "CycleTime" SG_ 145 VolDrctCurrETractSys1ActVal 10;
BA_ "GenSigTimeoutTime" SG_ 145 VolDrctCurrETractSys1ActVal 50;
BA_ "InvalidValue" SG_ 145 VolDrctCurrETractSys1ActVal 4095;
BA_ "GenSigStartValue" SG_ 145 VolDrctCurrETractSys1ActVal 4095;
BA_ "CycleTime" SG_ 145 CurrDrctCurrETractSys1ActVal 10;
BA_ "GenSigTimeoutTime" SG_ 145 CurrDrctCurrETractSys1ActVal 50;
BA_ "InvalidValue" SG_ 145 CurrDrctCurrETractSys1ActVal 65535;
BA_ "GenSigStartValue" SG_ 145 CurrDrctCurrETractSys1ActVal 65535;
BA_ "CycleTime" SG_ 145 DirOfRotETractSys1ActVal 10;
BA_ "GenSigTimeoutTime" SG_ 145 DirOfRotETractSys1ActVal 50;
BA_ "InvalidValue" SG_ 145 DirOfRotETractSys1ActVal 3;
BA_ "GenSigStartValue" SG_ 145 DirOfRotETractSys1ActVal 3;
BA_ "CycleTime" SG_ 145 StatusLockPositionPbWETractSys1 10;
BA_ "GenSigTimeoutTime" SG_ 145 StatusLockPositionPbWETractSys1 50;
BA_ "InvalidValue" SG_ 145 StatusLockPositionPbWETractSys1 15;
BA_ "SigFixedValue" SG_ 146 CTR_ERRM_BN_U "0";
BA_ "CycleTime" SG_ 146 CTR_ERRM_BN_U 5000;
BA_ "GenSigTimeoutTime" SG_ 146 CTR_ERRM_BN_U 25000;
BA_ "InvalidValue" SG_ 146 CTR_ERRM_BN_U 63;
BA_ "GenSigStartValue" SG_ 146 CTR_ERRM_BN_U 63;
BA_ "CycleTime" SG_ 147 BMS_DebugSignal6 10;
BA_ "GenSigTimeoutTime" SG_ 147 BMS_DebugSignal6 50;
BA_ "CycleTime" SG_ 147 BMS_DebugSignal4 10;
BA_ "GenSigTimeoutTime" SG_ 147 BMS_DebugSignal4 50;
BA_ "CycleTime" SG_ 147 BMS_DebugSignal5 10;
BA_ "GenSigTimeoutTime" SG_ 147 BMS_DebugSignal5 50;
BA_ "CycleTime" SG_ 147 BMS_DebugSignal3 10;
BA_ "GenSigTimeoutTime" SG_ 147 BMS_DebugSignal3 50;
BA_ "CycleTime" SG_ 153 BMS_DebugSignal8 10;
BA_ "GenSigTimeoutTime" SG_ 153 BMS_DebugSignal8 50;
BA_ "CycleTime" SG_ 153 BMS_DebugSignal7 10;
BA_ "GenSigTimeoutTime" SG_ 153 BMS_DebugSignal7 50;
BA_ "CycleTime" SG_ 153 BMS_DebugSignal11 10;
BA_ "GenSigTimeoutTime" SG_ 153 BMS_DebugSignal11 50;
BA_ "CycleTime" SG_ 153 BMS_DebugSignal12 10;
BA_ "GenSigTimeoutTime" SG_ 153 BMS_DebugSignal12 50;
BA_ "CycleTime" SG_ 153 BMS_DebugSignal13 10;
BA_ "GenSigTimeoutTime" SG_ 153 BMS_DebugSignal13 50;
BA_ "CycleTime" SG_ 153 BMS_DebugSignal10 10;
BA_ "GenSigTimeoutTime" SG_ 153 BMS_DebugSignal10 50;
BA_ "CycleTime" SG_ 153 BMS_DebugSignal14 10;
BA_ "GenSigTimeoutTime" SG_ 153 BMS_DebugSignal14 50;
BA_ "CycleTime" SG_ 153 BMS_DebugSignal9 10;
BA_ "GenSigTimeoutTime" SG_ 153 BMS_DebugSignal9 50;
BA_ "GenSigSendType" SG_ 155 EWS_BEV_1_7 1;
BA_ "CycleTime" SG_ 155 EWS_BEV_1_7 10;
BA_ "GenSigTimeoutTime" SG_ 155 EWS_BEV_1_7 50;
BA_ "InvalidValue" SG_ 155 EWS_BEV_1_7 255;
BA_ "GenSigStartValue" SG_ 155 EWS_BEV_1_7 255;
BA_ "GenSigSendType" SG_ 155 EWS_BEV_1_6 1;
BA_ "CycleTime" SG_ 155 EWS_BEV_1_6 10;
BA_ "GenSigTimeoutTime" SG_ 155 EWS_BEV_1_6 50;
BA_ "InvalidValue" SG_ 155 EWS_BEV_1_6 255;
BA_ "GenSigStartValue" SG_ 155 EWS_BEV_1_6 255;
BA_ "GenSigSendType" SG_ 155 EWS_BEV_1_3 1;
BA_ "CycleTime" SG_ 155 EWS_BEV_1_3 10;
BA_ "GenSigTimeoutTime" SG_ 155 EWS_BEV_1_3 50;
BA_ "InvalidValue" SG_ 155 EWS_BEV_1_3 255;
BA_ "GenSigStartValue" SG_ 155 EWS_BEV_1_3 255;
BA_ "GenSigSendType" SG_ 155 EWS_BEV_1_2 1;
BA_ "CycleTime" SG_ 155 EWS_BEV_1_2 10;
BA_ "GenSigTimeoutTime" SG_ 155 EWS_BEV_1_2 50;
BA_ "InvalidValue" SG_ 155 EWS_BEV_1_2 255;
BA_ "GenSigStartValue" SG_ 155 EWS_BEV_1_2 255;
BA_ "GenSigSendType" SG_ 155 EWS_BEV_1_1 1;
BA_ "CycleTime" SG_ 155 EWS_BEV_1_1 10;
BA_ "GenSigTimeoutTime" SG_ 155 EWS_BEV_1_1 50;
BA_ "InvalidValue" SG_ 155 EWS_BEV_1_1 255;
BA_ "GenSigStartValue" SG_ 155 EWS_BEV_1_1 255;
BA_ "GenSigSendType" SG_ 155 EWS_BEV_1_0 1;
BA_ "CycleTime" SG_ 155 EWS_BEV_1_0 10;
BA_ "GenSigTimeoutTime" SG_ 155 EWS_BEV_1_0 50;
BA_ "InvalidValue" SG_ 155 EWS_BEV_1_0 255;
BA_ "GenSigStartValue" SG_ 155 EWS_BEV_1_0 255;
BA_ "GenSigSendType" SG_ 155 EWS_BEV_1_5 1;
BA_ "CycleTime" SG_ 155 EWS_BEV_1_5 10;
BA_ "GenSigTimeoutTime" SG_ 155 EWS_BEV_1_5 50;
BA_ "InvalidValue" SG_ 155 EWS_BEV_1_5 255;
BA_ "GenSigStartValue" SG_ 155 EWS_BEV_1_5 255;
BA_ "GenSigSendType" SG_ 155 EWS_BEV_1_4 1;
BA_ "CycleTime" SG_ 155 EWS_BEV_1_4 10;
BA_ "GenSigTimeoutTime" SG_ 155 EWS_BEV_1_4 50;
BA_ "InvalidValue" SG_ 155 EWS_BEV_1_4 255;
BA_ "GenSigStartValue" SG_ 155 EWS_BEV_1_4 255;
BA_ "GenSigSendType" SG_ 156 EWS_BEV_1_ANSW_0 1;
BA_ "CycleTime" SG_ 156 EWS_BEV_1_ANSW_0 10;
BA_ "GenSigTimeoutTime" SG_ 156 EWS_BEV_1_ANSW_0 50;
BA_ "InvalidValue" SG_ 156 EWS_BEV_1_ANSW_0 255;
BA_ "GenSigStartValue" SG_ 156 EWS_BEV_1_ANSW_0 255;
BA_ "GenSigSendType" SG_ 156 EWS_BEV_1_ANSW_1 1;
BA_ "CycleTime" SG_ 156 EWS_BEV_1_ANSW_1 10;
BA_ "GenSigTimeoutTime" SG_ 156 EWS_BEV_1_ANSW_1 50;
BA_ "InvalidValue" SG_ 156 EWS_BEV_1_ANSW_1 255;
BA_ "GenSigStartValue" SG_ 156 EWS_BEV_1_ANSW_1 255;
BA_ "GenSigSendType" SG_ 156 EWS_BEV_1_ANSW_3 1;
BA_ "CycleTime" SG_ 156 EWS_BEV_1_ANSW_3 10;
BA_ "GenSigTimeoutTime" SG_ 156 EWS_BEV_1_ANSW_3 50;
BA_ "InvalidValue" SG_ 156 EWS_BEV_1_ANSW_3 255;
BA_ "GenSigStartValue" SG_ 156 EWS_BEV_1_ANSW_3 255;
BA_ "GenSigSendType" SG_ 156 EWS_BEV_1_ANSW_4 1;
BA_ "CycleTime" SG_ 156 EWS_BEV_1_ANSW_4 10;
BA_ "GenSigTimeoutTime" SG_ 156 EWS_BEV_1_ANSW_4 50;
BA_ "InvalidValue" SG_ 156 EWS_BEV_1_ANSW_4 255;
BA_ "GenSigStartValue" SG_ 156 EWS_BEV_1_ANSW_4 255;
BA_ "GenSigSendType" SG_ 156 EWS_BEV_1_ANSW_5 1;
BA_ "CycleTime" SG_ 156 EWS_BEV_1_ANSW_5 10;
BA_ "GenSigTimeoutTime" SG_ 156 EWS_BEV_1_ANSW_5 50;
BA_ "InvalidValue" SG_ 156 EWS_BEV_1_ANSW_5 255;
BA_ "GenSigStartValue" SG_ 156 EWS_BEV_1_ANSW_5 255;
BA_ "GenSigSendType" SG_ 156 EWS_BEV_1_ANSW_6 1;
BA_ "CycleTime" SG_ 156 EWS_BEV_1_ANSW_6 10;
BA_ "GenSigTimeoutTime" SG_ 156 EWS_BEV_1_ANSW_6 50;
BA_ "InvalidValue" SG_ 156 EWS_BEV_1_ANSW_6 255;
BA_ "GenSigStartValue" SG_ 156 EWS_BEV_1_ANSW_6 255;
BA_ "GenSigSendType" SG_ 156 EWS_BEV_1_ANSW_7 1;
BA_ "CycleTime" SG_ 156 EWS_BEV_1_ANSW_7 10;
BA_ "GenSigTimeoutTime" SG_ 156 EWS_BEV_1_ANSW_7 50;
BA_ "InvalidValue" SG_ 156 EWS_BEV_1_ANSW_7 255;
BA_ "GenSigStartValue" SG_ 156 EWS_BEV_1_ANSW_7 255;
BA_ "GenSigSendType" SG_ 156 EWS_BEV_1_ANSW_2 1;
BA_ "CycleTime" SG_ 156 EWS_BEV_1_ANSW_2 10;
BA_ "GenSigTimeoutTime" SG_ 156 EWS_BEV_1_ANSW_2 50;
BA_ "InvalidValue" SG_ 156 EWS_BEV_1_ANSW_2 255;
BA_ "GenSigStartValue" SG_ 156 EWS_BEV_1_ANSW_2 255;
BA_ "CycleTime" SG_ 157 BMS_DebugSignal19 10;
BA_ "GenSigTimeoutTime" SG_ 157 BMS_DebugSignal19 50;
BA_ "CycleTime" SG_ 157 BMS_DebugSignal20 10;
BA_ "GenSigTimeoutTime" SG_ 157 BMS_DebugSignal20 50;
BA_ "CycleTime" SG_ 157 BMS_DebugSignal21 10;
BA_ "GenSigTimeoutTime" SG_ 157 BMS_DebugSignal21 50;
BA_ "CycleTime" SG_ 157 BMS_DebugSignal22 10;
BA_ "GenSigTimeoutTime" SG_ 157 BMS_DebugSignal22 50;
BA_ "CycleTime" SG_ 157 BMS_DebugSignal23 10;
BA_ "GenSigTimeoutTime" SG_ 157 BMS_DebugSignal23 50;
BA_ "CycleTime" SG_ 157 BMS_DebugSignal24 10;
BA_ "GenSigTimeoutTime" SG_ 157 BMS_DebugSignal24 50;
BA_ "CycleTime" SG_ 157 BMS_DebugSignal27 10;
BA_ "GenSigTimeoutTime" SG_ 157 BMS_DebugSignal27 50;
BA_ "CycleTime" SG_ 157 BMS_DebugSignal26 10;
BA_ "GenSigTimeoutTime" SG_ 157 BMS_DebugSignal26 50;
BA_ "CycleTime" SG_ 157 BMS_DebugSignal28 10;
BA_ "GenSigTimeoutTime" SG_ 157 BMS_DebugSignal28 50;
BA_ "CycleTime" SG_ 157 BMS_DebugSignal16 10;
BA_ "GenSigTimeoutTime" SG_ 157 BMS_DebugSignal16 50;
BA_ "CycleTime" SG_ 157 BMS_DebugSignal15 10;
BA_ "GenSigTimeoutTime" SG_ 157 BMS_DebugSignal15 50;
BA_ "CycleTime" SG_ 157 BMS_DebugSignal29 10;
BA_ "GenSigTimeoutTime" SG_ 157 BMS_DebugSignal29 50;
BA_ "CycleTime" SG_ 157 BMS_DebugSignal25 10;
BA_ "GenSigTimeoutTime" SG_ 157 BMS_DebugSignal25 50;
BA_ "CycleTime" SG_ 157 BMS_DebugSignal18 10;
BA_ "GenSigTimeoutTime" SG_ 157 BMS_DebugSignal18 50;
BA_ "CycleTime" SG_ 157 BMS_DebugSignal17 10;
BA_ "GenSigTimeoutTime" SG_ 157 BMS_DebugSignal17 50;
BA_ "GenSigSendType" SG_ 160 EWS_BEV_2_5 1;
BA_ "CycleTime" SG_ 160 EWS_BEV_2_5 10;
BA_ "GenSigTimeoutTime" SG_ 160 EWS_BEV_2_5 50;
BA_ "InvalidValue" SG_ 160 EWS_BEV_2_5 255;
BA_ "GenSigStartValue" SG_ 160 EWS_BEV_2_5 255;
BA_ "GenSigSendType" SG_ 160 EWS_BEV_2_7 1;
BA_ "CycleTime" SG_ 160 EWS_BEV_2_7 10;
BA_ "GenSigTimeoutTime" SG_ 160 EWS_BEV_2_7 50;
BA_ "InvalidValue" SG_ 160 EWS_BEV_2_7 255;
BA_ "GenSigStartValue" SG_ 160 EWS_BEV_2_7 255;
BA_ "GenSigSendType" SG_ 160 EWS_BEV_2_6 1;
BA_ "CycleTime" SG_ 160 EWS_BEV_2_6 10;
BA_ "GenSigTimeoutTime" SG_ 160 EWS_BEV_2_6 50;
BA_ "InvalidValue" SG_ 160 EWS_BEV_2_6 255;
BA_ "GenSigStartValue" SG_ 160 EWS_BEV_2_6 255;
BA_ "GenSigSendType" SG_ 160 EWS_BEV_2_4 1;
BA_ "CycleTime" SG_ 160 EWS_BEV_2_4 10;
BA_ "GenSigTimeoutTime" SG_ 160 EWS_BEV_2_4 50;
BA_ "InvalidValue" SG_ 160 EWS_BEV_2_4 255;
BA_ "GenSigStartValue" SG_ 160 EWS_BEV_2_4 255;
BA_ "GenSigSendType" SG_ 160 EWS_BEV_2_3 1;
BA_ "CycleTime" SG_ 160 EWS_BEV_2_3 10;
BA_ "GenSigTimeoutTime" SG_ 160 EWS_BEV_2_3 50;
BA_ "InvalidValue" SG_ 160 EWS_BEV_2_3 255;
BA_ "GenSigStartValue" SG_ 160 EWS_BEV_2_3 255;
BA_ "GenSigSendType" SG_ 160 EWS_BEV_2_2 1;
BA_ "CycleTime" SG_ 160 EWS_BEV_2_2 10;
BA_ "GenSigTimeoutTime" SG_ 160 EWS_BEV_2_2 50;
BA_ "InvalidValue" SG_ 160 EWS_BEV_2_2 255;
BA_ "GenSigStartValue" SG_ 160 EWS_BEV_2_2 255;
BA_ "GenSigSendType" SG_ 160 EWS_BEV_2_1 1;
BA_ "CycleTime" SG_ 160 EWS_BEV_2_1 10;
BA_ "GenSigTimeoutTime" SG_ 160 EWS_BEV_2_1 50;
BA_ "InvalidValue" SG_ 160 EWS_BEV_2_1 255;
BA_ "GenSigStartValue" SG_ 160 EWS_BEV_2_1 255;
BA_ "GenSigSendType" SG_ 160 EWS_BEV_2_0 1;
BA_ "CycleTime" SG_ 160 EWS_BEV_2_0 10;
BA_ "GenSigTimeoutTime" SG_ 160 EWS_BEV_2_0 50;
BA_ "InvalidValue" SG_ 160 EWS_BEV_2_0 255;
BA_ "GenSigStartValue" SG_ 160 EWS_BEV_2_0 255;
BA_ "GenSigSendType" SG_ 161 EWS_BEV_2_ANSW_2 1;
BA_ "CycleTime" SG_ 161 EWS_BEV_2_ANSW_2 10;
BA_ "GenSigTimeoutTime" SG_ 161 EWS_BEV_2_ANSW_2 50;
BA_ "InvalidValue" SG_ 161 EWS_BEV_2_ANSW_2 255;
BA_ "GenSigStartValue" SG_ 161 EWS_BEV_2_ANSW_2 255;
BA_ "GenSigSendType" SG_ 161 EWS_BEV_2_ANSW_1 1;
BA_ "CycleTime" SG_ 161 EWS_BEV_2_ANSW_1 10;
BA_ "GenSigTimeoutTime" SG_ 161 EWS_BEV_2_ANSW_1 50;
BA_ "InvalidValue" SG_ 161 EWS_BEV_2_ANSW_1 255;
BA_ "GenSigStartValue" SG_ 161 EWS_BEV_2_ANSW_1 255;
BA_ "GenSigSendType" SG_ 161 EWS_BEV_2_ANSW_0 1;
BA_ "CycleTime" SG_ 161 EWS_BEV_2_ANSW_0 10;
BA_ "GenSigTimeoutTime" SG_ 161 EWS_BEV_2_ANSW_0 50;
BA_ "InvalidValue" SG_ 161 EWS_BEV_2_ANSW_0 255;
BA_ "GenSigStartValue" SG_ 161 EWS_BEV_2_ANSW_0 255;
BA_ "GenSigSendType" SG_ 161 EWS_BEV_2_ANSW_5 1;
BA_ "CycleTime" SG_ 161 EWS_BEV_2_ANSW_5 10;
BA_ "GenSigTimeoutTime" SG_ 161 EWS_BEV_2_ANSW_5 50;
BA_ "InvalidValue" SG_ 161 EWS_BEV_2_ANSW_5 255;
BA_ "GenSigStartValue" SG_ 161 EWS_BEV_2_ANSW_5 255;
BA_ "GenSigSendType" SG_ 161 EWS_BEV_2_ANSW_6 1;
BA_ "CycleTime" SG_ 161 EWS_BEV_2_ANSW_6 10;
BA_ "GenSigTimeoutTime" SG_ 161 EWS_BEV_2_ANSW_6 50;
BA_ "InvalidValue" SG_ 161 EWS_BEV_2_ANSW_6 255;
BA_ "GenSigStartValue" SG_ 161 EWS_BEV_2_ANSW_6 255;
BA_ "GenSigSendType" SG_ 161 EWS_BEV_2_ANSW_7 1;
BA_ "CycleTime" SG_ 161 EWS_BEV_2_ANSW_7 10;
BA_ "GenSigTimeoutTime" SG_ 161 EWS_BEV_2_ANSW_7 50;
BA_ "InvalidValue" SG_ 161 EWS_BEV_2_ANSW_7 255;
BA_ "GenSigStartValue" SG_ 161 EWS_BEV_2_ANSW_7 255;
BA_ "GenSigSendType" SG_ 161 EWS_BEV_2_ANSW_3 1;
BA_ "CycleTime" SG_ 161 EWS_BEV_2_ANSW_3 10;
BA_ "GenSigTimeoutTime" SG_ 161 EWS_BEV_2_ANSW_3 50;
BA_ "InvalidValue" SG_ 161 EWS_BEV_2_ANSW_3 255;
BA_ "GenSigStartValue" SG_ 161 EWS_BEV_2_ANSW_3 255;
BA_ "GenSigSendType" SG_ 161 EWS_BEV_2_ANSW_4 1;
BA_ "CycleTime" SG_ 161 EWS_BEV_2_ANSW_4 10;
BA_ "GenSigTimeoutTime" SG_ 161 EWS_BEV_2_ANSW_4 50;
BA_ "InvalidValue" SG_ 161 EWS_BEV_2_ANSW_4 255;
BA_ "GenSigStartValue" SG_ 161 EWS_BEV_2_ANSW_4 255;
BA_ "CycleTime" SG_ 162 BMS_PackLowVolErr 10;
BA_ "GenSigTimeoutTime" SG_ 162 BMS_PackLowVolErr 50;
BA_ "CycleTime" SG_ 162 BMS_PackOverCurrErr 10;
BA_ "GenSigTimeoutTime" SG_ 162 BMS_PackOverCurrErr 50;
BA_ "CycleTime" SG_ 162 CRC_BMS_Error 10;
BA_ "GenSigTimeoutTime" SG_ 162 CRC_BMS_Error 50;
BA_ "CycleTime" SG_ 162 ALV_BMS_Error 10;
BA_ "GenSigTimeoutTime" SG_ 162 ALV_BMS_Error 50;
BA_ "InvalidValue" SG_ 162 ALV_BMS_Error 15;
BA_ "CycleTime" SG_ 162 BMS_CellLowVolErr 10;
BA_ "GenSigTimeoutTime" SG_ 162 BMS_CellLowVolErr 50;
BA_ "CycleTime" SG_ 162 BMS_HVILErr 10;
BA_ "GenSigTimeoutTime" SG_ 162 BMS_HVILErr 50;
BA_ "CycleTime" SG_ 162 BMS_FuseStatusErr 10;
BA_ "GenSigTimeoutTime" SG_ 162 BMS_FuseStatusErr 50;
BA_ "CycleTime" SG_ 162 BMS_ProbeHighTempErr 10;
BA_ "GenSigTimeoutTime" SG_ 162 BMS_ProbeHighTempErr 50;
BA_ "CycleTime" SG_ 162 BMS_CellHighVolErr 10;
BA_ "GenSigTimeoutTime" SG_ 162 BMS_CellHighVolErr 50;
BA_ "CycleTime" SG_ 162 BMS_ProbeLowTempErr 10;
BA_ "GenSigTimeoutTime" SG_ 162 BMS_ProbeLowTempErr 50;
BA_ "CycleTime" SG_ 162 BMS_PackHighVolErr 10;
BA_ "GenSigTimeoutTime" SG_ 162 BMS_PackHighVolErr 50;
BA_ "CycleTime" SG_ 162 BMS_ProbeTempDiffErr 10;
BA_ "GenSigTimeoutTime" SG_ 162 BMS_ProbeTempDiffErr 50;
BA_ "CycleTime" SG_ 162 BMS_CellVoltDiffErr 10;
BA_ "GenSigTimeoutTime" SG_ 162 BMS_CellVoltDiffErr 50;
BA_ "CycleTime" SG_ 162 BMS_PackInsuErr 10;
BA_ "GenSigTimeoutTime" SG_ 162 BMS_PackInsuErr 50;
BA_ "GenSigStartValue" SG_ 166 CHL_WMOM_DRV_9 15;
BA_ "InvalidValue" SG_ 166 CHL_WMOM_DRV_9 15;
BA_ "GenSigTimeoutTime" SG_ 166 CHL_WMOM_DRV_9 50;
BA_ "CycleTime" SG_ 166 CHL_WMOM_DRV_9 10;
BA_ "SigFixedValue" SG_ 166 CHL_WMOM_DRV_9 "10";
BA_ "InvalidValue" SG_ 166 ALIV_WMOM_DRV_9 15;
BA_ "GenSigTimeoutTime" SG_ 166 ALIV_WMOM_DRV_9 50;
BA_ "CycleTime" SG_ 166 ALIV_WMOM_DRV_9 10;
BA_ "GenSigStartValue" SG_ 166 CRC_WMOM_DRV_9 255;
BA_ "InvalidValue" SG_ 166 CRC_WMOM_DRV_9 255;
BA_ "GenSigTimeoutTime" SG_ 166 CRC_WMOM_DRV_9 50;
BA_ "CycleTime" SG_ 166 CRC_WMOM_DRV_9 10;
BA_ "CycleTime" SG_ 166 TAR_WMOM_PT_SUM_COOTD 10;
BA_ "GenSigTimeoutTime" SG_ 166 TAR_WMOM_PT_SUM_COOTD 50;
BA_ "InvalidValue" SG_ 166 TAR_WMOM_PT_SUM_COOTD 65535;
BA_ "GenSigStartValue" SG_ 166 TAR_WMOM_PT_SUM_COOTD 65535;
BA_ "CycleTime" SG_ 167 EWS_GLB_7 1000;
BA_ "GenSigTimeoutTime" SG_ 167 EWS_GLB_7 5000;
BA_ "InvalidValue" SG_ 167 EWS_GLB_7 255;
BA_ "GenSigStartValue" SG_ 167 EWS_GLB_7 255;
BA_ "CycleTime" SG_ 167 EWS_GLB_1 1000;
BA_ "GenSigTimeoutTime" SG_ 167 EWS_GLB_1 5000;
BA_ "InvalidValue" SG_ 167 EWS_GLB_1 255;
BA_ "GenSigStartValue" SG_ 167 EWS_GLB_1 255;
BA_ "CycleTime" SG_ 167 EWS_GLB_2 1000;
BA_ "GenSigTimeoutTime" SG_ 167 EWS_GLB_2 5000;
BA_ "InvalidValue" SG_ 167 EWS_GLB_2 255;
BA_ "GenSigStartValue" SG_ 167 EWS_GLB_2 255;
BA_ "CycleTime" SG_ 167 EWS_GLB_3 1000;
BA_ "GenSigTimeoutTime" SG_ 167 EWS_GLB_3 5000;
BA_ "InvalidValue" SG_ 167 EWS_GLB_3 255;
BA_ "GenSigStartValue" SG_ 167 EWS_GLB_3 255;
BA_ "CycleTime" SG_ 167 EWS_GLB_6 1000;
BA_ "GenSigTimeoutTime" SG_ 167 EWS_GLB_6 5000;
BA_ "InvalidValue" SG_ 167 EWS_GLB_6 255;
BA_ "GenSigStartValue" SG_ 167 EWS_GLB_6 255;
BA_ "CycleTime" SG_ 167 EWS_GLB_0 1000;
BA_ "GenSigTimeoutTime" SG_ 167 EWS_GLB_0 5000;
BA_ "InvalidValue" SG_ 167 EWS_GLB_0 255;
BA_ "GenSigStartValue" SG_ 167 EWS_GLB_0 255;
BA_ "CycleTime" SG_ 167 EWS_GLB_5 1000;
BA_ "GenSigTimeoutTime" SG_ 167 EWS_GLB_5 5000;
BA_ "InvalidValue" SG_ 167 EWS_GLB_5 255;
BA_ "GenSigStartValue" SG_ 167 EWS_GLB_5 255;
BA_ "CycleTime" SG_ 167 EWS_GLB_4 1000;
BA_ "GenSigTimeoutTime" SG_ 167 EWS_GLB_4 5000;
BA_ "InvalidValue" SG_ 167 EWS_GLB_4 255;
BA_ "GenSigStartValue" SG_ 167 EWS_GLB_4 255;
BA_ "CycleTime" SG_ 168 CRC_BMS_HVMeas 10;
BA_ "GenSigTimeoutTime" SG_ 168 CRC_BMS_HVMeas 50;
BA_ "CycleTime" SG_ 168 ALV_BMS_HVMeas 10;
BA_ "GenSigTimeoutTime" SG_ 168 ALV_BMS_HVMeas 50;
BA_ "InvalidValue" SG_ 168 ALV_BMS_HVMeas 15;
BA_ "CycleTime" SG_ 168 BMS_HVPackVol 10;
BA_ "GenSigTimeoutTime" SG_ 168 BMS_HVPackVol 50;
BA_ "InvalidValue" SG_ 168 BMS_HVPackVol 8191;
BA_ "GenSigStartValue" SG_ 168 BMS_HVPackVol 3450;
BA_ "CycleTime" SG_ 168 BMS_HVLinkVol 10;
BA_ "GenSigTimeoutTime" SG_ 168 BMS_HVLinkVol 50;
BA_ "InvalidValue" SG_ 168 BMS_HVLinkVol 8191;
BA_ "GenSigStartValue" SG_ 168 BMS_HVLinkVol 3450;
BA_ "CycleTime" SG_ 168 BMS_HVBusVol 10;
BA_ "GenSigTimeoutTime" SG_ 168 BMS_HVBusVol 50;
BA_ "InvalidValue" SG_ 168 BMS_HVBusVol 8191;
BA_ "GenSigStartValue" SG_ 168 BMS_HVBusVol 3450;
BA_ "CycleTime" SG_ 168 BMS_HVFuseVol 10;
BA_ "GenSigTimeoutTime" SG_ 168 BMS_HVFuseVol 50;
BA_ "InvalidValue" SG_ 168 BMS_HVFuseVol 8191;
BA_ "GenSigStartValue" SG_ 168 BMS_HVFuseVol 3450;
BA_ "InvalidValue" SG_ 168 BMS_DCPlugVol 8191;
BA_ "GenSigStartValue" SG_ 168 BMS_DCPlugVol 3450;
BA_ "CycleTime" SG_ 168 BMS_DCPlugVol 10;
BA_ "CycleTime" SG_ 170 QualifierRpmEmETractSys2ActVal 10;
BA_ "GenSigTimeoutTime" SG_ 170 QualifierRpmEmETractSys2ActVal 50;
BA_ "InvalidValue" SG_ 170 QualifierRpmEmETractSys2ActVal 15;
BA_ "GenSigStartValue" SG_ 170 QualifierRpmEmETractSys2ActVal 15;
BA_ "CycleTime" SG_ 170 DirOfRotETractSys2ActVal 10;
BA_ "GenSigTimeoutTime" SG_ 170 DirOfRotETractSys2ActVal 50;
BA_ "InvalidValue" SG_ 170 DirOfRotETractSys2ActVal 3;
BA_ "GenSigStartValue" SG_ 170 DirOfRotETractSys2ActVal 3;
BA_ "CycleTime" SG_ 170 TqEmETractSys2MotorSumLimTarget 10;
BA_ "GenSigTimeoutTime" SG_ 170 TqEmETractSys2MotorSumLimTarget 50;
BA_ "InvalidValue" SG_ 170 TqEmETractSys2MotorSumLimTarget 4095;
BA_ "GenSigStartValue" SG_ 170 TqEmETractSys2MotorSumLimTarget 4095;
BA_ "CycleTime" SG_ 170 StatusLockPositionPbWETractSys2 10;
BA_ "GenSigTimeoutTime" SG_ 170 StatusLockPositionPbWETractSys2 50;
BA_ "InvalidValue" SG_ 170 StatusLockPositionPbWETractSys2 15;
BA_ "CycleTime" SG_ 170 TorqueEmETractSys2ActualValue 10;
BA_ "GenSigTimeoutTime" SG_ 170 TorqueEmETractSys2ActualValue 50;
BA_ "InvalidValue" SG_ 170 TorqueEmETractSys2ActualValue 4095;
BA_ "GenSigStartValue" SG_ 170 TorqueEmETractSys2ActualValue 4095;
BA_ "CycleTime" SG_ 170 TorqueEmETractSys2MotorDynamic 10;
BA_ "GenSigTimeoutTime" SG_ 170 TorqueEmETractSys2MotorDynamic 50;
BA_ "InvalidValue" SG_ 170 TorqueEmETractSys2MotorDynamic 4095;
BA_ "GenSigStartValue" SG_ 170 TorqueEmETractSys2MotorDynamic 4095;
BA_ "CycleTime" SG_ 170 TqEmETractSys2GeneratorDynamic 10;
BA_ "GenSigTimeoutTime" SG_ 170 TqEmETractSys2GeneratorDynamic 50;
BA_ "InvalidValue" SG_ 170 TqEmETractSys2GeneratorDynamic 4095;
BA_ "GenSigStartValue" SG_ 170 TqEmETractSys2GeneratorDynamic 4095;
BA_ "CycleTime" SG_ 170 TqEmETractSys2GeneratorStatic 10;
BA_ "GenSigTimeoutTime" SG_ 170 TqEmETractSys2GeneratorStatic 50;
BA_ "InvalidValue" SG_ 170 TqEmETractSys2GeneratorStatic 4095;
BA_ "GenSigStartValue" SG_ 170 TqEmETractSys2GeneratorStatic 4095;
BA_ "CycleTime" SG_ 170 RpmEmETractSys2ActualValue 10;
BA_ "GenSigTimeoutTime" SG_ 170 RpmEmETractSys2ActualValue 50;
BA_ "InvalidValue" SG_ 170 RpmEmETractSys2ActualValue 65535;
BA_ "GenSigStartValue" SG_ 170 RpmEmETractSys2ActualValue 65535;
BA_ "CycleTime" SG_ 170 TqEmETractSys2VibrationDampSusp 10;
BA_ "GenSigTimeoutTime" SG_ 170 TqEmETractSys2VibrationDampSusp 50;
BA_ "InvalidValue" SG_ 170 TqEmETractSys2VibrationDampSusp 4095;
BA_ "GenSigStartValue" SG_ 170 TqEmETractSys2VibrationDampSusp 4095;
BA_ "CycleTime" SG_ 170 RpmEmETractSys2MinimumLimit 10;
BA_ "GenSigTimeoutTime" SG_ 170 RpmEmETractSys2MinimumLimit 50;
BA_ "InvalidValue" SG_ 170 RpmEmETractSys2MinimumLimit 65535;
BA_ "GenSigStartValue" SG_ 170 RpmEmETractSys2MinimumLimit 65535;
BA_ "CycleTime" SG_ 170 RpmEmETractSys2MaximumLimit 10;
BA_ "GenSigTimeoutTime" SG_ 170 RpmEmETractSys2MaximumLimit 50;
BA_ "InvalidValue" SG_ 170 RpmEmETractSys2MaximumLimit 65535;
BA_ "GenSigStartValue" SG_ 170 RpmEmETractSys2MaximumLimit 65535;
BA_ "CycleTime" SG_ 170 VolDrctCurrETractSys2ActVal 10;
BA_ "GenSigTimeoutTime" SG_ 170 VolDrctCurrETractSys2ActVal 50;
BA_ "InvalidValue" SG_ 170 VolDrctCurrETractSys2ActVal 4095;
BA_ "GenSigStartValue" SG_ 170 VolDrctCurrETractSys2ActVal 4095;
BA_ "CycleTime" SG_ 170 CurrDrctCurrETractSys2ActVal 10;
BA_ "GenSigTimeoutTime" SG_ 170 CurrDrctCurrETractSys2ActVal 50;
BA_ "InvalidValue" SG_ 170 CurrDrctCurrETractSys2ActVal 65535;
BA_ "GenSigStartValue" SG_ 170 CurrDrctCurrETractSys2ActVal 65535;
BA_ "CycleTime" SG_ 170 ALIV_TracEMacElectc2Time10msNo1 10;
BA_ "GenSigTimeoutTime" SG_ 170 ALIV_TracEMacElectc2Time10msNo1 50;
BA_ "InvalidValue" SG_ 170 ALIV_TracEMacElectc2Time10msNo1 255;
BA_ "CycleTime" SG_ 170 CRC_TracEMacElectc2Time10msNo1 10;
BA_ "GenSigTimeoutTime" SG_ 170 CRC_TracEMacElectc2Time10msNo1 50;
BA_ "InvalidValue" SG_ 170 CRC_TracEMacElectc2Time10msNo1 255;
BA_ "GenSigStartValue" SG_ 170 CRC_TracEMacElectc2Time10msNo1 255;
BA_ "CycleTime" SG_ 170 TorqueEmETractSys2MotorStatic 10;
BA_ "GenSigTimeoutTime" SG_ 170 TorqueEmETractSys2MotorStatic 50;
BA_ "InvalidValue" SG_ 170 TorqueEmETractSys2MotorStatic 4095;
BA_ "GenSigStartValue" SG_ 170 TorqueEmETractSys2MotorStatic 4095;
BA_ "CycleTime" SG_ 170 QualifierTqEmETractSys2ActVal 10;
BA_ "GenSigTimeoutTime" SG_ 170 QualifierTqEmETractSys2ActVal 50;
BA_ "InvalidValue" SG_ 170 QualifierTqEmETractSys2ActVal 15;
BA_ "GenSigStartValue" SG_ 170 QualifierTqEmETractSys2ActVal 15;
BA_ "CycleTime" SG_ 170 OVCUrrenceStatorPWMETractSys2 10;
BA_ "GenSigTimeoutTime" SG_ 170 OVCUrrenceStatorPWMETractSys2 50;
BA_ "InvalidValue" SG_ 170 OVCUrrenceStatorPWMETractSys2 3;
BA_ "GenSigStartValue" SG_ 170 OVCUrrenceStatorPWMETractSys2 3;
BA_ "CycleTime" SG_ 170 StETractSys2Asd 10;
BA_ "GenSigTimeoutTime" SG_ 170 StETractSys2Asd 50;
BA_ "InvalidValue" SG_ 170 StETractSys2Asd 65535;
BA_ "GenSigStartValue" SG_ 170 StETractSys2Asd 65535;
BA_ "CycleTime" SG_ 170 Qu_CurrDrctCurrETractSys2ActVal 10;
BA_ "GenSigTimeoutTime" SG_ 170 Qu_CurrDrctCurrETractSys2ActVal 50;
BA_ "InvalidValue" SG_ 170 Qu_CurrDrctCurrETractSys2ActVal 15;
BA_ "GenSigStartValue" SG_ 170 Qu_CurrDrctCurrETractSys2ActVal 15;
BA_ "CycleTime" SG_ 170 StatusArbRpmETractSys2Limit 10;
BA_ "GenSigTimeoutTime" SG_ 170 StatusArbRpmETractSys2Limit 50;
BA_ "InvalidValue" SG_ 170 StatusArbRpmETractSys2Limit 15;
BA_ "GenSigStartValue" SG_ 170 StatusArbRpmETractSys2Limit 15;
BA_ "SigFixedValue" SG_ 170 StatusArbRpmETractSys2Limit "0";
BA_ "CycleTime" SG_ 170 SumWhlTqIntvETractSys2 10;
BA_ "GenSigTimeoutTime" SG_ 170 SumWhlTqIntvETractSys2 50;
BA_ "InvalidValue" SG_ 170 SumWhlTqIntvETractSys2 4095;
BA_ "GenSigStartValue" SG_ 170 SumWhlTqIntvETractSys2 4095;
BA_ "SigFixedValue" SG_ 170 StatusPbWETractSys2 "0";
BA_ "CycleTime" SG_ 170 StatusPbWETractSys2 10;
BA_ "GenSigTimeoutTime" SG_ 170 StatusPbWETractSys2 50;
BA_ "InvalidValue" SG_ 170 StatusPbWETractSys2 255;
BA_ "GenSigStartValue" SG_ 170 StatusPbWETractSys2 255;
BA_ "CycleTime" SG_ 170 PowerETractSys2LossActualValue 10;
BA_ "GenSigTimeoutTime" SG_ 170 PowerETractSys2LossActualValue 50;
BA_ "InvalidValue" SG_ 170 PowerETractSys2LossActualValue 4095;
BA_ "GenSigStartValue" SG_ 170 PowerETractSys2LossActualValue 4095;
BA_ "CycleTime" SG_ 170 TarTqETractSys2NControlStatic 10;
BA_ "GenSigTimeoutTime" SG_ 170 TarTqETractSys2NControlStatic 50;
BA_ "InvalidValue" SG_ 170 TarTqETractSys2NControlStatic 1023;
BA_ "GenSigStartValue" SG_ 170 TarTqETractSys2NControlStatic 1023;
BA_ "CycleTime" SG_ 170 PwrLossPrednETractSys2Mot 10;
BA_ "GenSigTimeoutTime" SG_ 170 PwrLossPrednETractSys2Mot 50;
BA_ "InvalidValue" SG_ 170 PwrLossPrednETractSys2Mot 4095;
BA_ "GenSigStartValue" SG_ 170 PwrLossPrednETractSys2Mot 4095;
BA_ "CycleTime" SG_ 170 PwrLossPrednETractSys2Genr 10;
BA_ "GenSigTimeoutTime" SG_ 170 PwrLossPrednETractSys2Genr 50;
BA_ "InvalidValue" SG_ 170 PwrLossPrednETractSys2Genr 4095;
BA_ "GenSigStartValue" SG_ 170 PwrLossPrednETractSys2Genr 4095;
BA_ "InvalidValue" SG_ 172 BMS_MaxDischgCurrentLimPeak 65535;
BA_ "GenSigTimeoutTime" SG_ 172 BMS_MaxDischgCurrentLimPeak 50;
BA_ "CycleTime" SG_ 172 BMS_MaxDischgCurrentLimPeak 10;
BA_ "InvalidValue" SG_ 172 BMS_MaxDischgPwrLimPeak 8191;
BA_ "GenSigTimeoutTime" SG_ 172 BMS_MaxDischgPwrLimPeak 50;
BA_ "CycleTime" SG_ 172 BMS_MaxDischgPwrLimPeak 10;
BA_ "CycleTime" SG_ 172 ALV_BMS_PowerCont 10;
BA_ "GenSigTimeoutTime" SG_ 172 ALV_BMS_PowerCont 50;
BA_ "InvalidValue" SG_ 172 ALV_BMS_PowerCont 15;
BA_ "CycleTime" SG_ 172 BMS_MaxDischgCurrentLim 10;
BA_ "GenSigTimeoutTime" SG_ 172 BMS_MaxDischgCurrentLim 50;
BA_ "InvalidValue" SG_ 172 BMS_MaxDischgCurrentLim 65535;
BA_ "CycleTime" SG_ 172 BMS_MaxDischgPwr30s 10;
BA_ "GenSigTimeoutTime" SG_ 172 BMS_MaxDischgPwr30s 50;
BA_ "InvalidValue" SG_ 172 BMS_MaxDischgPwr30s 8191;
BA_ "CycleTime" SG_ 172 BMS_MaxDischgPwr10s 10;
BA_ "GenSigTimeoutTime" SG_ 172 BMS_MaxDischgPwr10s 50;
BA_ "InvalidValue" SG_ 172 BMS_MaxDischgPwr10s 8191;
BA_ "CycleTime" SG_ 172 BMS_MaxDischgPwr2s 10;
BA_ "GenSigTimeoutTime" SG_ 172 BMS_MaxDischgPwr2s 50;
BA_ "InvalidValue" SG_ 172 BMS_MaxDischgPwr2s 8191;
BA_ "CycleTime" SG_ 172 BMS_MaxDischgPwrLim 10;
BA_ "GenSigTimeoutTime" SG_ 172 BMS_MaxDischgPwrLim 50;
BA_ "InvalidValue" SG_ 172 BMS_MaxDischgPwrLim 8191;
BA_ "CycleTime" SG_ 172 BMS_MaxDischgCurrent30s 10;
BA_ "GenSigTimeoutTime" SG_ 172 BMS_MaxDischgCurrent30s 50;
BA_ "InvalidValue" SG_ 172 BMS_MaxDischgCurrent30s 65535;
BA_ "CycleTime" SG_ 172 BMS_MaxDischgCurrent10s 10;
BA_ "GenSigTimeoutTime" SG_ 172 BMS_MaxDischgCurrent10s 50;
BA_ "InvalidValue" SG_ 172 BMS_MaxDischgCurrent10s 65535;
BA_ "CycleTime" SG_ 172 BMS_MaxDischgCurrent2s 10;
BA_ "GenSigTimeoutTime" SG_ 172 BMS_MaxDischgCurrent2s 50;
BA_ "InvalidValue" SG_ 172 BMS_MaxDischgCurrent2s 65535;
BA_ "CycleTime" SG_ 172 CRC_BMS_PowerCont 10;
BA_ "GenSigTimeoutTime" SG_ 172 CRC_BMS_PowerCont 50;
BA_ "CycleTime" SG_ 177 ALV_BMS_RelayStatus 10;
BA_ "GenSigTimeoutTime" SG_ 177 ALV_BMS_RelayStatus 50;
BA_ "InvalidValue" SG_ 177 ALV_BMS_RelayStatus 15;
BA_ "CycleTime" SG_ 177 BMS_MainPosRelayStatus 10;
BA_ "GenSigTimeoutTime" SG_ 177 BMS_MainPosRelayStatus 50;
BA_ "InvalidValue" SG_ 177 BMS_MainPosRelayStatus 7;
BA_ "CycleTime" SG_ 177 BMS_PreChgRelayStatus 10;
BA_ "GenSigTimeoutTime" SG_ 177 BMS_PreChgRelayStatus 50;
BA_ "InvalidValue" SG_ 177 BMS_PreChgRelayStatus 7;
BA_ "CycleTime" SG_ 177 BMS_TotalNegRelayStatus 10;
BA_ "GenSigTimeoutTime" SG_ 177 BMS_TotalNegRelayStatus 50;
BA_ "CycleTime" SG_ 177 BMS_MainPosRelayErr 10;
BA_ "GenSigTimeoutTime" SG_ 177 BMS_MainPosRelayErr 50;
BA_ "CycleTime" SG_ 177 BMS_TotalNegRelayErr 10;
BA_ "GenSigTimeoutTime" SG_ 177 BMS_TotalNegRelayErr 50;
BA_ "CycleTime" SG_ 177 BMS_PreChgRelayErr 10;
BA_ "GenSigTimeoutTime" SG_ 177 BMS_PreChgRelayErr 50;
BA_ "CycleTime" SG_ 177 CRC_BMS_RelayStatus 10;
BA_ "GenSigTimeoutTime" SG_ 177 CRC_BMS_RelayStatus 50;
BA_ "GenSigTimeoutTime" SG_ 177 BMS_DCFCPosRelayStatus 50;
BA_ "CycleTime" SG_ 177 BMS_DCFCPosRelayStatus 10;
BA_ "InvalidValue" SG_ 177 BMS_DCFCPosRelayStatus 7;
BA_ "GenSigTimeoutTime" SG_ 177 BMS_DCFCNegRelayStatus 50;
BA_ "CycleTime" SG_ 177 BMS_DCFCNegRelayStatus 10;
BA_ "InvalidValue" SG_ 177 BMS_DCFCNegRelayStatus 7;
BA_ "GenSigTimeoutTime" SG_ 177 BMS_DCFCPosRelayErr 50;
BA_ "CycleTime" SG_ 177 BMS_DCFCPosRelayErr 10;
BA_ "GenSigTimeoutTime" SG_ 177 BMS_DCFCNegRelayErr 50;
BA_ "CycleTime" SG_ 177 BMS_DCFCNegRelayErr 10;
BA_ "CycleTime" SG_ 182 BMS_HVOnOffSts 10;
BA_ "GenSigTimeoutTime" SG_ 182 BMS_HVOnOffSts 50;
BA_ "CycleTime" SG_ 182 BMS_BatBalanceErr 10;
BA_ "GenSigTimeoutTime" SG_ 182 BMS_BatBalanceErr 50;
BA_ "CycleTime" SG_ 182 BMS_ErrLev 10;
BA_ "GenSigTimeoutTime" SG_ 182 BMS_ErrLev 50;
BA_ "CycleTime" SG_ 182 BMS_DisconnectRequestRsn 10;
BA_ "GenSigTimeoutTime" SG_ 182 BMS_DisconnectRequestRsn 50;
BA_ "InvalidValue" SG_ 182 BMS_DisconnectRequestRsn 31;
BA_ "CycleTime" SG_ 182 BMS_EmergencyDisconnectRsn 10;
BA_ "GenSigTimeoutTime" SG_ 182 BMS_EmergencyDisconnectRsn 50;
BA_ "InvalidValue" SG_ 182 BMS_EmergencyDisconnectRsn 31;
BA_ "CycleTime" SG_ 182 BMS_LimpHomeRsn 10;
BA_ "GenSigTimeoutTime" SG_ 182 BMS_LimpHomeRsn 50;
BA_ "InvalidValue" SG_ 182 BMS_LimpHomeRsn 31;
BA_ "CycleTime" SG_ 182 BMS_HVILSts 10;
BA_ "GenSigTimeoutTime" SG_ 182 BMS_HVILSts 50;
BA_ "CycleTime" SG_ 182 BMS_HWCrashSts 10;
BA_ "GenSigTimeoutTime" SG_ 182 BMS_HWCrashSts 50;
BA_ "CycleTime" SG_ 182 BMS_SOE 10;
BA_ "GenSigTimeoutTime" SG_ 182 BMS_SOE 50;
BA_ "InvalidValue" SG_ 182 BMS_SOE 255;
BA_ "GenSigStartValue" SG_ 182 BMS_SOE 180;
BA_ "CycleTime" SG_ 182 BMS_BalanceSts 10;
BA_ "GenSigTimeoutTime" SG_ 182 BMS_BalanceSts 50;
BA_ "CycleTime" SG_ 182 BMS_SocRelativeEst 10;
BA_ "GenSigTimeoutTime" SG_ 182 BMS_SocRelativeEst 50;
BA_ "InvalidValue" SG_ 182 BMS_SocRelativeEst 1023;
BA_ "GenSigStartValue" SG_ 182 BMS_SocRelativeEst 900;
BA_ "CycleTime" SG_ 182 BMS_SocActualEst 10;
BA_ "GenSigTimeoutTime" SG_ 182 BMS_SocActualEst 50;
BA_ "InvalidValue" SG_ 182 BMS_SocActualEst 1023;
BA_ "GenSigStartValue" SG_ 182 BMS_SocActualEst 900;
BA_ "CycleTime" SG_ 182 BMS_SysSts 10;
BA_ "GenSigTimeoutTime" SG_ 182 BMS_SysSts 50;
BA_ "InvalidValue" SG_ 182 BMS_SysSts 8;
BA_ "CycleTime" SG_ 182 CRC_BMS_Sts 10;
BA_ "GenSigTimeoutTime" SG_ 182 CRC_BMS_Sts 50;
BA_ "CycleTime" SG_ 182 ALV_BMS_Sts 10;
BA_ "GenSigTimeoutTime" SG_ 182 ALV_BMS_Sts 50;
BA_ "InvalidValue" SG_ 182 ALV_BMS_Sts 15;
BA_ "CycleTime" SG_ 182 BMS_IGNSts 10;
BA_ "GenSigTimeoutTime" SG_ 182 BMS_IGNSts 50;
BA_ "CycleTime" SG_ 182 BMS_SOH 10;
BA_ "GenSigTimeoutTime" SG_ 182 BMS_SOH 50;
BA_ "InvalidValue" SG_ 182 BMS_SOH 255;
BA_ "GenSigStartValue" SG_ 182 BMS_SOH 200;
BA_ "CycleTime" SG_ 187 BMS_Reserved_signal2 10;
BA_ "GenSigTimeoutTime" SG_ 187 BMS_Reserved_signal2 50;
BA_ "CycleTime" SG_ 187 BMS_Warning_Flag_5 10;
BA_ "GenSigTimeoutTime" SG_ 187 BMS_Warning_Flag_5 50;
BA_ "CycleTime" SG_ 187 BMS_Reserved_signal5 10;
BA_ "GenSigTimeoutTime" SG_ 187 BMS_Reserved_signal5 50;
BA_ "CycleTime" SG_ 187 BMS_Reserved_signal4 10;
BA_ "GenSigTimeoutTime" SG_ 187 BMS_Reserved_signal4 50;
BA_ "CycleTime" SG_ 187 BMS_Reserved_signal3 10;
BA_ "GenSigTimeoutTime" SG_ 187 BMS_Reserved_signal3 50;
BA_ "CycleTime" SG_ 187 BMS_Reserved_signal1 10;
BA_ "GenSigTimeoutTime" SG_ 187 BMS_Reserved_signal1 50;
BA_ "CycleTime" SG_ 187 BMS_Warning_Flag_6 10;
BA_ "GenSigTimeoutTime" SG_ 187 BMS_Warning_Flag_6 50;
BA_ "CycleTime" SG_ 187 BMS_MalfunctionSts 10;
BA_ "GenSigTimeoutTime" SG_ 187 BMS_MalfunctionSts 50;
BA_ "CycleTime" SG_ 187 BMS_BatteryReplacement 10;
BA_ "GenSigTimeoutTime" SG_ 187 BMS_BatteryReplacement 50;
BA_ "CycleTime" SG_ 187 BMS_ThermalRunaway 10;
BA_ "GenSigTimeoutTime" SG_ 187 BMS_ThermalRunaway 50;
BA_ "CycleTime" SG_ 187 BMS_PackTempSts 10;
BA_ "GenSigTimeoutTime" SG_ 187 BMS_PackTempSts 50;
BA_ "CycleTime" SG_ 187 ALV_BMS_WarnMsg 10;
BA_ "GenSigTimeoutTime" SG_ 187 ALV_BMS_WarnMsg 50;
BA_ "InvalidValue" SG_ 187 ALV_BMS_WarnMsg 15;
BA_ "CycleTime" SG_ 187 BMS_Warning_Flag_7 10;
BA_ "GenSigTimeoutTime" SG_ 187 BMS_Warning_Flag_7 50;
BA_ "CycleTime" SG_ 187 BMS_LowBattery 10;
BA_ "GenSigTimeoutTime" SG_ 187 BMS_LowBattery 50;
BA_ "CycleTime" SG_ 187 BMS_Warning_Flag_8 10;
BA_ "GenSigTimeoutTime" SG_ 187 BMS_Warning_Flag_8 50;
BA_ "CycleTime" SG_ 187 BMS_Warning_Flag_9 10;
BA_ "GenSigTimeoutTime" SG_ 187 BMS_Warning_Flag_9 50;
BA_ "CycleTime" SG_ 187 CHSKM_BMS_WarnMsg 10;
BA_ "GenSigTimeoutTime" SG_ 187 CHSKM_BMS_WarnMsg 50;
BA_ "CycleTime" SG_ 213 ALIV_ST_STAB_DSC 50;
BA_ "GenSigTimeoutTime" SG_ 213 ALIV_ST_STAB_DSC 250;
BA_ "InvalidValue" SG_ 213 ALIV_ST_STAB_DSC 15;
BA_ "CycleTime" SG_ 213 QU_FN_FDR 50;
BA_ "GenSigTimeoutTime" SG_ 213 QU_FN_FDR 250;
BA_ "InvalidValue" SG_ 213 QU_FN_FDR 4095;
BA_ "GenSigStartValue" SG_ 213 QU_FN_FDR 4095;
BA_ "CycleTime" SG_ 213 QU_FN_ABS 50;
BA_ "GenSigTimeoutTime" SG_ 213 QU_FN_ABS 250;
BA_ "InvalidValue" SG_ 213 QU_FN_ABS 4095;
BA_ "GenSigStartValue" SG_ 213 QU_FN_ABS 4095;
BA_ "CycleTime" SG_ 213 QU_FN_ASC 50;
BA_ "GenSigTimeoutTime" SG_ 213 QU_FN_ASC 250;
BA_ "InvalidValue" SG_ 213 QU_FN_ASC 4095;
BA_ "GenSigStartValue" SG_ 213 QU_FN_ASC 4095;
BA_ "CycleTime" SG_ 213 ST_BRG_DV 50;
BA_ "GenSigTimeoutTime" SG_ 213 ST_BRG_DV 250;
BA_ "InvalidValue" SG_ 213 ST_BRG_DV 63;
BA_ "GenSigStartValue" SG_ 213 ST_BRG_DV 63;
BA_ "CycleTime" SG_ 213 CRC_ST_STAB_DSC 50;
BA_ "GenSigTimeoutTime" SG_ 213 CRC_ST_STAB_DSC 250;
BA_ "InvalidValue" SG_ 213 CRC_ST_STAB_DSC 255;
BA_ "GenSigStartValue" SG_ 213 CRC_ST_STAB_DSC 255;
BA_ "SigFixedValue" SG_ 214 ST_SLIP_THO "15";
BA_ "CycleTime" SG_ 214 ST_SLIP_THO 100;
BA_ "GenSigTimeoutTime" SG_ 214 ST_SLIP_THO 500;
BA_ "InvalidValue" SG_ 214 ST_SLIP_THO 15;
BA_ "GenSigStartValue" SG_ 214 ST_SLIP_THO 15;
BA_ "GenSigStartValue" SG_ 217 CHL_WMOM_PT_AVL 15;
BA_ "InvalidValue" SG_ 217 CHL_WMOM_PT_AVL 15;
BA_ "GenSigTimeoutTime" SG_ 217 CHL_WMOM_PT_AVL 50;
BA_ "CycleTime" SG_ 217 CHL_WMOM_PT_AVL 10;
BA_ "SigFixedValue" SG_ 217 CHL_WMOM_PT_AVL "9";
BA_ "InvalidValue" SG_ 217 ALIV_WMOM_PT_AVL 15;
BA_ "GenSigTimeoutTime" SG_ 217 ALIV_WMOM_PT_AVL 50;
BA_ "CycleTime" SG_ 217 ALIV_WMOM_PT_AVL 10;
BA_ "GenSigStartValue" SG_ 217 CRC_WMOM_PT_AVL 255;
BA_ "InvalidValue" SG_ 217 CRC_WMOM_PT_AVL 255;
BA_ "GenSigTimeoutTime" SG_ 217 CRC_WMOM_PT_AVL 50;
BA_ "CycleTime" SG_ 217 CRC_WMOM_PT_AVL 10;
BA_ "CycleTime" SG_ 217 AVL_WMOM_PT_SUM 10;
BA_ "GenSigTimeoutTime" SG_ 217 AVL_WMOM_PT_SUM 50;
BA_ "InvalidValue" SG_ 217 AVL_WMOM_PT_SUM 65535;
BA_ "GenSigStartValue" SG_ 217 AVL_WMOM_PT_SUM 65535;
BA_ "CycleTime" SG_ 217 QU_AVL_WMOM_PT_SUM 10;
BA_ "GenSigTimeoutTime" SG_ 217 QU_AVL_WMOM_PT_SUM 50;
BA_ "InvalidValue" SG_ 217 QU_AVL_WMOM_PT_SUM 15;
BA_ "GenSigStartValue" SG_ 217 QU_AVL_WMOM_PT_SUM 15;
BA_ "GenSigTimeoutTime" SG_ 249 DCDC_MeasInCurrent 50;
BA_ "CycleTime" SG_ 249 DCDC_MeasInCurrent 10;
BA_ "InvalidValue" SG_ 249 DCDC_MeasInCurrent 65535;
BA_ "GenSigTimeoutTime" SG_ 249 DCDC_MeasInVltg 50;
BA_ "CycleTime" SG_ 249 DCDC_MeasInVltg 10;
BA_ "InvalidValue" SG_ 249 DCDC_MeasInVltg 65535;
BA_ "GenSigTimeoutTime" SG_ 249 DCDC_MeasOutCurr 50;
BA_ "CycleTime" SG_ 249 DCDC_MeasOutCurr 10;
BA_ "InvalidValue" SG_ 249 DCDC_MeasOutCurr 65535;
BA_ "GenSigTimeoutTime" SG_ 249 DCDC_MeasVs 50;
BA_ "CycleTime" SG_ 249 DCDC_MeasVs 10;
BA_ "InvalidValue" SG_ 249 DCDC_MeasVs 65535;
BA_ "GenSigTimeoutTime" SG_ 254 DCDC_MaxCurrentOut 50;
BA_ "CycleTime" SG_ 254 DCDC_MaxCurrentOut 10;
BA_ "InvalidValue" SG_ 254 DCDC_MaxCurrentOut 65535;
BA_ "GenSigTimeoutTime" SG_ 254 DCDC_OutCurrReqFbk 50;
BA_ "CycleTime" SG_ 254 DCDC_OutCurrReqFbk 10;
BA_ "InvalidValue" SG_ 254 DCDC_OutCurrReqFbk 65535;
BA_ "GenSigTimeoutTime" SG_ 254 DCDC_OutVltgReqFbk 50;
BA_ "CycleTime" SG_ 254 DCDC_OutVltgReqFbk 10;
BA_ "InvalidValue" SG_ 254 DCDC_OutVltgReqFbk 65535;
BA_ "GenSigTimeoutTime" SG_ 254 DCDC_Status 50;
BA_ "CycleTime" SG_ 254 DCDC_Status 10;
BA_ "InvalidValue" SG_ 254 DCDC_Status 3;
BA_ "GenSigTimeoutTime" SG_ 254 DCDC_EnableDCDCFbk 50;
BA_ "CycleTime" SG_ 254 DCDC_EnableDCDCFbk 10;
BA_ "CycleTime" SG_ 272 ALV_VCU_ChargingConnectionSts 50;
BA_ "GenSigTimeoutTime" SG_ 272 ALV_VCU_ChargingConnectionSts 250;
BA_ "InvalidValue" SG_ 272 ALV_VCU_ChargingConnectionSts 15;
BA_ "CycleTime" SG_ 272 VCU_AcChgGunIn 50;
BA_ "GenSigTimeoutTime" SG_ 272 VCU_AcChgGunIn 250;
BA_ "CycleTime" SG_ 272 CRC_VCU_ChargingConnectionSts 50;
BA_ "GenSigTimeoutTime" SG_ 272 CRC_VCU_ChargingConnectionSts 250;
BA_ "CycleTime" SG_ 272 VCU_DCChgGunIn 50;
BA_ "GenSigTimeoutTime" SG_ 272 VCU_DCChgGunIn 250;
BA_ "CycleTime" SG_ 289 CRC_V_VEH 20;
BA_ "GenSigTimeoutTime" SG_ 289 CRC_V_VEH 100;
BA_ "InvalidValue" SG_ 289 CRC_V_VEH 255;
BA_ "GenSigStartValue" SG_ 289 CRC_V_VEH 255;
BA_ "SigFixedValue" SG_ 289 SecOcDataP2V_VEH "255";
BA_ "CycleTime" SG_ 289 SecOcDataP2V_VEH 20;
BA_ "GenSigTimeoutTime" SG_ 289 SecOcDataP2V_VEH 100;
BA_ "GenSigStartValue" SG_ 289 SecOcDataP2V_VEH 1.84467E+019;
BA_ "SigFixedValue" SG_ 289 QU_V_VEH_COG "1";
BA_ "CycleTime" SG_ 289 QU_V_VEH_COG 20;
BA_ "GenSigTimeoutTime" SG_ 289 QU_V_VEH_COG 100;
BA_ "InvalidValue" SG_ 289 QU_V_VEH_COG 15;
BA_ "GenSigStartValue" SG_ 289 QU_V_VEH_COG 15;
BA_ "CycleTime" SG_ 289 V_VEH_COG 20;
BA_ "GenSigTimeoutTime" SG_ 289 V_VEH_COG 100;
BA_ "InvalidValue" SG_ 289 V_VEH_COG 65535;
BA_ "CycleTime" SG_ 289 ALIV_V_VEH 20;
BA_ "GenSigTimeoutTime" SG_ 289 ALIV_V_VEH 100;
BA_ "InvalidValue" SG_ 289 ALIV_V_VEH 15;
VAL_ 501 VCU_HV_SystemStatus 7 "Signal Invalid" 6 "Reserved" 5 "Reserved" 4 "Error" 3 "Charging" 2 "Ready to Drive" 1 "HV On" 0 "Not Ready" ;
VAL_ 411 OBC_SeqSta 9 "Reserved" 8 "SLEEP" 7 "Terminated" 6 "Interrupted" 255 "Invalid Signal" 254 "Reserved" 5 "Start (Discharging)" 4 "Start (Charging)" 3 "Ready (Discharging)" 2 "Ready (Charging)" 1 "AC/DC Check" 0 "Standby" ;
VAL_ 411 OBC_HvIntlkStatus 3 "Invalid signal" 2 "Reserved" 1 "Interlock Fault" 0 "Normal" ;
VAL_ 634 DCDC_SysOpSta 7 "Reserved" 6 "Sleep" 255 "Invalid Signal" 254 "Reserved" 5 "Terminated" 4 "Interrupted" 3 "Start" 2 "Ready" 1 "DCCheck" 0 "Standby" ;
VAL_ 634 DCDC_HvIntlkStatus 3 "Invalid signal" 2 "Reserved" 1 "Interlock Fault" 0 "Normal" ;
VAL_ 497 STAT_CL15_L 3 "SIGNAL INVALID" 2 "FAILURE" 1 "ON" 0 "OFF" ;
VAL_ 497 STAT_CL30S_L 3 "SIGNAL INVALID" 2 "FAILURE" 1 "ON" 0 "OFF" ;
VAL_ 497 STAT_CL30S_Light 3 "SIGNAL INVALID" 2 "FAILURE" 1 "ON" 0 "OFF" ;
VAL_ 497 STAT_CL15_WUPL 3 "SIGNAL INVALID" 2 "FAILURE" 1 "ON" 0 "OFF" ;
VAL_ 60 CTR_BS_PRTNT 0 "Reserved" 1 "Reserved (Parking_BN_niO)" 2 "IGN OFF (Parking_BN_iO)" 3 "Reserved (Status_Functions)" 4 "Reserved" 5 "Reserved (housing)" 6 "Reserved" 7 "Ignition On" 8 "Reserved (Prepare_readiness Drv)" 9 "Reserved" 10 "Driving" 12 "Reserved (End of readiness Drv)" 13 "Reserved" 14 "Reserved" 15 "Signal_Invalid" ;
VAL_ 60 CTR_FKTN_PRTNT 0 "Configuration off" 1 "Configuration on" 2 "Ethernet infrastructure on" 4 "data_comm_on" 8 "remote maintenance_on" 16 "Climate_Base_on" 32 "Safe_Exit_on" 64 "RSU_high-voltage support_on" 128 "Autonomous_Driving_Ready_on" 256 "Air conditioning mode on" 512 "Entertainment mode on" 1024 "External_communication on" 2048 "Entertainmentbetrieb_Fond_ein" 4096 "Assistance_Parking_high on" 8192 "Autonomous_Drv_Sec_Pwr_Supply_on" 16384 "High_volt_batt_air_condition_on" 32768 "Loading" 65536 "Vehicle infrastructure on" 131072 "light_on" 262144 "TN_48V_on" -2147483648 "Signal_unfilled" ;
VAL_ 60 ST_CON_VEH 9 "Reserved" 6 "Reserved" 4 "Reserved" 0 "Reserved" 1 "Reserved (Parking_BN_niO)" 2 "IGN OFF (Parking_BN_iO)" 3 "Reserved (Status_Functions)" 5 "Reserved (housing)" 7 "Ignition On" 8 "Reserved (Prepare_readiness Drv)" 10 "Driving" 12 "Reserved (End of readiness Drv)" 13 "Reserved" 14 "Reserved" 15 "Signal_Invalid" ;
VAL_ 60 QU_ST_CON_VEH 2 "Signal value valid" 3 "Sig val valid with restrictions" 6 "Reserved_unconverted_ID_error" 14 "value_not_available" 15 "signal empty" ;
VAL_ 130 ST_CRSE_REAR 0 "No crash" 1 "Crash severity 1" 2 "crash severity 2" 3 "crash severity 3" 4 "crash severity 4" 13 "Func_interface_is_not_avail" 14 "Function_reports_error" 15 "signal_unfilled" ;
VAL_ 130 ST_CRSE_ROV 0 "No crash" 1 "Crash severity 1" 2 "crash severity 2" 3 "crash severity 3" 4 "crash severity 4" 13 "Func_interface_is_not_avail" 14 "Function_reports_error" 15 "signal_unfilled" ;
VAL_ 130 ST_CRSE_SIDE_LH 0 "No crash" 1 "Crash severity 1" 2 "crash severity 2" 3 "crash severity 3" 4 "crash severity 4" 13 "Func_interface_is_not_avail" 14 "Function_reports_error" 15 "signal_unfilled" ;
VAL_ 130 ST_CRSE_SIDE_RH 0 "No crash" 1 "Crash severity 1" 2 "crash severity 2" 3 "crash severity 3" 4 "crash severity 4" 13 "Func_interface_is_not_avail" 14 "Function_reports_error" 15 "signal_unfilled" ;
VAL_ 130 ST_CRSE_FRT 0 "No crash" 1 "Crash severity 1" 2 "crash severity 2" 3 "crash severity 3" 4 "crash severity 4" 13 "Func_interface_is_not_avail" 14 "Function_reports_error" 15 "signal_unfilled" ;
VAL_ 131 QU_AVL_RPM_WHL_RLH 1 "Signal valid secured plausible" 2 "Reserved" 3 "Reserved" 4 "Sub value set in useful signal" 6 "value_not_available_fault_elec" 7 "Reserved" 8 "Initialization" 9 "Reserved" 10 "Reserved" 11 "Sig quality monitor restricted" 12 "Sub value signal Stat Temp" 14 "Val_not_avail_plausibility error" 15 "Signal invalid" ;
VAL_ 131 QU_AVL_RPM_WHL_RRH 1 "Signal valid secured plausibile" 2 "Reserved" 3 "Reserved" 4 "Sub value set in useful signal" 6 "value_not_available_fault_elec" 7 "Reserved" 8 "Initialization" 9 "Reserved" 10 "Reserved" 11 "Sig quality monitor restricted" 12 "Sub value signal Stat Temp" 14 "Val_not_avail_plausibility error" 15 "Signal invalid" ;
VAL_ 131 QU_AVL_RPM_WHL_FLH 1 "Signal valid secured plausibile" 2 "Reserved" 3 "Reserved" 4 "Sub value set in useful signal" 6 "value_not_available_fault_elec" 7 "Reserved" 8 "Initialization" 9 "Reserved" 10 "Reserved" 11 "Sig quality monitor restricted" 12 "Sub value signal Stat Temp" 14 "Val_not_avail_plausibility error" 15 "Signal invalid" ;
VAL_ 131 QU_AVL_RPM_WHL_FRH 1 "Signal valid secured plausible" 2 "Reserved" 3 "Reserved" 4 "Sub value set in useful signal" 6 "value_not_available_fault_elec" 7 "Reserved" 8 "Initialization" 9 "Reserved" 10 "Reserved" 11 "Sig quality monitor restricted" 12 "Sub value signal Stat Temp" 14 "Val_not_avail_plausibility error" 15 "Signal invalid" ;
VAL_ 132 BMS_ChargeStopReq 0 "Request OFF" 1 "Request ON" 2 "Reserved" 3 "Reserved" ;
VAL_ 137 BMS_PackCurMeas 65535 "Signal Invalid" ;
VAL_ 137 BMS_StartOfMeasument_STS 0 "Not start" 1 "Started" ;
VAL_ 138 OperatingModeETract1Target 0 "standby" 1 "Torque control" 2 "zero torque control" 3 "DC_Voltage Control" 5 "Speed_ctrl_with_torque pre ctrl" 6 "IHVBCTL_with_torque pre-control" 7 "VoKo_trimming" 8 "Insulation test" 10 "Freewheel" 12 "external_request_safe_state" 15 "Intermediate actv crct dschrg" 31 "Shut_off_path_test_requested" 186 "speed control" 253 "Func_interface_is_not_avail" 254 "Function_reports_error" 255 "signal_unfilled" ;
VAL_ 138 OperatingModeETract2Target 0 "standby" 1 "Torque control" 2 "zero torque control" 3 "DC_Voltage Control" 5 "Speed_ctrl_with_torque pre ctrl" 6 "IHVBCTL_with_torque pre-control" 7 "VoKo_trimming" 8 "Insulation test" 10 "Freewheel" 12 "external_request_safe_state" 15 "Intermediate actv crct dschrg" 31 "Shut_off_path_test_requested" 186 "speed control" 253 "Func_interface_is_not_avail" 254 "Function_reports_error" 255 "signal_unfilled" ;
VAL_ 141 TargetEMRpmETractSys2 4093 "Func_interface_is_not_avail" 4094 "Function_reports_error" 4095 "Signal_unfilled" ;
VAL_ 141 StatusReleaseTorqueVerified 0 "initial" 1 "Torque_buildup_not_allowed" 2 "Torque buildup_allowed" 3 "Torque build-up_FuSa_Switch off" 13 "Funct_interface_is_not_avail" 14 "Function_reports_error" 15 "signal_unfilled" ;
VAL_ 141 StatusDampingVibration 0 "Actv_vibration_dmp_not_switch on" 1 "Active_vibration_dmp_over_VM" 2 "Active_vibration_dmp_over_EM1" 4 "Active_vibration_dmp_over_EM2" 13 "Func_interface_is_not_avail" 14 "Function_reports_error" 15 "Signal_unfilled" ;
VAL_ 141 TorqBoundaryETractSys2EmNCtrlMin 4093 "Func_interface_is_not_avail" 4094 "Function_reports_error" 4095 "Signal_unfilled" ;
VAL_ 141 TorqBoundaryETractSys2EmNCtrlMax 4093 "Func_interface_is_not_avail" 4094 "Function_reports_error" 4095 "Signal_unfilled" ;
VAL_ 141 TorqBoundaryETractSys1EmNCtrlMin 4093 "Func_interface_is_not_avail" 4094 "Function_reports_error" 4095 "Signal_unfilled" ;
VAL_ 141 TorqBoundaryETractSys1EmNCtrlMax 4093 "Func_interface_is_not_avail" 4094 "Function_reports_error" 4095 "Signal_unfilled" ;
VAL_ 141 TargetTorqueEmETractSys2 4093 "Func_interface_is_not_avail" 4094 "Function_reports_error" 4095 "Signal_unfilled" ;
VAL_ 141 TargetEMRpmETractSys1 4093 "Func_interface_is_not_avail" 4094 "Function_reports_error" 4095 "Signal_unfilled" ;
VAL_ 141 TargetTorqueEmETractSys1 4093 "Func_interface_is_not_avail" 4094 "Function_reports_error" 4095 "Signal_unfilled" ;
VAL_ 143 ActualValueVoltageLinkVerified 4093 "Func_interface_is_not_avail" 4094 "Function_reports_error" 4095 "Signal_unfilled" ;
VAL_ 145 PwrLossPrednETractSys1Genr 4093 "Func_interface_is_not_avail" 4094 "Function_reports_error" 4095 "Signal_unfilled" ;
VAL_ 145 PwrLossPrednETractSys1Mot 4093 "Func_interface_is_not_avail" 4094 "Function_reports_error" 4095 "Signal_unfilled" ;
VAL_ 145 TarTqETractSys1NControlStatic 1021 "Func_interface_is_not_avail" 1022 "Function_reports_error" 1023 "Signal_unfilled" ;
VAL_ 145 PowerETractSys1LossActualValue 4093 "Func_interface_is_not_avail" 4094 "Function_reports_error" 4095 "Signal_unfilled" ;
VAL_ 145 StETractSys1Asd 0 "No_ASD_deactivation" 1 "ASD_dctv_no_posi_lock_recog" 2 "ASD_dis_because_of_speed_control" 4 "ASD_deactivated_due_wheel_slip" 8 "ASD_deactivated_ABS_intervention" 16 "ASD_disabled_ASC_intervention" 32 "ASD_dis_due_to_ARB_intervention" 64 "ASD_disabled_FDR_intervention" 128 "ASD_dis_due_to_BTS_intrusion" 256 "ASD_dctv_due_to_hard_braking" 512 "ASD_disabled_mileage_mode" 1024 "ASD_dctv_by_diagnostic_service" 2048 "ASD_deactv_E-machine_oprtng_mod" 4096 "ASD_dctv_due_to_emrgncy shtdwn" 8192 "ASD_dis_due_whl_spd_signal_error" 65533 "Func_interface_is_not_avail" 65534 "Function_reports_error" 65535 "Signal_unfilled" ;
VAL_ 145 SumWhlTqIntvETractSys1 4093 "Func_interface_is_not_avail" 4094 "Function_reports_error" 4095 "Signal_unfilled" ;
VAL_ 145 StatusArbRpmETractSys1Limit 0 "speed_limit_thresh_passive" 1 "Speed_limit_upper_thresh_actv" 2 "speed_limit_lwr_thresh_actv" 4 "fallback level" 13 "Function_interface_is_not_avail" 14 "Function_reports_error" 15 "Signal_unfilled" ;
VAL_ 145 Qu_CurrDrctCurrETractSys1ActVal 1 "value_valid_highest_quality" 2 "value_valid_simple_quality" 3 "Value_valid_restricted" 4 "Value_valid_substitute value" 6 "value_not_available_error" 9 "value_valid_medium_quality" 14 "value_not_available" 15 "signal_invalid" ;
VAL_ 145 QualifierRpmEmETractSys1ActVal 1 "value_valid_highest_quality" 2 "value_valid_simple_quality" 3 "Value_valid_restricted" 4 "Value_valid_substitute value" 6 "value_not_available_error" 9 "value_valid_medium_quality" 14 "value_not_available" 15 "signal_invalid" ;
VAL_ 145 QualifierTqEmETractSys1ActVal 1 "value_valid_highest_quality" 2 "value_valid_simple_quality" 3 "Value_valid_restricted" 4 "Value_valid_substitute value" 6 "value_not_available_error" 9 "value_valid_medium_quality" 14 "value_not_available" 15 "signal_invalid" ;
VAL_ 145 StatusPbWETractSys1 0 "No_Error" 1 "position sensor1_not_ok" 2 "Position sensor2_not_ok" 4 "Limited avail Park lck actuator" 8 "Park lock actuator is not avail" 16 "Control unit error" 253 "Func_interface_is_not_avail" 254 "Function_reports_error" 255 "signal_unfilled" ;
VAL_ 145 OVCUrrenceStatorPWMETractSys1 0 "Effective_PWM_applied" 1 "No_effective_PWM_applied" 3 "signal_unfilled" ;
VAL_ 145 TqEmETractSys1MotorSumLimTarget 4093 "Func_interface_is_not_avail" 4094 "Function_reports_error" 4095 "Signal_unfilled" ;
VAL_ 145 TorqueEmETractSys1ActualValue 4093 "Func_interface_is_not_avail" 4094 "Function_reports_error" 4095 "Signal_unfilled" ;
VAL_ 145 TorqueEmETractSys1MotorDynamic 4093 "Func_interface_is_not_avail" 4094 "Function_reports_error" 4095 "Signal_unfilled" ;
VAL_ 145 TorqueEmETractSys1MotorStatic 4093 "Func_interface_is_not_avail" 4094 "Function_reports_error" 4095 "Signal_unfilled" ;
VAL_ 145 TqEmETractSys1GeneratorDynamic 4093 "Func_interface_is_not_avail" 4094 "Function_reports_error" 4095 "Signal_unfilled" ;
VAL_ 145 TqEmETractSys1GeneratorStatic 4093 "Func_interface_is_not_avail" 4094 "Function_reports_error" 4095 "Signal_unfilled" ;
VAL_ 145 RpmEmETractSys1ActualValue 65533 "Func_interface_is_not_avail" 65534 "Function_reports_error" 65535 "Signal_unfilled" ;
VAL_ 145 TqEmETractSys1VibrationDampSusp 4093 "Func_interface_is_not_avail" 4094 "Function_reports_error" 4095 "Signal_unfilled" ;
VAL_ 145 RpmEmETractSys1MinimumLimit 65533 "Func_interface_is_not_avail" 65534 "Function_reports_error" 65535 "Signal_unfilled" ;
VAL_ 145 RpmEmETractSys1MaximumLimit 65533 "Func_interface_is_not_avail" 65534 "Function_reports_error" 65535 "Signal_unfilled" ;
VAL_ 145 VolDrctCurrETractSys1ActVal 4093 "Func_interface_is_not_avail" 4094 "Function_reports_error" 4095 "Signal_unfilled" ;
VAL_ 145 CurrDrctCurrETractSys1ActVal 65533 "Func_interface_is_not_avail" 65534 "Function_reports_error" 65535 "Signal_unfilled" ;
VAL_ 145 DirOfRotETractSys1ActVal 0 "no_set_direction" 1 "direction of rotation_forward" 2 "Direction of rotation_reverse" 3 "signal_unfilled" ;
VAL_ 145 StatusLockPositionPbWETractSys1 0 "initial" 1 "parking lock_closed" 2 "Parking lock_opened" 3 "Park lock_in_intermediate pos" 12 "Parking lock_position_invalid" 13 "Func_interface_is_not_avail" 14 "Function_reports_error" 15 "signal_unfilled" ;
VAL_ 146 CTR_ERRM_BN_U 0 "No overvoltage" 1 "undervoltage normal operation" 2 "Undervoltage MSA start" 4 "overvoltage" 61 "Func_interface_is_not_available" 62 "Function_reports_error" 63 "signal_unfilled" ;
VAL_ 162 BMS_PackLowVolErr 0 "Normal" 1 "Warning" 2 "Error" 3 "Safety Error" ;
VAL_ 162 BMS_PackOverCurrErr 0 "Normal" 1 "Warning" 2 "Error" 3 "Safety Error" ;
VAL_ 162 BMS_CellLowVolErr 0 "Normal" 1 "Warning" 2 "Error" 3 "Safety Error" ;
VAL_ 162 BMS_HVILErr 0 "Normal" 1 "Level1" 2 "Level2" 3 "Level3" ;
VAL_ 162 BMS_FuseStatusErr 0 "Normal" 1 "Fuse Blown" ;
VAL_ 162 BMS_ProbeHighTempErr 0 "Normal" 1 "Warning" 2 "Error" 3 "Safety Error" ;
VAL_ 162 BMS_CellHighVolErr 0 "Normal" 1 "Warning" 2 "Error" 3 "Safety Error" ;
VAL_ 162 BMS_ProbeLowTempErr 0 "Normal" 1 "Warning" 2 "Error" 3 "Safety Error" ;
VAL_ 162 BMS_PackHighVolErr 0 "Normal" 1 "Warning" 2 "Error" 3 "Safety Error" ;
VAL_ 162 BMS_ProbeTempDiffErr 0 "Normal" 1 "Warning" 2 "Error" 3 "Safety Error" ;
VAL_ 162 BMS_CellVoltDiffErr 0 "Normal" 1 "Warning" 2 "Error" 3 "Safety Error" ;
VAL_ 162 BMS_PackInsuErr 0 "Normal" 1 "Level1" 2 "Level2" 3 "Level3" ;
VAL_ 170 QualifierRpmEmETractSys2ActVal 1 "value_valid_highest_quality" 2 "value_valid_simple_quality" 3 "Value_valid_restricted" 4 "Value_valid_substitute value" 6 "value_not_available_error" 9 "value_valid_medium_quality" 14 "value_not_available" 15 "signal_invalid" ;
VAL_ 170 DirOfRotETractSys2ActVal 0 "no_set_direction" 1 "direction of rotation_forward" 2 "Direction of rotation_reverse" 3 "signal_unfilled" ;
VAL_ 170 TqEmETractSys2MotorSumLimTarget 4093 "Func_interface_is_not_avail" 4094 "Function_reports_error" 4095 "Signal_unfilled" ;
VAL_ 170 StatusLockPositionPbWETractSys2 0 "initial" 1 "parking lock_closed" 2 "Parking lock_opened" 3 "Park lock_in_intermediate pos" 12 "Parking lock_position_invalid" 13 "Func_interface_is_not_avail" 14 "Function_reports_error" 15 "signal_unfilled" ;
VAL_ 170 TorqueEmETractSys2ActualValue 4093 "Func_interface_is_not_avail" 4094 "Function_reports_error" 4095 "Signal_unfilled" ;
VAL_ 170 TorqueEmETractSys2MotorDynamic 4093 "Func_interface_is_not_avail" 4094 "Function_reports_error" 4095 "Signal_unfilled" ;
VAL_ 170 TqEmETractSys2GeneratorDynamic 4093 "Func_interface_is_not_avail" 4094 "Function_reports_error" 4095 "Signal_unfilled" ;
VAL_ 170 TqEmETractSys2GeneratorStatic 4093 "Func_interface_is_not_avail" 4094 "Function_reports_error" 4095 "Signal_unfilled" ;
VAL_ 170 RpmEmETractSys2ActualValue 65533 "Func_interface_is_not_avail" 65534 "Function_reports_error" 65535 "Signal_unfilled" ;
VAL_ 170 TqEmETractSys2VibrationDampSusp 4093 "Func_interface_is_not_avail" 4094 "Function_reports_error" 4095 "Signal_unfilled" ;
VAL_ 170 RpmEmETractSys2MinimumLimit 65533 "Func_interface_is_not_avail" 65534 "Function_reports_error" 65535 "Signal_unfilled" ;
VAL_ 170 RpmEmETractSys2MaximumLimit 65533 "Func_interface_is_not_avail" 65534 "Function_reports_error" 65535 "Signal_unfilled" ;
VAL_ 170 VolDrctCurrETractSys2ActVal 4093 "Func_interface_is_not_avail" 4094 "Function_reports_error" 4095 "Signal_unfilled" ;
VAL_ 170 CurrDrctCurrETractSys2ActVal 65533 "Func_interface_is_not_avail" 65534 "Function_reports_error" 65535 "Signal_unfilled" ;
VAL_ 170 TorqueEmETractSys2MotorStatic 4093 "Func_interface_is_not_avail" 4094 "Function_reports_error" 4095 "Signal_unfilled" ;
VAL_ 170 QualifierTqEmETractSys2ActVal 1 "value_valid_highest_quality" 2 "value_valid_simple_quality" 3 "Value_valid_restricted" 4 "Value_valid_substitute value" 6 "value_not_available_error" 9 "value_valid_medium_quality" 14 "value_not_available" 15 "signal_invalid" ;
VAL_ 170 OVCUrrenceStatorPWMETractSys2 0 "Effective_PWM_applied" 1 "No_effective_PWM_applied" 3 "signal_unfilled" ;
VAL_ 170 StETractSys2Asd 0 "No_ASD_dctv_due_to_ARB_intrusion" 1 "ASD_dctv_no_posi_lock_recog" 2 "ASD_disabled_of_speed_control" 4 "ASD_deactivated_due_wheel_slip" 8 "ASD_deactivated_ABS_intervention" 16 "ASD_disabled_ASC_intervention" 32 "ASD_dis_due_to_ARB_intervention" 64 "ASD_disabled_FDR_intervention" 128 "ASD_dis_due_to_BTS_intrusion" 256 "ASD_dctv_due_to_hard_braking" 512 "ASD_disabled_of_mileage_mode" 1024 "ASD_dctv_by_diagnostic_service" 2048 "ASD_dctv_E-machine_oprtng_mod" 4096 "ASD_dctv_due_to_emrgncy_shtdwn" 8192 "ASD_dis_due_whl_spd_signal_error" 65533 "Func_interface_is_not_avail" 65534 "Function_reports_error" 65535 "Signal_unfilled" ;
VAL_ 170 Qu_CurrDrctCurrETractSys2ActVal 1 "value_valid_highest_quality" 2 "value_valid_simple_quality" 3 "Value_valid_restricted" 4 "Value_valid_substitute value" 6 "value_not_available_error" 9 "value_valid_medium_quality" 14 "value_not_available" 15 "signal_invalid" ;
VAL_ 170 StatusArbRpmETractSys2Limit 0 "speed_limit_thresh_passive" 1 "Speed_limit_upper_thresh_actv" 2 "speed_limit_lwr_thresh_actv" 4 "fallback level" 13 "Func_interface_is_not_avail" 14 "Function_reports_error" 15 "Signal_unfilled" ;
VAL_ 170 SumWhlTqIntvETractSys2 4093 "Func_interface_is_not_avail" 4094 "Function_reports_error" 4095 "Signal_unfilled" ;
VAL_ 170 StatusPbWETractSys2 0 "No_Error" 1 "position sensor1_not_ok" 2 "Position sensor2_not_ok" 4 "Park lock actuator_rstrct_avail" 8 "Park lock actuator_not_avail" 16 "Control unit error" 253 "Func_interface_is_not_avail" 254 "Function_reports_error" 255 "signal_unfilled" ;
VAL_ 170 PowerETractSys2LossActualValue 4093 "Func_interface_is_not_avail" 4094 "Function_reports_error" 4095 "Signal_unfilled" ;
VAL_ 170 TarTqETractSys2NControlStatic 1021 "Func_interface_is_not_avail" 1022 "Function_reports_error" 1023 "Signal_unfilled" ;
VAL_ 170 PwrLossPrednETractSys2Mot 4093 "Func_interface_is_not_avail" 4094 "Function_reports_error" 4095 "Signal_unfilled" ;
VAL_ 170 PwrLossPrednETractSys2Genr 4093 "Func_interface_is_not_avail" 4094 "Function_reports_error" 4095 "Signal_unfilled" ;
VAL_ 172 BMS_MaxDischgCurrentLimPeak 65535 "Invalid Signal" ;
VAL_ 172 BMS_MaxDischgCurrentLim 65535 "Invalid Signal" ;
VAL_ 172 BMS_MaxDischgCurrent30s 65535 "Invalid Signal" ;
VAL_ 172 BMS_MaxDischgCurrent10s 65535 "Invalid Signal" ;
VAL_ 172 BMS_MaxDischgCurrent2s 65535 "Invalid Signal" ;
VAL_ 177 BMS_MainPosRelayStatus 4 "stuck open" 3 "stuck closed" 2 "closed" 1 "open" 0 "reserved" ;
VAL_ 177 BMS_PreChgRelayStatus 4 "stuck open" 3 "stuck closed" 2 "closed" 1 "open" 0 "reserved" ;
VAL_ 177 BMS_TotalNegRelayStatus 4 "stuck open" 3 "stuck closed" 2 "closed" 1 "open" 0 "reserved" ;
VAL_ 177 BMS_MainPosRelayErr 1 "normal" 0 "Error" ;
VAL_ 177 BMS_TotalNegRelayErr 1 "normal" 0 "Error" ;
VAL_ 177 BMS_PreChgRelayErr 1 "normal" 0 "error" ;
VAL_ 177 BMS_DCFCPosRelayStatus 4 "stuck open" 3 "stuck closed" 2 "closed" 1 "open" 0 "reserved" ;
VAL_ 177 BMS_DCFCNegRelayStatus 4 "stuck open" 3 "stuck closed" 2 "closed" 1 "open" 0 "reserved" ;
VAL_ 177 BMS_DCFCPosRelayErr 1 "normal" 0 "Error" ;
VAL_ 177 BMS_DCFCNegRelayErr 1 "normal" 0 "Error" ;
VAL_ 182 BMS_HVOnOffSts 0 "HV Off" 1 "Pre-charge" 2 "HV On" 3 "Super_Fast_Charge" 4 "AC_Charge" 5 "Undefined" 6 "Undefined" 7 "Undefined" 8 "Undefined" 9 "Undefined" ;
VAL_ 182 BMS_BatBalanceErr 0 "Error" 1 "Normal" ;
VAL_ 182 BMS_ErrLev 0 "No error" 1 "Warning" 2 "Limp Home" 3 "Power down without FTTI" 4 "Delay power down with FTTI" 5 "Emergency off condition" 6 "Fault, shutdown and wakeup" 7 "Battery locked - reserved" ;
VAL_ 182 BMS_DisconnectRequestRsn 0 "No off request" 1 "HVIL error" 2 "Insulation error" 3 "Cell under voltage error" 4 "Cell over voltage error" 5 "Cell voltage diff error" 6 "Pack over voltage error" 7 "Pack under voltage error" 8 "Cell under temperature error" 9 "Cell over temperature error" 10 "Temperature diff error" 11 "Fuse/pyrofuse blowup error" 12 "Pack overcurrent error" ;
VAL_ 182 BMS_EmergencyDisconnectRsn 0 "No emergency off" 1 "Reserved" 2 "Reserved" 3 "Reserved" 4 "Reserved" 5 "Reserved" 6 "Reserved" 7 "Reserved" 8 "Reserved" ;
VAL_ 182 BMS_LimpHomeRsn 0 "No limp home" 1 "Pack temperature warning" 2 "Thermal runaway warning" 3 "Low battery warning" 4 "Reserved" 5 "Reserved" 6 "Reserved" 7 "Reserved" 8 "Reserved" ;
VAL_ 182 BMS_HVILSts 0 "Closed" 1 "Open & short to battery" 2 "short to ground" ;
VAL_ 182 BMS_HWCrashSts 0 "Crash" 1 "No Crash" ;
VAL_ 182 BMS_BalanceSts 0 "Inactive" 1 "Active" ;
VAL_ 182 BMS_SysSts 0 "Initialize pwr on, self check" 1 "Self-check passes, high-volt" 2 "Successful High Voltage Power Up" 3 "Successful Power Down of HV" 4 "Power Down process" 5 "Successful power down" 6 "BCU Sleep mode" 7 "Failure, unable to operate" 8 "Invalid" ;
VAL_ 182 BMS_IGNSts 0 "OFF" 1 "ON" ;
VAL_ 187 BMS_Warning_Flag_5 0 "No Error" 1 "Error" ;
VAL_ 187 BMS_Warning_Flag_6 0 "No Error" 1 "Error" ;
VAL_ 187 BMS_MalfunctionSts 0 "No Warning" 1 "Warning" ;
VAL_ 187 BMS_BatteryReplacement 0 "No Warning" 1 "Warning" ;
VAL_ 187 BMS_ThermalRunaway 0 "No Warning" 1 "Warning" ;
VAL_ 187 BMS_PackTempSts 0 "No warning" 1 "Over Temperature Warning" 2 "Under Temperature Warning" ;
VAL_ 187 BMS_Warning_Flag_7 0 "No Error" 1 "Error" ;
VAL_ 187 BMS_LowBattery 0 "No warning" 1 "Low level" 2 "Extremely low level" ;
VAL_ 187 BMS_Warning_Flag_8 0 "No Error" 1 "Error" ;
VAL_ 187 BMS_Warning_Flag_9 0 "No Error" 1 "Error" ;
VAL_ 213 QU_FN_FDR 0 "Internal_Information" 512 "Fn avail ready not active normal" 516 "Fn avail ready not active widen" 768 "Reserved" 776 "reserved" 1536 "Func not avail error" 2048 "reserved" 2560 "Fn avail ready active normal" 2568 "Fn avail ready active widen" 2576 "Fn avail active FDR control FL" 2592 "Fn avail active FDR control FR" 2624 "Fn avail active FDR control RL" 2688 "Fn avail active FDR control RR" 3584 "Fn not avail switched off" 4095 "Invalid signal" ;
VAL_ 213 QU_FN_ABS 512 "ABS func avail no ctrl interven" 768 "ABS fallback LvL no ctrl interv" 1536 "ABS func not avail error" 2048 "reserved" 2576 "ABS func active ctrl interven FL" 2592 "ABS func active ctrl interven FR" 2624 "ABS func active ctrl interven RL" 2688 "ABS func active ctrl interven RR" 2832 "ABS fallbck LvL ctrl interven VL" 2848 "ABS fallbck LvL ctrl interven VR" 2880 "ABS fallbck LvL ctrl interven HL" 2944 "ABS fallbck LvL ctrl interven HR" 3584 "ABS func not avail standby" 4095 "Invalid signal" ;
VAL_ 213 QU_FN_ASC 512 "Func_avail_ready_not_actv_normal" 514 "Func_avail_ready_not_actv_PreASC" 520 "Func_avail_ready_not_actv_expand" 768 "Fn_flbck_LvL_Rdy_PreASC_not_actv" 770 "Fn_flbck_LvL_Rdy_PreASC_actv" 776 "Fn_flbck_LvL_Rdy_slip_extended" 1536 "Func_reports_error" 2560 "ASC_func_actv_PreASC_not_actv" 2562 "ASC_func_actv_PreASC_actv" 2564 "ASC_func_actv_negative_slip" 2568 "ASC_func_actv_slip_expanded" 2576 "ASC_func_actv_ASC_ctr_interve_FL" 2592 "ASC_func_actv_ASC_ctr_interve_FR" 2624 "ASC_func_actv_ASC_ctr_interve_RL" 2688 "ASC_func_actv_ASC_ctr_interve_RR" 2816 "ASC_temp_flbk_LvL_PreASC_not_act" 2818 "ASC_temp_flbk_LvL_PreASC_actv" 2820 "ASC_temp_flbk_negative_slip" 2824 "ASC_temp_flbk_slip_expanded" 2832 "ASC_temp_flbk_LvL_ASC_ctr_VL" 2848 "ASC_temp_flbk_LvL_ASC_ctr_VR" 2880 "ASC_temp_flbk_LvL_ASC_ctr_HL" 2944 "ASC_temp_flbk_LvL_ASC_ctr_HR" 3584 "Fn_inter_not_avail_switch_off" 3586 "Fn_not_avail_swch_off_PrASC_act" 4095 "Signal_unfilled" ;
VAL_ 213 ST_BRG_DV 0 "Vehicle not secured by braking" 1 "brake pedal actuation path1" 2 "brake pedal actuation path2" 4 "Driver braking system actuation" 8 "Brake system activation by IDB" 16 "Vehicle secured by braking" 32 "initialization" 63 "Invalid signal" ;
VAL_ 214 ST_SLIP_THO 0 "slip_thresholds_no_wheel_exceed" 1 "Slip_thresh_excd_atlst_1rear_whl" 2 "Slip_thresh_excd_atlst_1frnt_whl" 13 "Func_interface_is_not_avail" 14 "Function_reports_error" 15 "Signal_unfilled" ;
VAL_ 217 QU_AVL_WMOM_PT_SUM 1 "reserved" 2 "Signal value is valid" 3 "Signal quality or monit restrict" 4 "reserved" 6 "Signal value is invalid" 7 "reserved" 8 "Initialization" 9 "reserved" 10 "signal val valid, cond stat temp" 11 "reserved" 12 "Adjstmnt val set, cond stat temp" 14 "reserved" 15 "Signal invalid" ;
VAL_ 254 DCDC_Status 0 "Normal" 1 "De-rating" 2 "Fault" 3 "Signal Invalid" ;
VAL_ 254 DCDC_EnableDCDCFbk 0 "Disabled" 1 "Enabled" ;
VAL_ 272 VCU_AcChgGunIn 0 "Disconnect" 1 "Connect" ;
VAL_ 272 VCU_DCChgGunIn 0 "Disconnect" 1 "Connect" ;
VAL_ 289 QU_V_VEH_COG 1 "Sig val valid secured plausible" 2 "Reserved" 3 "Reserved" 4 "Reserved" 6 "Reserved" 7 "Reserved" 8 "Initialization" 9 "Reserved" 10 "signal val valid, cond stat temp" 11 "Signal quality restrict temp" 12 "Reserved" 14 "Signal value invalid stat temp" 15 "Signal invalid" ;
